VERSION ""

NS_ :

BS_ :

BU_ : ATX ECU EIC PBS PDC PDE PTP

BO_ 2565406464 Acknowledgment_ECU: 8 ECU

BO_ 2565406467 Acknowledgment_PBS: 8 PBS

BO_ 2565406706 Acknowledgment_PDC: 8 PDC

BO_ 2565406655 Acknowledgment_PDE: 8 PDE

BO_ 2565341952 Acknowledgment_TX_ECU_RX_PBS: 8 ECU

BO_ 2565403136 Acknowledgment_TX_ECU_RX_PDC: 8 ECU

BO_ 2565390080 Acknowledgment_TX_ECU_RX_PDE: 8 ECU

BO_ 2565341187 Acknowledgment_TX_PBS_RX_ECU: 8 PBS

BO_ 2565403139 Acknowledgment_TX_PBS_RX_PDC: 8 PBS

BO_ 2565390083 Acknowledgment_TX_PBS_RX_PDE: 8 PBS

BO_ 2565341955 Acknowledgment_TX_PBS_RX_PTP: 8 PBS

BO_ 2565341426 Acknowledgment_TX_PDC_RX_ECU: 8 PDC

BO_ 2565342194 Acknowledgment_TX_PDC_RX_PBS: 8 PDC

BO_ 2565390322 Acknowledgment_TX_PDC_RX_PDE: 8 PDC

BO_ 2565341375 Acknowledgment_TX_PDE_RX_ECU: 8 PDE

BO_ 2565342143 Acknowledgment_TX_PDE_RX_PBS: 8 PDE

BO_ 2565403327 Acknowledgment_TX_PDE_RX_PDC: 8 PDE

BO_ 2565799680 Address_Claimed_ECU: 8 ECU

BO_ 2565799683 Address_Claimed_PBS: 8 PBS

BO_ 2565799922 Address_Claimed_PDC: 8 PDC

BO_ 2565799871 Address_Claimed_PDE: 8 PDE

BO_ 2566757120 AfteDiesExhaFluiInfo_ECU: 8 ECU
 SG_ AftrtrtmntDEFConc : 8|8@1+ (0.25,0) [0|62.5] ""  Vector__XXX
 SG_ AftrtrtmntDEFProp : 40|4@1+ (1,0) [0|15] ""  Vector__XXX

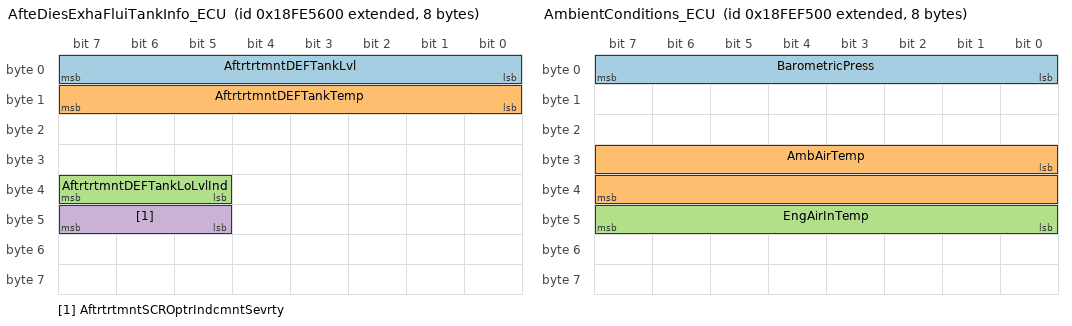
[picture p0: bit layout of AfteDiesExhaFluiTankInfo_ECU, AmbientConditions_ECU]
BO_ 2566804992 AfteDiesExhaFluiTankInfo_ECU: 8 ECU
 SG_ AftrtrtmntDEFTankLvl : 0|8@1+ (0.4,0) [0|100] ""  PDC
 SG_ AftrtrtmntDEFTankTemp : 8|8@1+ (1,-40) [-40|210] ""  Vector__XXX
 SG_ AftrtrtmntDEFTankLoLvlInd : 37|3@1+ (1,0) [0|7] ""  PDC
 SG_ AftrtrtmntSCROptrIndcmntSevrty : 45|3@1+ (1,0) [0|7] ""  EIC,PDC

BO_ 2566748928 Aftertreatment1Service_ECU: 8 ECU
 SG_ PartTrap1TimeSinceLastActReg : 16|32@1+ (1,0) [0|4211081215] ""  Vector__XXX

BO_ 2566763264 AftertreatmentOutletGas2_ECU: 8 ECU
 SG_ AftrDiesPartFltrOutlGasTemp : 16|16@1+ (0.03125,-273) [-273|1735] ""  Vector__XXX

BO_ 2566700288 AfteSCRServInfo2_ECU: 8 ECU
 SG_ AftrtrtmntTotalDEFUsed : 0|32@1+ (0.5,0) [0|2105540607.5] ""  Vector__XXX

BO_ 2565874432 AfteTreaSCRDosiSystInfo_ECU: 8 ECU
 SG_ AftrTrtmDiesExhsFldActDsngQty : 0|16@1+ (0.3,0) [0|19276.5] ""  Vector__XXX

BO_ 2566845696 AmbientConditions_ECU: 8 ECU
 SG_ BarometricPress : 0|8@1+ (0.5,0) [0|125] ""  PDC
 SG_ AmbAirTemp : 24|16@1+ (0.03125,-273) [-273|1735] "NoUnit3"  PDC
 SG_ EngAirInTemp : 40|8@1+ (1,-40) [-40|210] ""  PDC

BO_ 2564292352 Binary_Data_Transfer_ECU: 8 ECU

BO_ 2628387070 ClieECUtoFileServ_TX_Vector__XXX_RX_ECU: 8 Vector__XXX

BO_ 2628387838 ClieECUtoFileServ_TX_Vector__XXX_RX_PBS: 8 Vector__XXX

BO_ 2628449022 ClieECUtoFileServ_TX_Vector__XXX_RX_PDC: 8 Vector__XXX

BO_ 2628435966 ClieECUtoFileServ_TX_Vector__XXX_RX_PDE: 8 Vector__XXX

BO_ 2628452350 Client_ECU_to_File_Server_Vector__XXX: 8 Vector__XXX

BO_ 2566838272 Commanded_Address_ECU: 9 ECU

BO_ 2566838275 Commanded_Address_PBS: 9 PBS

BO_ 2566838514 Commanded_Address_PDC: 9 PDC

BO_ 2566838463 Commanded_Address_PDE: 9 PDE

BO_ 2298409219 CruiseControlVehicleSpeed_PBS: 8 PBS
 SG_ WheelBasedVehicleSpeed : 8|16@1+ (0.00390625,0) [0|250.996] "KiloMtrPerHr"  EIC,PDC
 SG_ BrakeSwitch : 28|2@1+ (1,0) [0|3] ""  PDC

BO_ 2566850816 DiagDeviIdenTLA_ECU: 8 ECU
 SG_ DIAGTLA : 0|24@1+ (1,0) [0|0] ""  PBS,PDC,PDE,PTP

BO_ 2566850819 DiagDeviIdenTLA_PBS: 8 PBS
 SG_ DIAGTLA : 0|24@1+ (1,0) [0|0] ""  ECU,PDC,PDE,PTP

BO_ 2566851058 DiagDeviIdenTLA_PDC: 8 PDC
 SG_ DIAGTLA : 0|24@1+ (1,0) [0|0] ""  ECU,PBS,PDE,PTP

BO_ 2566851007 DiagDeviIdenTLA_PDE: 8 PDE
 SG_ DIAGTLA : 0|24@1+ (1,0) [0|0] ""  ECU,PBS,PDC,PTP

BO_ 2566730243 Diagnostic_Protocol_PBS: 8 PBS

BO_ 2566730431 Diagnostic_Protocol_PDE: 8 PDE

BO_ 2562719507 Diagnostic_Window_Shade_ATX: 8 ATX

BO_ 2562719488 Diagnostic_Window_Shade_ECU: 8 ECU

BO_ 2562719491 Diagnostic_Window_Shade_PBS: 8 PBS

BO_ 2562719679 Diagnostic_Window_Shade_PDE: 8 PDE

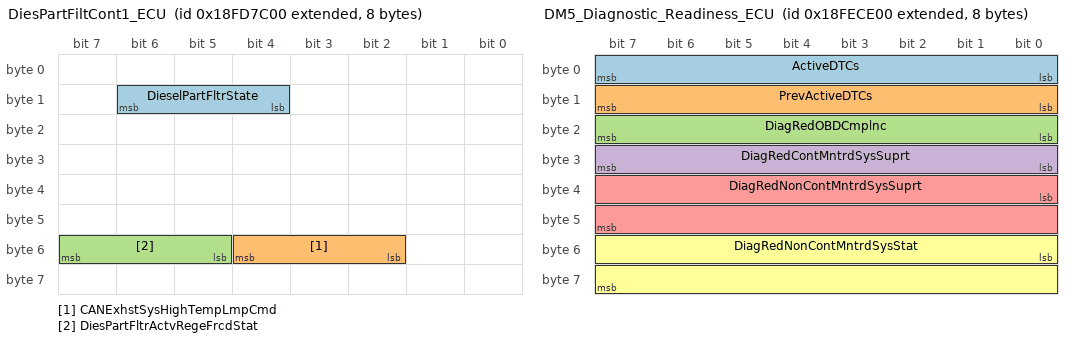
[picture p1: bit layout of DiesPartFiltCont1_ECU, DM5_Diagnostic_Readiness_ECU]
BO_ 2566749184 DiesPartFiltCont1_ECU: 8 ECU
 SG_ DieselPartFltrState : 12|3@1+ (1,0) [0|7] ""  EIC,PDC
 SG_ CANExhstSysHighTempLmpCmd : 50|3@1+ (1,0) [0|7] ""  Vector__XXX
 SG_ DiesPartFltrActvRegeFrcdStat : 53|3@1+ (1,0) [0|7] ""  EIC,PDC

BO_ 2566837011 DM11ClearResetofActiveDTCs_ATX: 8 ATX

BO_ 2566836992 DM11ClearResetofActiveDTCs_ECU: 8 ECU

BO_ 2566836995 DM11ClearResetofActiveDTCs_PBS: 8 PBS

BO_ 2566837234 DM11ClearResetofActiveDTCs_PDC: 8 PDC

BO_ 2566837183 DM11ClearResetofActiveDTCs_PDE: 8 PDE

BO_ 2564816894 DM13_StopStart_Broadcast_Vector__XXX: 8 Vector__XXX

BO_ 2566834707 DM1ActiDiagTrouCode_ATX: 6 ATX

BO_ 2566834688 DM1ActiDiagTrouCode_ECU: 6 ECU

BO_ 2566834691 DM1ActiDiagTrouCode_PBS: 6 PBS

BO_ 2566834879 DM1ActiDiagTrouCode_PDE: 6 PDE

BO_ 2566834963 DM2PrevActiDiagTrouCode_ATX: 6 ATX

BO_ 2566834944 DM2PrevActiDiagTrouCode_ECU: 6 ECU

BO_ 2566834947 DM2PrevActiDiagTrouCode_PBS: 6 PBS

BO_ 2566835135 DM2PrevActiDiagTrouCode_PDE: 6 PDE

BO_ 2566835219 DM3CleaResePrevActiDTCs_ATX: 8 ATX

BO_ 2566835200 DM3CleaResePrevActiDTCs_ECU: 8 ECU

BO_ 2566835203 DM3CleaResePrevActiDTCs_PBS: 8 PBS

BO_ 2566835442 DM3CleaResePrevActiDTCs_PDC: 8 PDC

BO_ 2566835391 DM3CleaResePrevActiDTCs_PDE: 8 PDE

BO_ 2566835456 DM4_Freeze_Frame_ECU: 14 ECU

BO_ 2566835459 DM4_Freeze_Frame_PBS: 14 PBS

BO_ 2566835712 DM5_Diagnostic_Readiness_ECU: 8 ECU
 SG_ ActiveDTCs : 0|8@1+ (1,0) [0|0] ""  Vector__XXX
 SG_ PrevActiveDTCs : 8|8@1+ (1,0) [0|0] ""  Vector__XXX
 SG_ DiagRedOBDCmplnc : 16|8@1+ (1,0) [0|0] ""  Vector__XXX
 SG_ DiagRedContMntrdSysSuprt : 24|8@1+ (1,0) [0|0] ""  Vector__XXX
 SG_ DiagRedNonContMntrdSysSuprt : 32|16@1+ (1,0) [0|0] ""  Vector__XXX
 SG_ DiagRedNonContMntrdSysStat : 48|16@1+ (1,0) [0|0] ""  Vector__XXX

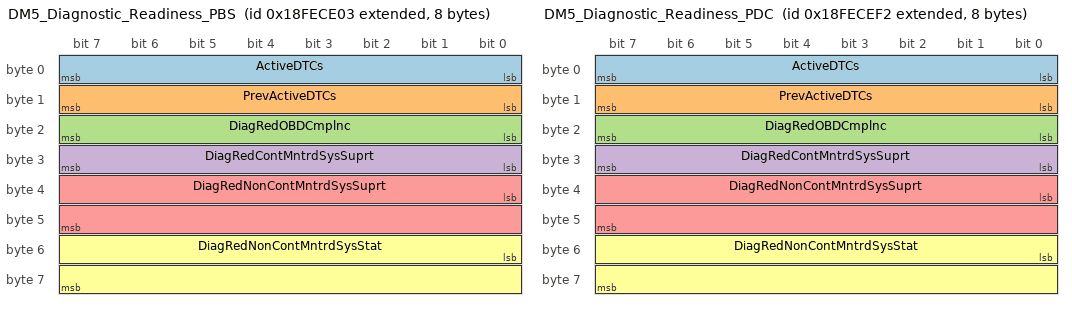
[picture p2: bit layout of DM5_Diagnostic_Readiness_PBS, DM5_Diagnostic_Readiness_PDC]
BO_ 2566835715 DM5_Diagnostic_Readiness_PBS: 8 PBS
 SG_ ActiveDTCs : 0|8@1+ (1,0) [0|0] ""  Vector__XXX
 SG_ PrevActiveDTCs : 8|8@1+ (1,0) [0|0] ""  Vector__XXX
 SG_ DiagRedOBDCmplnc : 16|8@1+ (1,0) [0|0] ""  Vector__XXX
 SG_ DiagRedContMntrdSysSuprt : 24|8@1+ (1,0) [0|0] ""  Vector__XXX
 SG_ DiagRedNonContMntrdSysSuprt : 32|16@1+ (1,0) [0|0] ""  Vector__XXX
 SG_ DiagRedNonContMntrdSysStat : 48|16@1+ (1,0) [0|0] ""  Vector__XXX

BO_ 2566835954 DM5_Diagnostic_Readiness_PDC: 8 PDC
 SG_ ActiveDTCs : 0|8@1+ (1,0) [0|0] ""  Vector__XXX
 SG_ PrevActiveDTCs : 8|8@1+ (1,0) [0|0] ""  Vector__XXX
 SG_ DiagRedOBDCmplnc : 16|8@1+ (1,0) [0|0] ""  Vector__XXX
 SG_ DiagRedContMntrdSysSuprt : 24|8@1+ (1,0) [0|0] ""  Vector__XXX
 SG_ DiagRedNonContMntrdSysSuprt : 32|16@1+ (1,0) [0|0] ""  Vector__XXX
 SG_ DiagRedNonContMntrdSysStat : 48|16@1+ (1,0) [0|0] ""  Vector__XXX

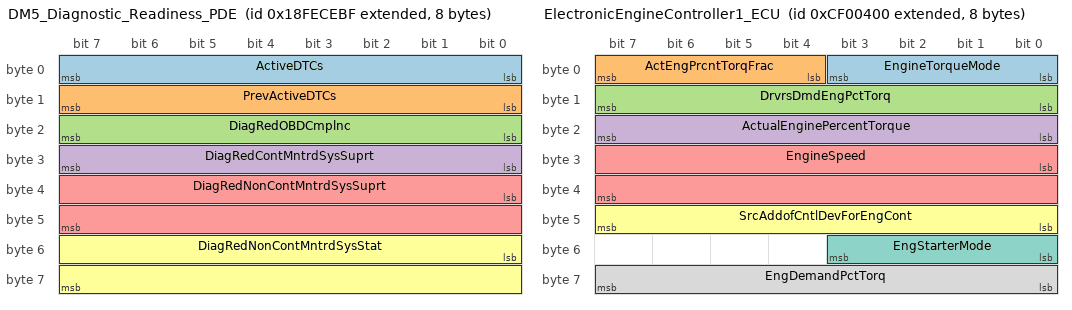
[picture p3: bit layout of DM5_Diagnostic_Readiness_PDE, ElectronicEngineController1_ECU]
BO_ 2566835903 DM5_Diagnostic_Readiness_PDE: 8 PDE
 SG_ ActiveDTCs : 0|8@1+ (1,0) [0|0] ""  Vector__XXX
 SG_ PrevActiveDTCs : 8|8@1+ (1,0) [0|0] ""  Vector__XXX
 SG_ DiagRedOBDCmplnc : 16|8@1+ (1,0) [0|0] ""  Vector__XXX
 SG_ DiagRedContMntrdSysSuprt : 24|8@1+ (1,0) [0|0] ""  Vector__XXX
 SG_ DiagRedNonContMntrdSysSuprt : 32|16@1+ (1,0) [0|0] ""  Vector__XXX
 SG_ DiagRedNonContMntrdSysStat : 48|16@1+ (1,0) [0|0] ""  Vector__XXX

BO_ 2566767872 ECUIdentificationInformation_ECU: 1 ECU

BO_ 2566767875 ECUIdentificationInformation_PBS: 1 PBS

BO_ 2566768114 ECUIdentificationInformation_PDC: 1 PDC

BO_ 2566768063 ECUIdentificationInformation_PDE: 1 PDE

BO_ 2565276416 ECUtoVirtTerm_TX_ECU_RX_PBS: 8 ECU

BO_ 2565337600 ECUtoVirtTerm_TX_ECU_RX_PDC: 8 ECU

BO_ 2565324544 ECUtoVirtTerm_TX_ECU_RX_PDE: 8 ECU

BO_ 2565275651 ECUtoVirtTerm_TX_PBS_RX_ECU: 8 PBS

BO_ 2565337603 ECUtoVirtTerm_TX_PBS_RX_PDC: 8 PBS

BO_ 2565324547 ECUtoVirtTerm_TX_PBS_RX_PDE: 8 PBS

BO_ 2565275890 ECUtoVirtTerm_TX_PDC_RX_ECU: 8 PDC

BO_ 2565276658 ECUtoVirtTerm_TX_PDC_RX_PBS: 8 PDC

BO_ 2565324786 ECUtoVirtTerm_TX_PDC_RX_PDE: 8 PDC

BO_ 2565275839 ECUtoVirtTerm_TX_PDE_RX_ECU: 8 PDE

BO_ 2565276607 ECUtoVirtTerm_TX_PDE_RX_PBS: 8 PDE

BO_ 2565337791 ECUtoVirtTerm_TX_PDE_RX_PDC: 8 PDE

BO_ 2565340928 ECUtoVirtual_Terminal_ECU: 8 ECU

BO_ 2565340931 ECUtoVirtual_Terminal_PBS: 8 PBS

BO_ 2565341170 ECUtoVirtual_Terminal_PDC: 8 PDC

BO_ 2565341119 ECUtoVirtual_Terminal_PDE: 8 PDE

BO_ 2364539904 ElectronicEngineController1_ECU: 8 ECU
 SG_ EngineTorqueMode : 0|4@1+ (1,0) [0|15] ""  PDC
 SG_ ActEngPrcntTorqFrac : 4|4@1+ (0.125,0) [0|1.625] ""  PDC
 SG_ DrvrsDmdEngPctTorq : 8|8@1+ (1,-125) [0|0] ""  PDC
 SG_ ActualEnginePercentTorque : 16|8@1+ (1,-125) [0|0] ""  PDC
 SG_ EngineSpeed : 24|16@1+ (0.125,0) [0|8031.875] ""  EIC,PBS,PDC,PTP
 SG_ SrcAddofCntlDevForEngCont : 40|8@1+ (1,0) [0|255] ""  PDC
 SG_ EngStarterMode : 48|4@1+ (1,0) [0|15] ""  PDC
 SG_ EngDemandPctTorq : 56|8@1+ (1,-125) [0|0] ""  PDC

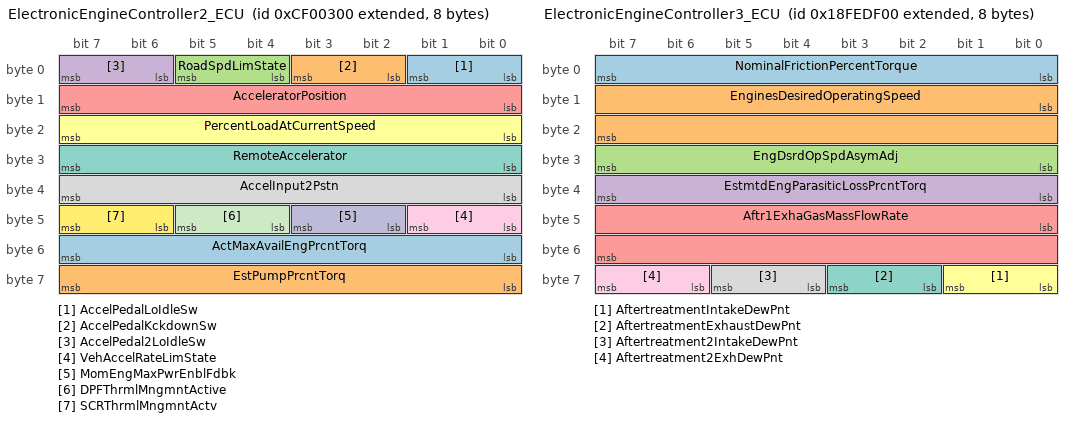
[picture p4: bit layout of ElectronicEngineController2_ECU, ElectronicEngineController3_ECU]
BO_ 2364539648 ElectronicEngineController2_ECU: 8 ECU
 SG_ AccelPedalLoIdleSw : 0|2@1+ (1,0) [0|3] ""  Vector__XXX
 SG_ AccelPedalKckdownSw : 2|2@1+ (1,0) [0|3] ""  Vector__XXX
 SG_ RoadSpdLimState : 4|2@1+ (1,0) [0|3] ""  Vector__XXX
 SG_ AccelPedal2LoIdleSw : 6|2@1+ (1,0) [0|3] ""  Vector__XXX
 SG_ AcceleratorPosition : 8|8@1+ (0.4,0) [0|100] ""  Vector__XXX
 SG_ PercentLoadAtCurrentSpeed : 16|8@1+ (1,0) [0|250] ""  EIC,PDC
 SG_ RemoteAccelerator : 24|8@1+ (0.4,0) [0|100] ""  Vector__XXX
 SG_ AccelInput2Pstn : 32|8@1+ (0.4,0) [0|100] ""  Vector__XXX
 SG_ VehAccelRateLimState : 40|2@1+ (1,0) [0|3] ""  Vector__XXX
 SG_ MomEngMaxPwrEnblFdbk : 42|2@1+ (1,0) [0|3] ""  Vector__XXX
 SG_ DPFThrmlMngmntActive : 44|2@1+ (1,0) [0|3] ""  Vector__XXX
 SG_ SCRThrmlMngmntActv : 46|2@1+ (1,0) [0|3] ""  Vector__XXX
 SG_ ActMaxAvailEngPrcntTorq : 48|8@1+ (0.4,0) [0|100] ""  Vector__XXX
 SG_ EstPumpPrcntTorq : 56|8@1+ (1,-125) [0|0] ""  Vector__XXX

BO_ 2566840064 ElectronicEngineController3_ECU: 8 ECU
 SG_ NominalFrictionPercentTorque : 0|8@1+ (1,-125) [-125|125] ""  EIC
 SG_ EnginesDesiredOperatingSpeed : 8|16@1+ (0.125,0) [0|8031.875] ""  PDC,PTP
 SG_ EngDsrdOpSpdAsymAdj : 24|8@1+ (1,0) [0|250] ""  Vector__XXX
 SG_ EstmtdEngParasiticLossPrcntTorq : 32|8@1+ (1,-125) [0|0] ""  Vector__XXX
 SG_ Aftr1ExhaGasMassFlowRate : 40|16@1+ (0.2,0) [0|12851] ""  Vector__XXX
 SG_ AftertreatmentIntakeDewPnt : 56|2@1+ (1,0) [0|3] ""  Vector__XXX
 SG_ AftertreatmentExhaustDewPnt : 58|2@1+ (1,0) [0|3] ""  Vector__XXX
 SG_ Aftertreatment2IntakeDewPnt : 60|2@1+ (1,0) [0|3] ""  Vector__XXX
 SG_ Aftertreatment2ExhDewPnt : 62|2@1+ (1,0) [0|3] ""  Vector__XXX

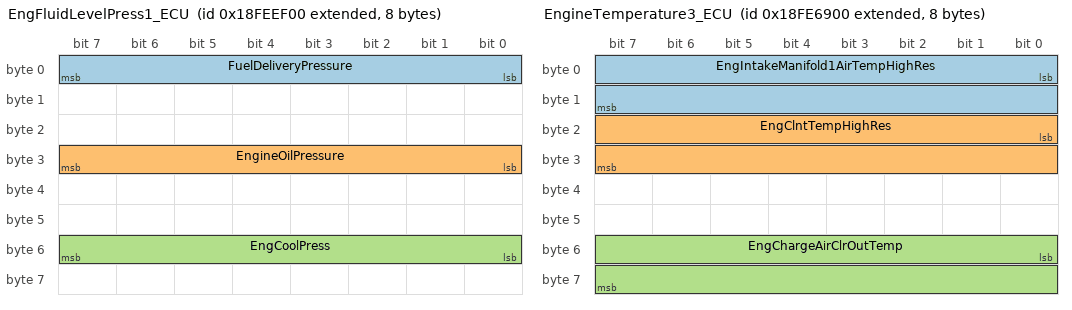
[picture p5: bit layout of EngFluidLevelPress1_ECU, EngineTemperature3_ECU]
BO_ 2566844160 EngFluidLevelPress1_ECU: 8 ECU
 SG_ FuelDeliveryPressure : 0|8@1+ (4,0) [0|1000] "KiloPa"  Vector__XXX
 SG_ EngineOilPressure : 24|8@1+ (4,0) [0|1000] "KiloPa"  Vector__XXX
 SG_ EngCoolPress : 48|8@1+ (2,0) [0|500] "KiloPa"  Vector__XXX

BO_ 2566841088 Engine_Configuration_ECU: 40 ECU
 SG_ ReferenceEngineTorque : 152|16@1+ (1,0) [0|64255] "NewtonMeter"  EIC

BO_ 2566841600 Engine_Hours_Revolutions_ECU: 8 ECU
 SG_ EngineHours : 0|32@1+ (0.05,0) [0|210554060.75] ""  PBS,PDC,PDE,PTP

BO_ 2566843904 Engine_Temperature_ECU: 8 ECU
 SG_ EngineCoolantTemperature : 0|8@1+ (1,-40) [-40|210] ""  PDC
 SG_ FuelTemperature : 8|8@1+ (1,-40) [-40|210] ""  PDC

BO_ 2432537342 EngineOperatingInformation_Vector__XXX: 8 Vector__XXX
 SG_ EngOpState : 0|4@1+ (1,0) [0|15] ""  PBS

BO_ 2431708670 EngineStartControlConsent_Vector__XXX: 8 Vector__XXX
 SG_ EngineStartRequest : 0|2@1+ (1,0) [0|3] ""  ECU

BO_ 2566809856 EngineTemperature3_ECU: 8 ECU
 SG_ EngIntakeManifold1AirTempHighRes : 0|16@1+ (0.03125,-273) [-273|1735] ""  PDC
 SG_ EngClntTempHighRes : 16|16@1+ (0.03125,-273) [-273|1735] ""  PDC
 SG_ EngChargeAirClrOutTemp : 48|16@1+ (0.03125,-273) [-273|1735] ""  PDC

BO_ 2563309331 ExteTranProtConnMana_ATX: 8 ATX

BO_ 2563309312 ExteTranProtConnMana_ECU: 8 ECU

BO_ 2563309315 ExteTranProtConnMana_PBS: 8 PBS

BO_ 2563309554 ExteTranProtConnMana_PDC: 8 PDC

BO_ 2563309503 ExteTranProtConnMana_PDE: 8 PDE

BO_ 2563244051 ExteTranProtConnMana_TX_ATX_RX_ECU: 8 ATX

BO_ 2563244819 ExteTranProtConnMana_TX_ATX_RX_PBS: 8 ATX

BO_ 2563306003 ExteTranProtConnMana_TX_ATX_RX_PDC: 8 ATX

BO_ 2563292947 ExteTranProtConnMana_TX_ATX_RX_PDE: 8 ATX

BO_ 2563248896 ExteTranProtConnMana_TX_ECU_RX_ATX: 8 ECU

BO_ 2563244800 ExteTranProtConnMana_TX_ECU_RX_PBS: 8 ECU

BO_ 2563305984 ExteTranProtConnMana_TX_ECU_RX_PDC: 8 ECU

BO_ 2563292928 ExteTranProtConnMana_TX_ECU_RX_PDE: 8 ECU

BO_ 2563248899 ExteTranProtConnMana_TX_PBS_RX_ATX: 8 PBS

BO_ 2563244035 ExteTranProtConnMana_TX_PBS_RX_ECU: 8 PBS

BO_ 2563305987 ExteTranProtConnMana_TX_PBS_RX_PDC: 8 PBS

BO_ 2563292931 ExteTranProtConnMana_TX_PBS_RX_PDE: 8 PBS

BO_ 2563244803 ExteTranProtConnMana_TX_PBS_RX_PTP: 8 PBS

BO_ 2563249138 ExteTranProtConnMana_TX_PDC_RX_ATX: 8 PDC

BO_ 2563244274 ExteTranProtConnMana_TX_PDC_RX_ECU: 8 PDC

BO_ 2563245042 ExteTranProtConnMana_TX_PDC_RX_PBS: 8 PDC

BO_ 2563293170 ExteTranProtConnMana_TX_PDC_RX_PDE: 8 PDC

BO_ 2563249087 ExteTranProtConnMana_TX_PDE_RX_ATX: 8 PDE

BO_ 2563244223 ExteTranProtConnMana_TX_PDE_RX_ECU: 8 PDE

BO_ 2563244991 ExteTranProtConnMana_TX_PDE_RX_PBS: 8 PDE

BO_ 2563306175 ExteTranProtConnMana_TX_PDE_RX_PDC: 8 PDE

BO_ 2563243795 ExteTranProtDataTran_ATX: 8 ATX

BO_ 2563243776 ExteTranProtDataTran_ECU: 8 ECU

BO_ 2563243779 ExteTranProtDataTran_PBS: 8 PBS

BO_ 2563244018 ExteTranProtDataTran_PDC: 8 PDC

BO_ 2563243967 ExteTranProtDataTran_PDE: 8 PDE

BO_ 2563178515 ExteTranProtDataTran_TX_ATX_RX_ECU: 8 ATX

BO_ 2563179283 ExteTranProtDataTran_TX_ATX_RX_PBS: 8 ATX

BO_ 2563240467 ExteTranProtDataTran_TX_ATX_RX_PDC: 8 ATX

BO_ 2563227411 ExteTranProtDataTran_TX_ATX_RX_PDE: 8 ATX

BO_ 2563183360 ExteTranProtDataTran_TX_ECU_RX_ATX: 8 ECU

BO_ 2563179264 ExteTranProtDataTran_TX_ECU_RX_PBS: 8 ECU

BO_ 2563240448 ExteTranProtDataTran_TX_ECU_RX_PDC: 8 ECU

BO_ 2563227392 ExteTranProtDataTran_TX_ECU_RX_PDE: 8 ECU

BO_ 2563183363 ExteTranProtDataTran_TX_PBS_RX_ATX: 8 PBS

BO_ 2563178499 ExteTranProtDataTran_TX_PBS_RX_ECU: 8 PBS

BO_ 2563240451 ExteTranProtDataTran_TX_PBS_RX_PDC: 8 PBS

BO_ 2563227395 ExteTranProtDataTran_TX_PBS_RX_PDE: 8 PBS

BO_ 2563179267 ExteTranProtDataTran_TX_PBS_RX_PTP: 8 PBS

BO_ 2563183602 ExteTranProtDataTran_TX_PDC_RX_ATX: 8 PDC

BO_ 2563178738 ExteTranProtDataTran_TX_PDC_RX_ECU: 8 PDC

BO_ 2563179506 ExteTranProtDataTran_TX_PDC_RX_PBS: 8 PDC

BO_ 2563227634 ExteTranProtDataTran_TX_PDC_RX_PDE: 8 PDC

BO_ 2563183551 ExteTranProtDataTran_TX_PDE_RX_ATX: 8 PDE

BO_ 2563178687 ExteTranProtDataTran_TX_PDE_RX_ECU: 8 PDE

BO_ 2563179455 ExteTranProtDataTran_TX_PDE_RX_PBS: 8 PDE

BO_ 2563240639 ExteTranProtDataTran_TX_PDE_RX_PDC: 8 PDE

BO_ 2628517632 File_Server_to_Client_ECU_ECU: 8 ECU

BO_ 2628517635 File_Server_to_Client_ECU_PBS: 8 PBS

BO_ 2628517874 File_Server_to_Client_ECU_PDC: 8 PDC

BO_ 2628517823 File_Server_to_Client_ECU_PDE: 8 PDE

BO_ 2628453120 FileServClieECU_TX_ECU_RX_PBS: 8 ECU

BO_ 2628514304 FileServClieECU_TX_ECU_RX_PDC: 8 ECU

BO_ 2628501248 FileServClieECU_TX_ECU_RX_PDE: 8 ECU

BO_ 2628452355 FileServClieECU_TX_PBS_RX_ECU: 8 PBS

BO_ 2628514307 FileServClieECU_TX_PBS_RX_PDC: 8 PBS

BO_ 2628501251 FileServClieECU_TX_PBS_RX_PDE: 8 PBS

BO_ 2628452594 FileServClieECU_TX_PDC_RX_ECU: 8 PDC

BO_ 2628453362 FileServClieECU_TX_PDC_RX_PBS: 8 PDC

BO_ 2628501490 FileServClieECU_TX_PDC_RX_PDE: 8 PDC

BO_ 2628452543 FileServClieECU_TX_PDE_RX_ECU: 8 PDE

BO_ 2628453311 FileServClieECU_TX_PDE_RX_PBS: 8 PDE

BO_ 2628514495 FileServClieECU_TX_PDE_RX_PDC: 8 PDE

BO_ 2566842624 FuelConsumption_ECU: 8 ECU
 SG_ TotalFuelUsed : 32|32@1+ (0.5,0) [0|2105540607.5] "Litre"  PDC

BO_ 2566844928 FuelEconomyLiq_ECU: 8 ECU
 SG_ EngFuelRate : 0|16@1+ (0.05,0) [0|0] "LPerHr"  PDC

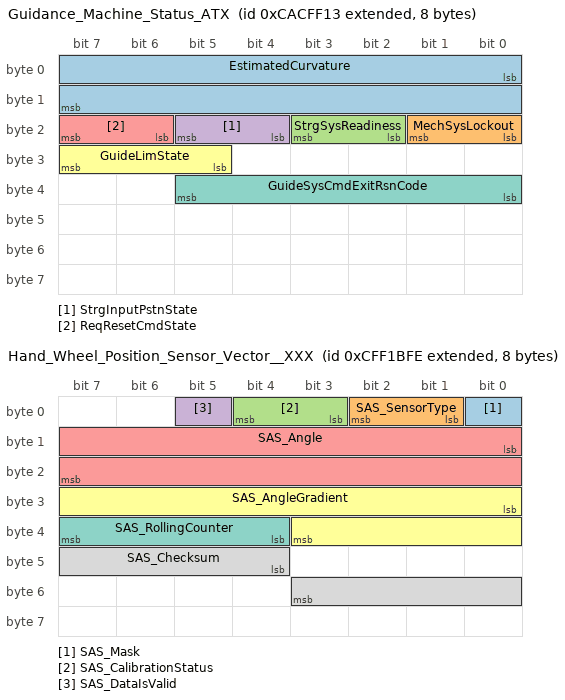
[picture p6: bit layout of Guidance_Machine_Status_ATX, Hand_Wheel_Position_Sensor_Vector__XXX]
BO_ 2360147731 Guidance_Machine_Status_ATX: 8 ATX
 SG_ EstimatedCurvature : 0|16@1+ (0.25,-8032) [-8032|8031.75] "rad/km"  Vector__XXX
 SG_ MechSysLockout : 16|2@1+ (1,0) [0|3] ""  Vector__XXX
 SG_ StrgSysReadiness : 18|2@1+ (1,0) [0|3] ""  Vector__XXX
 SG_ StrgInputPstnState : 20|2@1+ (1,0) [0|3] ""  Vector__XXX
 SG_ ReqResetCmdState : 22|2@1+ (1,0) [0|3] ""  Vector__XXX
 SG_ GuideLimState : 29|3@1+ (1,0) [0|7] ""  Vector__XXX
 SG_ GuideSysCmdExitRsnCode : 32|6@1+ (1,0) [0|63] ""  Vector__XXX

BO_ 2360213502 Guidance_System_Command_Vector__XXX: 8 Vector__XXX
 SG_ CurvCmd : 0|16@1+ (0.25,-8032) [-8032|8031.75] "rad/km"  ATX
 SG_ CurvatureCmdState : 16|2@1+ (1,0) [0|3] ""  ATX

BO_ 2365529086 Hand_Wheel_Position_Sensor_Vector__XXX: 8 Vector__XXX
 SG_ SAS_Mask : 0|1@1+ (1,0) [0|1] ""  ATX
 SG_ SAS_SensorType : 1|2@1+ (1,0) [0|3] ""  ATX
 SG_ SAS_CalibrationStatus : 3|2@1+ (1,0) [0|3] ""  ATX
 SG_ SAS_DataIsValid : 5|1@1+ (1,0) [0|1] ""  ATX
 SG_ SAS_Angle : 8|16@1+ (0.0625,-2048) [-2048|2047] "deg"  ATX
 SG_ SAS_AngleGradient : 24|12@1+ (1,0) [0|0] ""  ATX
 SG_ SAS_RollingCounter : 36|4@1+ (1,0) [0|15] "Count"  ATX
 SG_ SAS_Checksum : 44|8@1+ (1,0) [0|255] "Count"  ATX

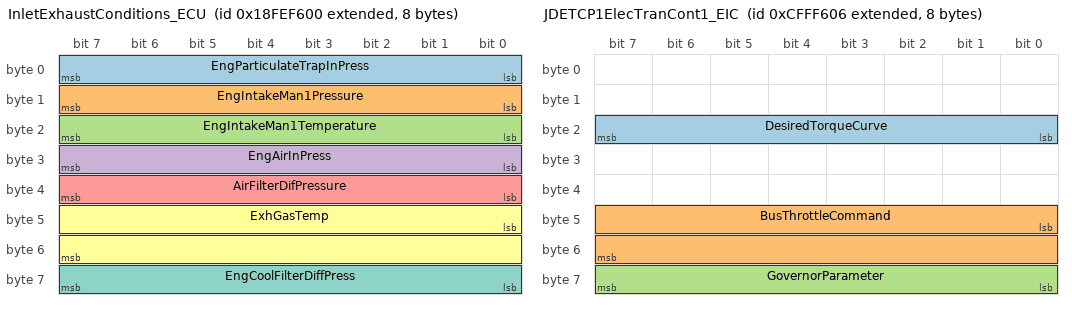
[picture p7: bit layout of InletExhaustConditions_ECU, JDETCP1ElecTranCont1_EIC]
BO_ 2566845952 InletExhaustConditions_ECU: 8 ECU
 SG_ EngParticulateTrapInPress : 0|8@1+ (0.5,0) [0|125] ""  Vector__XXX
 SG_ EngIntakeMan1Pressure : 8|8@1+ (1,-32000) [-32000|255] ""  Vector__XXX
 SG_ EngIntakeMan1Temperature : 16|8@1+ (1,-32000) [-32000|255] ""  Vector__XXX
 SG_ EngAirInPress : 24|8@1+ (2,0) [0|500] ""  Vector__XXX
 SG_ AirFilterDifPressure : 32|8@1+ (0.05,0) [0|12.5] "kPa"  Vector__XXX
 SG_ ExhGasTemp : 40|16@1+ (0.03125,-273) [0|0] ""  Vector__XXX
 SG_ EngCoolFilterDiffPress : 56|8@1+ (0.5,0) [0|125] ""  Vector__XXX

BO_ 2173485042 IOExteCommTxObje_TX_PDC_RX_PDE: 8 PDC
 SG_ IOExtender_CRO_DatParms : 0|64@1+ (1,0) [0|0] ""  PDE

BO_ 2173432511 IOExteDataRxObje_TX_PDE_RX_PDC: 8 PDE
 SG_ IOExtender_DTO_DatParms : 0|64@1+ (1,0) [0|0] ""  PDC

BO_ 2173501426 IOExtender_Command_Tx_Object_PDC: 8 PDC
 SG_ IOExtender_CRO_DatParms : 0|64@1+ (1,0) [0|0] ""  PDE

BO_ 2173435839 IOExtender_Data_Rx_Object_PDE: 8 PDE
 SG_ IOExtender_DTO_DatParms : 0|64@1+ (1,0) [0|0] ""  PDC

BO_ 2566734339 ISOBUSCompCert_PBS: 8 PBS

BO_ 2566734527 ISOBUSCompCert_PDE: 8 PDE

BO_ 2566877952 JD_Product_Identification_ECU: 8 ECU

BO_ 2566877955 JD_Product_Identification_PBS: 8 PBS

BO_ 2566878194 JD_Product_Identification_PDC: 8 PDC

BO_ 2566878143 JD_Product_Identification_PDE: 8 PDE

BO_ 2365584902 JDETCP1ElecTranCont1_EIC: 8 EIC
 SG_ DesiredTorqueCurve : 16|8@1+ (1,0) [0|250] "Count"  ECU
 SG_ BusThrottleCommand : 40|16@1+ (3.052E-05,0) [0|100] ""  ECU
 SG_ GovernorParameter : 56|8@1+ (1,0) [0|250] "Count"  ECU

BO_ 2566786816 Language_Command_ECU: 8 ECU

BO_ 2566786819 Language_Command_PBS: 8 PBS

BO_ 2566787058 Language_Command_PDC: 8 PDC

BO_ 2566787007 Language_Command_PDE: 8 PDE

BO_ 2566801152 Maintain_Power_ECU: 8 ECU
 SG_ MaintainECUPower : 6|2@1+ (1,0) [0|3] ""  PDC

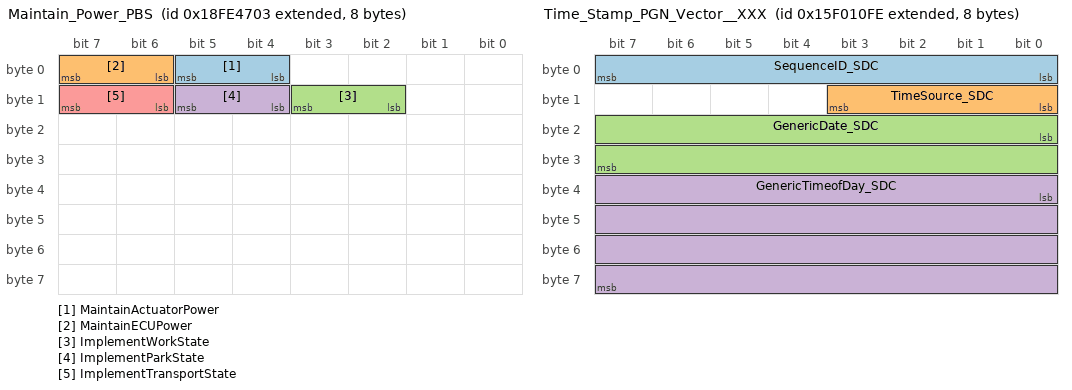
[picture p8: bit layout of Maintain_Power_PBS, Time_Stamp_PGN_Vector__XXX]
BO_ 2566801155 Maintain_Power_PBS: 8 PBS
 SG_ MaintainActuatorPower : 4|2@1+ (1,0) [0|3] ""  Vector__XXX
 SG_ MaintainECUPower : 6|2@1+ (1,0) [0|3] ""  PDC
 SG_ ImplementWorkState : 10|2@1+ (1,0) [0|3] ""  Vector__XXX
 SG_ ImplementParkState : 12|2@1+ (1,0) [0|3] ""  Vector__XXX
 SG_ ImplementTransportState : 14|2@1+ (1,0) [0|3] ""  Vector__XXX

BO_ 2564423443 Memory_Access_Request_ATX: 8 ATX

BO_ 2564423424 Memory_Access_Request_ECU: 8 ECU

BO_ 2564423427 Memory_Access_Request_PBS: 8 PBS

BO_ 2564423666 Memory_Access_Request_PDC: 8 PDC

BO_ 2564423615 Memory_Access_Request_PDE: 8 PDE

BO_ 2564357907 Memory_Access_Response_ATX: 8 ATX

BO_ 2564357891 Memory_Access_Response_PBS: 8 PBS

BO_ 2564358130 Memory_Access_Response_PDC: 8 PDC

BO_ 2564358079 Memory_Access_Response_PDE: 8 PDE

BO_ 2362179328 Process_Data_Message_ECU: 8 ECU

BO_ 2362179331 Process_Data_Message_PBS: 8 PBS

BO_ 2362179570 Process_Data_Message_PDC: 8 PDC

BO_ 2362179519 Process_Data_Message_PDE: 8 PDE

BO_ 2566688003 ProdIdenInfo_PBS: 8 PBS

BO_ 2566688191 ProdIdenInfo_PDE: 8 PDE

BO_ 2563374848 Request_2_ECU: 8 ECU

BO_ 2563374851 Request_2_PBS: 8 PBS

BO_ 2563375090 Request_2_PDC: 8 PDC

BO_ 2563375039 Request_2_PDE: 8 PDE

BO_ 2563310336 Request_2_TX_ECU_RX_PBS: 8 ECU

BO_ 2563371520 Request_2_TX_ECU_RX_PDC: 8 ECU

BO_ 2563358464 Request_2_TX_ECU_RX_PDE: 8 ECU

BO_ 2563309571 Request_2_TX_PBS_RX_ECU: 8 PBS

BO_ 2563371523 Request_2_TX_PBS_RX_PDC: 8 PBS

BO_ 2563358467 Request_2_TX_PBS_RX_PDE: 8 PBS

BO_ 2563310339 Request_2_TX_PBS_RX_PTP: 8 PBS

BO_ 2563309810 Request_2_TX_PDC_RX_ECU: 8 PDC

BO_ 2563310578 Request_2_TX_PDC_RX_PBS: 8 PDC

BO_ 2563358706 Request_2_TX_PDC_RX_PDE: 8 PDC

BO_ 2563309759 Request_2_TX_PDE_RX_ECU: 8 PDE

BO_ 2563310527 Request_2_TX_PDE_RX_PBS: 8 PDE

BO_ 2563371711 Request_2_TX_PDE_RX_PDC: 8 PDE

BO_ 2565537555 Request_PGN_ATX: 3 ATX

BO_ 2565537536 Request_PGN_ECU: 3 ECU

BO_ 2565537539 Request_PGN_PBS: 3 PBS

BO_ 2565537778 Request_PGN_PDC: 3 PDC

BO_ 2565537727 Request_PGN_PDE: 3 PDE

BO_ 2358116096 SequContClieSequContMast_ECU: 8 ECU

BO_ 2358116099 SequContClieSequContMast_PBS: 8 PBS

BO_ 2358116338 SequContClieSequContMast_PDC: 8 PDC

BO_ 2358116287 SequContClieSequContMast_PDE: 8 PDE

BO_ 2358051584 SequContClieSequContMast_TX_ECU_RX_PBS: 8 ECU

BO_ 2358112768 SequContClieSequContMast_TX_ECU_RX_PDC: 8 ECU

BO_ 2358099712 SequContClieSequContMast_TX_ECU_RX_PDE: 8 ECU

BO_ 2358050819 SequContClieSequContMast_TX_PBS_RX_ECU: 8 PBS

BO_ 2358112771 SequContClieSequContMast_TX_PBS_RX_PDC: 8 PBS

BO_ 2358099715 SequContClieSequContMast_TX_PBS_RX_PDE: 8 PBS

BO_ 2358051058 SequContClieSequContMast_TX_PDC_RX_ECU: 8 PDC

BO_ 2358051826 SequContClieSequContMast_TX_PDC_RX_PBS: 8 PDC

BO_ 2358099954 SequContClieSequContMast_TX_PDC_RX_PDE: 8 PDC

BO_ 2358051007 SequContClieSequContMast_TX_PDE_RX_ECU: 8 PDE

BO_ 2358051775 SequContClieSequContMast_TX_PDE_RX_PBS: 8 PDE

BO_ 2358112959 SequContClieSequContMast_TX_PDE_RX_PDC: 8 PDE

BO_ 2358181632 SequContMastSequContClie_ECU: 8 ECU

BO_ 2358181635 SequContMastSequContClie_PBS: 8 PBS

BO_ 2358181823 SequContMastSequContClie_PDE: 8 PDE

BO_ 2358117120 SequContMastSequContClie_TX_ECU_RX_PBS: 8 ECU

BO_ 2358165248 SequContMastSequContClie_TX_ECU_RX_PDE: 8 ECU

BO_ 2358116355 SequContMastSequContClie_TX_PBS_RX_ECU: 8 PBS

BO_ 2358165251 SequContMastSequContClie_TX_PBS_RX_PDE: 8 PBS

BO_ 2358116543 SequContMastSequContClie_TX_PDE_RX_ECU: 8 PDE

BO_ 2358117311 SequContMastSequContClie_TX_PDE_RX_PBS: 8 PDE

BO_ 2566838784 Software_Identification_ECU: 3 ECU

BO_ 2566838787 Software_Identification_PBS: 3 PBS

BO_ 2566839026 Software_Identification_PDC: 3 PDC

BO_ 2566838975 Software_Identification_PDE: 3 PDE

BO_ 2515538174 Time_Stamp_PGN_Vector__XXX: 8 Vector__XXX
 SG_ SequenceID_SDC : 0|8@1+ (1,0) [0|255] "Count"  EIC,PDC
 SG_ TimeSource_SDC : 8|4@1+ (1,0) [0|15] ""  EIC,PDC
 SG_ GenericDate_SDC : 16|16@1+ (1,0) [0|0] "day"  EIC,PDC
 SG_ GenericTimeofDay_SDC : 32|32@1+ (0.0001,0) [0|86401] "s"  EIC,PDC

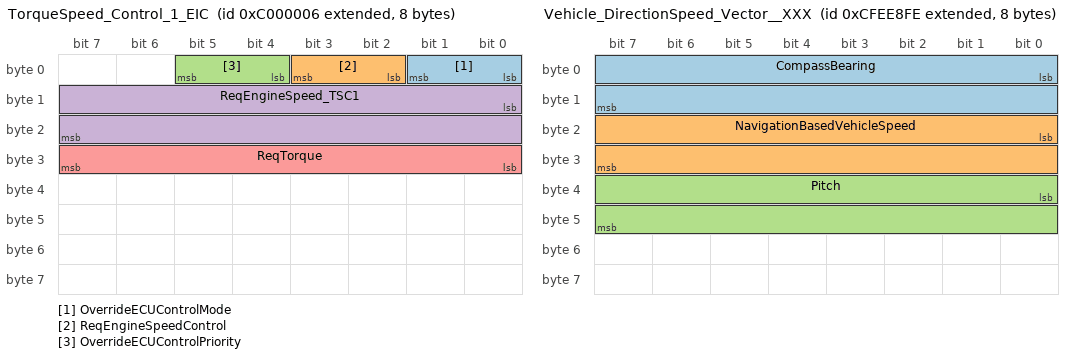
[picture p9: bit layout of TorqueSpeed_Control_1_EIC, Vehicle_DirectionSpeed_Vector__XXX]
BO_ 2348810246 TorqueSpeed_Control_1_EIC: 8 EIC
 SG_ OverrideECUControlMode : 0|2@1+ (1,0) [0|3] ""  ECU
 SG_ ReqEngineSpeedControl : 2|2@1+ (1,0) [0|3] ""  ECU
 SG_ OverrideECUControlPriority : 4|2@1+ (1,0) [0|3] ""  ECU
 SG_ ReqEngineSpeed_TSC1 : 8|16@1+ (0.125,0) [0|8031.875] "RPM"  ECU
 SG_ ReqTorque : 24|8@1+ (1,0) [0|0] ""  ECU

BO_ 2632777491 TranProtConnMana_ATX: 8 ATX

BO_ 2632777472 TranProtConnMana_ECU: 8 ECU

BO_ 2632777475 TranProtConnMana_PBS: 8 PBS

BO_ 2632777714 TranProtConnMana_PDC: 8 PDC

BO_ 2632777663 TranProtConnMana_PDE: 8 PDE

BO_ 2632711955 TranProtDataTran_ATX: 8 ATX

BO_ 2632711936 TranProtDataTran_ECU: 8 ECU

BO_ 2632711939 TranProtDataTran_PBS: 8 PBS

BO_ 2632712178 TranProtDataTran_PDC: 8 PDC

BO_ 2632712127 TranProtDataTran_PDE: 8 PDE

BO_ 2564489235 UDSFuncRequResp_TX_ATX_RX_ECU: 6 ATX

BO_ 2564490003 UDSFuncRequResp_TX_ATX_RX_PBS: 6 ATX

BO_ 2564551187 UDSFuncRequResp_TX_ATX_RX_PDC: 6 ATX

BO_ 2564538131 UDSFuncRequResp_TX_ATX_RX_PDE: 6 ATX

BO_ 2564494080 UDSFuncRequResp_TX_ECU_RX_ATX: 6 ECU

BO_ 2564489984 UDSFuncRequResp_TX_ECU_RX_PBS: 6 ECU

BO_ 2564551168 UDSFuncRequResp_TX_ECU_RX_PDC: 6 ECU

BO_ 2564538112 UDSFuncRequResp_TX_ECU_RX_PDE: 6 ECU

BO_ 2564494083 UDSFuncRequResp_TX_PBS_RX_ATX: 6 PBS

BO_ 2564489219 UDSFuncRequResp_TX_PBS_RX_ECU: 6 PBS

BO_ 2564551171 UDSFuncRequResp_TX_PBS_RX_PDC: 6 PBS

BO_ 2564538115 UDSFuncRequResp_TX_PBS_RX_PDE: 6 PBS

BO_ 2564489987 UDSFuncRequResp_TX_PBS_RX_PTP: 6 PBS

BO_ 2564494322 UDSFuncRequResp_TX_PDC_RX_ATX: 6 PDC

BO_ 2564489458 UDSFuncRequResp_TX_PDC_RX_ECU: 6 PDC

BO_ 2564490226 UDSFuncRequResp_TX_PDC_RX_PBS: 6 PDC

BO_ 2564538354 UDSFuncRequResp_TX_PDC_RX_PDE: 6 PDC

BO_ 2564494271 UDSFuncRequResp_TX_PDE_RX_ATX: 6 PDE

BO_ 2564489407 UDSFuncRequResp_TX_PDE_RX_ECU: 6 PDE

BO_ 2564490175 UDSFuncRequResp_TX_PDE_RX_PBS: 6 PDE

BO_ 2564551359 UDSFuncRequResp_TX_PDE_RX_PDC: 6 PDE

BO_ 2564554515 UDSFunctionalRequestResponse_ATX: 6 ATX

BO_ 2564554496 UDSFunctionalRequestResponse_ECU: 6 ECU

BO_ 2564554499 UDSFunctionalRequestResponse_PBS: 6 PBS

BO_ 2564554738 UDSFunctionalRequestResponse_PDC: 6 PDC

BO_ 2564554687 UDSFunctionalRequestResponse_PDE: 6 PDE

BO_ 2564488979 UDSPhysicalRequestResponse_ATX: 6 ATX

BO_ 2564488960 UDSPhysicalRequestResponse_ECU: 6 ECU

BO_ 2564488963 UDSPhysicalRequestResponse_PBS: 6 PBS

BO_ 2564489202 UDSPhysicalRequestResponse_PDC: 6 PDC

BO_ 2564489151 UDSPhysicalRequestResponse_PDE: 6 PDE

BO_ 2564423699 UDSPhysRequResp_TX_ATX_RX_ECU: 6 ATX

BO_ 2564424467 UDSPhysRequResp_TX_ATX_RX_PBS: 6 ATX

BO_ 2564485651 UDSPhysRequResp_TX_ATX_RX_PDC: 6 ATX

BO_ 2564472595 UDSPhysRequResp_TX_ATX_RX_PDE: 6 ATX

BO_ 2564428544 UDSPhysRequResp_TX_ECU_RX_ATX: 6 ECU

BO_ 2564424448 UDSPhysRequResp_TX_ECU_RX_PBS: 6 ECU

BO_ 2564485632 UDSPhysRequResp_TX_ECU_RX_PDC: 6 ECU

BO_ 2564472576 UDSPhysRequResp_TX_ECU_RX_PDE: 6 ECU

BO_ 2564428547 UDSPhysRequResp_TX_PBS_RX_ATX: 6 PBS

BO_ 2564423683 UDSPhysRequResp_TX_PBS_RX_ECU: 6 PBS

BO_ 2564485635 UDSPhysRequResp_TX_PBS_RX_PDC: 6 PBS

BO_ 2564472579 UDSPhysRequResp_TX_PBS_RX_PDE: 6 PBS

BO_ 2564424451 UDSPhysRequResp_TX_PBS_RX_PTP: 6 PBS

BO_ 2564428786 UDSPhysRequResp_TX_PDC_RX_ATX: 6 PDC

BO_ 2564423922 UDSPhysRequResp_TX_PDC_RX_ECU: 6 PDC

BO_ 2564424690 UDSPhysRequResp_TX_PDC_RX_PBS: 6 PDC

BO_ 2564472818 UDSPhysRequResp_TX_PDC_RX_PDE: 6 PDC

BO_ 2564428735 UDSPhysRequResp_TX_PDE_RX_ATX: 6 PDE

BO_ 2564423871 UDSPhysRequResp_TX_PDE_RX_ECU: 6 PDE

BO_ 2564424639 UDSPhysRequResp_TX_PDE_RX_PBS: 6 PDE

BO_ 2564485823 UDSPhysRequResp_TX_PDE_RX_PDC: 6 PDE

BO_ 2365516030 Vehicle_DirectionSpeed_Vector__XXX: 8 Vector__XXX
 SG_ CompassBearing : 0|16@1+ (0.0078125,0) [0|501.99] "deg"  ATX
 SG_ NavigationBasedVehicleSpeed : 16|16@1+ (0.00390625,0) [0|250.996] "km/h"  ATX
 SG_ Pitch : 32|16@1+ (0.007813,-200) [-200|301.99] "deg"  PTP

BO_ 2633952256 Vehicle_Identification_ECU: 1 ECU

BO_ 2633952259 Vehicle_Identification_PBS: 1 PBS

BO_ 2633952498 Vehicle_Identification_PDC: 1 PDC

BO_ 2633952447 Vehicle_Identification_PDE: 1 PDE

BO_ 2499700990 VehicleFluids_Vector__XXX: 8 Vector__XXX
 SG_ HydOilTemp : 0|8@1+ (1,-40) [-40|210] "DegCgrd"  PTP
 SG_ CPRTemperature : 24|8@1+ (1,-40) [-40|210] "DegCgrd"  PTP

BO_ 2632319744 VirtTermECU_TX_ECU_RX_PBS: 8 ECU

BO_ 2632380928 VirtTermECU_TX_ECU_RX_PDC: 8 ECU

BO_ 2632367872 VirtTermECU_TX_ECU_RX_PDE: 8 ECU

BO_ 2632318979 VirtTermECU_TX_PBS_RX_ECU: 8 PBS

BO_ 2632380931 VirtTermECU_TX_PBS_RX_PDC: 8 PBS

BO_ 2632367875 VirtTermECU_TX_PBS_RX_PDE: 8 PBS

BO_ 2632319218 VirtTermECU_TX_PDC_RX_ECU: 8 PDC

BO_ 2632319986 VirtTermECU_TX_PDC_RX_PBS: 8 PDC

BO_ 2632368114 VirtTermECU_TX_PDC_RX_PDE: 8 PDC

BO_ 2632319167 VirtTermECU_TX_PDE_RX_ECU: 8 PDE

BO_ 2632319935 VirtTermECU_TX_PDE_RX_PBS: 8 PDE

BO_ 2632381119 VirtTermECU_TX_PDE_RX_PDC: 8 PDE

BO_ 2632384256 Virtual_TerminaltoECU_ECU: 8 ECU

BO_ 2632384259 Virtual_TerminaltoECU_PBS: 8 PBS

BO_ 2632384498 Virtual_TerminaltoECU_PDC: 8 PDC

BO_ 2632384447 Virtual_TerminaltoECU_PDE: 8 PDE

BO_ 2365475070 WheelBasedSpeedandDistance_Vector__XXX: 8 Vector__XXX

BO_ 2566786304 Working_Set_Master_ECU: 8 ECU

BO_ 2566786307 Working_Set_Master_PBS: 8 PBS

BO_ 2566786495 Working_Set_Master_PDE: 8 PDE

BO_ 2566786048 Working_Set_Member_ECU: 8 ECU

BO_ 2566786051 Working_Set_Member_PBS: 8 PBS

BO_ 2566786290 Working_Set_Member_PDC: 8 PDC

BO_ 2566786239 Working_Set_Member_PDE: 8 PDE

BO_ 2559377155 XCP_Command_Receive_Object_PBS: 8 PBS
 SG_ CRO_DatParms : 0|64@1+ (1,0) [0|0] ""  PDE,PTP

BO_ 2559311619 XCP_Data_Transmission_Object_PBS: 8 PBS
 SG_ DTO_DatParms : 0|64@1+ (1,0) [0|0] ""  PTP

BO_ 2559311807 XCP_Data_Transmission_Object_PDE: 8 PDE
 SG_ DTO_DatParms : 0|64@1+ (1,0) [0|0] ""  PBS,PTP

BO_ 2559360771 XCPCommReceObje_TX_PBS_RX_PDE: 8 PBS
 SG_ CRO_DatParms : 0|64@1+ (1,0) [0|0] ""  PDE

BO_ 2559312643 XCPCommReceObje_TX_PBS_RX_PTP: 8 PBS
 SG_ CRO_DatParms : 0|64@1+ (1,0) [0|0] ""  PTP

BO_ 2559247107 XCPDataTranObje_TX_PBS_RX_PTP: 8 PBS
 SG_ DTO_DatParms : 0|64@1+ (1,0) [0|0] ""  PTP

BO_ 2559247295 XCPDataTranObje_TX_PDE_RX_PBS: 8 PDE
 SG_ DTO_DatParms : 0|64@1+ (1,0) [0|0] ""  PBS

BO_ 2566912512 Mx_FFFA_P6_0x00: 8 ECU
 SG_ CmdBytePGN65530_ECU M : 0|16@1+ (1,0) [0|0] ""  EIC,PDC
 SG_ AcceleratedDOCInletTemperature m329 : 16|16@1+ (0.03125,-50) [-50|1997.9688] ""  Vector__XXX
 SG_ AcceleratedDOCOutletTemperature m329 : 32|16@1+ (0.03125,-50) [-50|1997.9688] ""  Vector__XXX
 SG_ AcceleratedSCRInletTemperature m329 : 48|16@1+ (0.03125,-50) [-50|1997.9688] ""  Vector__XXX
 SG_ AcceleratedDPFOutletNOx m585 : 16|16@1+ (0.03125,0) [0|2047.031] ""  Vector__XXX
 SG_ AcceleratedSCROutletNOx m585 : 32|16@1+ (0.03125,0) [0|2047.031] ""  Vector__XXX
 SG_ SCRWarmUpRequestedTimer m585 : 48|16@1+ (0.03125,0) [0|2047.031] ""  Vector__XXX
 SG_ EngDPFActRegPrepProg m11266 : 16|8@1+ (0.4,0) [0|100] ""  EIC,PDC
 SG_ EngDPFActRegClngProg m11266 : 24|8@1+ (0.4,0) [0|100] ""  EIC,PDC
 SG_ EngDPFRegenState m11266 : 44|4@1+ (1,0) [0|15] ""  EIC,PDC
 SG_ CurrentNumberofStarts m17153 : 16|16@1+ (1,1) [0|65535] ""  Vector__XXX
 SG_ DesiredFuel m17153 : 32|16@1+ (0.0625,0) [0|4095.9375] ""  Vector__XXX
 SG_ EngineOperatingCondition m17153 : 48|8@1+ (1,1) [0|255] ""  Vector__XXX
 SG_ DEFFlowRate m17153 : 56|8@1+ (0.03125,0) [0|7.96875] ""  Vector__XXX
 SG_ DPFDeltaPressure m17409 : 16|16@1+ (0.125,0) [0|4095.9375] ""  Vector__XXX
 SG_ FiltNormDPFDeltPresAfteActiRege m17409 : 32|8@1+ (0.125,0) [0|31.875] ""  Vector__XXX
 SG_ SCRAdapContAdjuFact m17409 : 40|8@1+ (0.015625,0) [0|3.984375] ""  Vector__XXX
 SG_ MaximumAllowedNH3FlowRate m17409 : 48|16@1+ (0.0078125,0) [0|511.9922] ""  Vector__XXX
 SG_ CharAirCoolEffeLongTermCorrFact m20483 : 16|8@1+ (0.015625,0) [0|3.984375] ""  Vector__XXX
 SG_ CompInlePresCorrFact m20483 : 24|8@1+ (0.015625,0) [0|3.984375] ""  Vector__XXX
 SG_ EGRCoolEffeLongTermCorrFact m20483 : 32|8@1+ (0.015625,0) [0|3.984375] ""  Vector__XXX
 SG_ VTGPosiLongTermCorrOffs m20483 : 40|8@1+ (0.015625,0) [0|3.984375] ""  Vector__XXX
 SG_ RailPCtrlClsdLoopCmd m20483 : 48|16@1- (0.015625,-500) [-500|-523.9843] ""  Vector__XXX
 SG_ IntaManiTempSensEstiUnco m20739 : 16|8@1+ (1,-40) [-40|215] ""  Vector__XXX
 SG_ CharAirCoolOutlTempSensEstiUnco m20739 : 24|8@1+ (1,-40) [-40|215] ""  Vector__XXX
 SG_ EGRCoolOutlTempSensEstiUnco m20739 : 32|8@1+ (2,-40) [-40|470] ""  Vector__XXX
 SG_ EGRGasTemperatureSensor m20739 : 40|8@1+ (2,-40) [-40|470] ""  Vector__XXX
 SG_ IntaManiPresEstiUnco m20995 : 16|16@1+ (0.015625,0) [0|1023.94375] ""  Vector__XXX
 SG_ ExhaManiPresSensEstiUnco m20995 : 32|8@1+ (3,0) [0|765] ""  Vector__XXX
 SG_ ExhaManiPresSensRead m20995 : 40|8@1+ (3,0) [0|765] ""  Vector__XXX
 SG_ CompInteTempSensEstiUnco m21507 : 16|8@1+ (2,-50) [0|450] ""  Vector__XXX
 SG_ InteCompOutlTempSensRead m21507 : 24|8@1+ (2,-50) [0|450] ""  Vector__XXX
 SG_ CylinderPressurePeak m21507 : 32|16@1+ (1,0) [0|65535] ""  Vector__XXX
 SG_ ExhaManiTempTherEsti m21507 : 48|16@1+ (0.03125,0) [0|2047.96875] ""  Vector__XXX

BO_ 2634021376 Mx_FFFA_P7_0x00: 8 ECU
 SG_ CmdBytePGN65530_ECU M : 0|16@1+ (1,0) [0|0] ""  PDC
 SG_ TorqueCurveLimit m20480 : 32|16@1+ (0.25,-6063.75) [-6063.75|10000] "kPa"  PDC
 SG_ ExhaManiPresSensFiltOffs m21251 : 16|8@1+ (0.125,-15) [-15|16.875] ""  Vector__XXX
 SG_ CompressorFlowCorrectionFactor m21251 : 24|8@1+ (0.015625,0) [0|3.984375] ""  Vector__XXX
 SG_ WastMassFlowLongTermCorrFact m21251 : 32|8@1+ (1,0) [0|3.984375] ""  Vector__XXX
 SG_ ExhaThroPosiLongTermCorrOffs m21251 : 40|8@1+ (0.003906,-0.5) [-0.5|0.49609375] ""  Vector__XXX
 SG_ AECDActiveStatusAll m21251 : 48|8@1+ (1,0) [0|255] ""  Vector__XXX
 SG_ WastActuPresLongTermCorrOf m21251 : 56|8@1+ (1,-70) [-70|185] ""  Vector__XXX
 SG_ IntaManiTempEGRFlowCorrStat m21763 : 16|8@1+ (1,0) [0|6] ""  Vector__XXX
 SG_ AirModeAirThrottleMode m21763 : 24|8@1+ (1,0) [0|31] ""  Vector__XXX
 SG_ AirSystObseInpuConfLeve m21763 : 32|8@1+ (1,0) [0|2] ""  Vector__XXX
 SG_ NOxBasedEGRFlowCorrectionState m21763 : 40|8@1+ (1,0) [0|6] ""  Vector__XXX
 SG_ EGRFlowCorrectionActionRequest m21763 : 48|8@1+ (1,0) [0|6] ""  Vector__XXX
 SG_ AirModeEGRValveMode m22019 : 16|8@1+ (1,0) [0|31] ""  Vector__XXX
 SG_ AirModeWastegateSolenoidMode m22019 : 24|8@1+ (1,0) [0|31] ""  Vector__XXX
 SG_ AirModeExhaustThrottleMode m22019 : 32|8@1+ (1,0) [0|31] ""  Vector__XXX
 SG_ AirModeVTGMode m22019 : 40|8@1+ (1,0) [0|31] ""  Vector__XXX
 SG_ CharAirCoolMassFlowLongTermCorrFact m22275 : 16|8@1+ (1,0) [0|3.984375] ""  Vector__XXX
 SG_ EGRFlowCorrFactLongTermCorrOffs m22275 : 24|8@1+ (1,0) [0|3.984375] ""  Vector__XXX
 SG_ EGRFlowCorrectionFactor m22275 : 32|8@1+ (0.007813,0) [0|1.992188] ""  Vector__XXX
 SG_ TurbMapMassFlowLongTermCorrFact m22275 : 40|8@1+ (0.015625,0) [0|3.984375] ""  Vector__XXX
 SG_ AirThroPosiLongTermCorrOffs m22275 : 48|8@1+ (0.003906,-0.1) [0|0] ""  Vector__XXX
 SG_ EGRValvPosiLongTermCorrOffs m22275 : 56|8@1+ (0.003906,-0.1) [0|0] ""  Vector__XXX

BO_ 2365587219 AdvaGuidStatResp_ATX: 8 ATX
 SG_ CmdBytePGN65535_ATX M : 0|8@1+ (1,0) [0|0] ""  Vector__XXX
 SG_ AutoTracWheelbase_AGSR m147 : 8|8@1+ (0.05,0) [0|12.5] "m"  Vector__XXX
 SG_ AutoTracSysCtlrLoSpdLim m147 : 16|8@1+ (0.00390625,0) [0|0.9765625] "km/h"  Vector__XXX
 SG_ AutoTracSysCtlrUpSpdLim m147 : 24|8@1+ (0.5,0) [0|125] "km/h"  Vector__XXX
 SG_ AutoTracSysCtlrUnlimitRevCapable m147 : 32|2@1+ (1,0) [0|3] ""  Vector__XXX
 SG_ AuxResuCap m147 : 34|2@1+ (1,0) [0|3] ""  Vector__XXX
 SG_ WASType m147 : 36|4@1+ (1,0) [0|15] ""  Vector__XXX
 SG_ MaxReverseSpeed m147 : 40|8@1+ (0.5,0) [0|125] "km/h"  Vector__XXX
 SG_ ConfigMachineClass m147 : 48|5@1+ (1,0) [0|31] ""  Vector__XXX
 SG_ SIDType m147 : 53|3@1+ (1,0) [0|7] ""  Vector__XXX
 SG_ ActuatorType m147 : 56|3@1+ (1,0) [0|7] ""  Vector__XXX
 SG_ StarfireFwdCfg_AGSR m147 : 59|3@1+ (1,0) [0|7] ""  Vector__XXX

BO_ 2499805170 Advanced_Guidance_Status_PDC: 8 PDC
 SG_ CmdBytePGN65535_PDC M : 0|8@1+ (1,0) [0|0] ""  ATX
 SG_ VehWheelbase m146 : 8|8@1+ (0.05,0) [0|12.5] "m"  ATX
 SG_ AutoTracSysLoSpdLimRqst m146 : 16|8@1+ (0.00390625,0) [0|0.9765625] "km/h"  ATX
 SG_ AutoTracSysUpSpdLimRqst m146 : 24|8@1+ (0.5,0) [0|125] "km/h"  ATX
 SG_ AutoTracSysUnlimitRevCapable m146 : 32|2@1+ (1,0) [0|3] ""  ATX
 SG_ AuxResuCapRqst m146 : 34|2@1+ (1,0) [0|3] ""  ATX
 SG_ WASTypeInstalled m146 : 36|4@1+ (1,0) [0|15] ""  ATX
 SG_ MaxReverseSpeedRqst m146 : 40|8@1+ (0.5,0) [0|125] "km/h"  ATX
 SG_ ActualMachineClass m146 : 48|5@1+ (1,0) [0|31] ""  ATX
 SG_ SIDTypeRqst m146 : 53|3@1+ (1,0) [0|7] ""  ATX
 SG_ ActuatorTypeRqst m146 : 56|3@1+ (1,0) [0|7] ""  ATX
 SG_ StarfireFwdCfgRqst m146 : 59|3@1+ (1,0) [0|7] ""  ATX

BO_ 2634020864 ATNOxCEStatistics_ECU: 8 ECU
 SG_ CmdBytePGN65528_ECU M : 0|8@1+ (1,0) [0|0] ""  Vector__XXX
 SG_ AftrtrtmntSCRObsNOxCnvrsnEff m150 : 8|16@1+ (1,0) [0|5] ""  Vector__XXX
 SG_ AftrtrtmntOutNOxTailCnt m150 : 24|16@1+ (1,0) [0|5] ""  Vector__XXX
 SG_ SCRNOXCEMonState m150 : 42|2@1+ (1,0) [0|3] ""  Vector__XXX
 SG_ SCRAdapConDisable m150 : 44|2@1+ (1,0) [0|3] ""  Vector__XXX
 SG_ SCRAdapConAdjFactor m150 : 48|16@1+ (1,-32768) [-32768|32767] ""  Vector__XXX

BO_ 2566910995 Mx_FFF4_P6_0x13: 8 ATX
 SG_ CmdBytePGN65524_ATX M : 0|8@1+ (1,0) [0|0] ""  PDC,PTP
 SG_ SteeredWheelAngle m95 : 8|16@1+ (0.0078125,-200) [-200|301.99] "deg"  PDC,PTP
 SG_ CrvtrCntrlATState_ATSV m95 : 24|4@1+ (1,0) [0|15] ""  Vector__XXX
 SG_ RedSteerWarnLightRequest m95 : 28|2@1+ (1,0) [0|3] ""  Vector__XXX
 SG_ Heartbeat m95 : 52|4@1+ (1,0) [0|15] "Count"  Vector__XXX
 SG_ AT2ExitCode_GMSJDE m99 : 8|8@1+ (1,0) [0|255] ""  Vector__XXX
 SG_ WheelBasedVehicleSpeed_GMSJDE m99 : 16|16@1+ (0.00390625,0) [0|0.9765625] "km/h"  Vector__XXX
 SG_ VehDirection m99 : 32|4@1+ (1,0) [0|15] ""  Vector__XXX
 SG_ AutoTracSystemState m99 : 36|4@1+ (1,0) [0|15] ""  Vector__XXX
 SG_ StarfireFwdCfg_GMSJDE m99 : 40|3@1+ (1,0) [0|7] ""  Vector__XXX
 SG_ ActivateGuidanceRequest m99 : 43|2@1+ (1,0) [0|3] ""  Vector__XXX
 SG_ AuxiliarySteerMode m99 : 48|4@1+ (1,0) [0|15] ""  Vector__XXX
 SG_ Heartbeat m99 : 52|4@1+ (1,0) [0|0] ""  Vector__XXX

BO_ 2365584382 ClosSystPgnA18JDHWAutoShifPara_Vector__XXX: 8 Vector__XXX
 SG_ CmdBytePGN65523_Vector_XXX M : 0|8@1+ (1,0) [0|0] ""  PBS,PTP
 SG_ ParkBrakeReq m49 : 44|2@1+ (1,0) [0|3] ""  PBS,PTP
 SG_ HydHndlState m49 : 56|3@1+ (1,0) [0|7] ""  PBS,PTP

BO_ 2566913539 Mx_FFFE_P6_0x03: 8 PBS
 SG_ CmdBytePGN65534_PBS M : 0|8@1+ (1,0) [0|0] ""  Vector__XXX

BO_ 2566913778 Mx_FFFE_P6_0xF2: 8 PDC
 SG_ CmdBytePGN65534_PDC M : 0|8@1+ (1,0) [0|0] ""  Vector__XXX

BO_ 2566913727 Mx_FFFE_P6_0xBF: 8 PDE
 SG_ CmdBytePGN65534_PDE M : 0|8@1+ (1,0) [0|0] ""  Vector__XXX

BO_ 2632909571 Mx_EF03_P7_0x03: 8 PBS
 SG_ CmdBytePGN61184_PBS M : 0|16@1+ (1,0) [0|0] ""  Vector__XXX

CM_ "DBC file created from Harvester_Combine_Mercury_MY25_CAN.csv with CAN2DBC 4.5.1 on NoDate";
CM_ BO_ 2566912512 "AcceleratedDOCSCRTemperatures; AcceleratedDPFSCROutletNOx; AirSystemObserverCorrectionFactors1; AirSystemObserverPlausibility1; AirSystemObserverPlausibility2; EngineDPFRegenerationState; EngineTemperaturesAndPressures; MTGAftertreatmentControl1; MTGEngineConsumptionAndOperation";
CM_ BO_ 2634021376 "ActuatorAirModes; AirSystemStates; AirSystemObserverCorrectionFactors2; AirSystemObserverCorrectionFactors3; JD_Engine_Control_Message_18";
CM_ BO_ 2365587219 "Advanced_Guidance_Status_Response";
CM_ BO_ 2499805170 "Advanced_Guidance_Status";
CM_ BO_ 2634020864 "ATNOxCEStatistics";
CM_ BO_ 2566910995 "AutoTrac_State_for_Vehicle; Guidance_Machine_Status_J_D_Extended";
CM_ BO_ 2365584382 "ClosedSystemPgnA18JDHWAutoShiftParameters";
CM_ BO_ 2566913539 "Combine_Network_Health_Data; Combine_Network_Health_Data_2";
CM_ BO_ 2566913778 "Combine_Network_Health_Data; Combine_Network_Health_Data_2";
CM_ BO_ 2566913727 "Combine_Network_Health_Data; Combine_Network_Health_Data_2";
CM_ BO_ 2632909571 "Controller_Data_Message; Controller_Data_Message; Controller_Data_Message_0xAD01; Controller_Data_Message_0xAD01; Controller_Data_Message_0xAD02; Controller_Data_Message_0xAD02; Controller_Data_Message_0xAD03; Controller_Data_Message_0xAD03; Controller_Data_Message_0xAD04; Controller_Data_Message_0xAD04; Controller_Data_Message_0xAD05; Controller_Data_Message_0xAD05; Controller_Data_Message_0xAD06; Controller_Data_Message_0xAD06; Controller_Data_Message_0xAD07; Controller_Data_Message_0xAD07; Controller_Data_Message_0xAD08; Controller_Data_Message_0xAD08; Controller_Data_Message_0xAD09; Controller_Data_Message_0xAD09; Controller_Data_Message_0xAD0A; Controller_Data_Message_0xAD0A; Controller_Data_Message_0xAD0B; Controller_Data_Message_0xAD0B; Controller_Data_Message_0xAD0C; Controller_Data_Message_0xAD0C; Controller_Data_Message_0xAD0D; Controller_Data_Message_0xAD0D; Controller_Data_Message_0xAD0E; Controller_Data_Message_0xAD0E; Controller_Data_Message_0xAD0F; Controller_Data_Message_0xAD0F; Controller_Data_Message_0xAD10; Controller_Data_Message_0xAD10; Controller_Data_Message_0xAD11; Controller_Data_Message_0xAD11; Controller_Data_Message_0xAD12; Controller_Data_Message_0xAD12; Controller_Data_Message_0xAD13; Controller_Data_Message_0xAD13; Controller_Data_Message_0xAD14; Controller_Data_Message_0xAD14; Controller_Data_Message_0xAD15; Controller_Data_Message_0xAD15; Controller_Data_Message_0xAD16; Controller_Data_Message_0xAD16; Controller_Data_Message_0xAD17; Controller_Data_Message_0xAD17; Controller_Data_Message_0xAD18; Controller_Data_Message_0xAD18; Controller_Data_Message_0xAD19; Controller_Data_Message_0xAD19; Controller_Data_Message_0xAD1A; Controller_Data_Message_0xAD1A; Controller_Data_Message_0xAD1B; Controller_Data_Message_0xAD1B; Controller_Data_Message_0xAD1C; Controller_Data_Message_0xAD1C; Controller_Data_Message_0xAD1D; Controller_Data_Message_0xAD1D; Controller_Data_Message_0xAD1E; Controller_Data_Message_0xAD1E; Controller_Data_Message_0xAD1F; Controller_Data_Message_0xAD1F; Controller_Data_Message_0xAD20; Controller_Data_Message_0xAD20; Controller_Data_Message_0xAD21; Controller_Data_Message_0xAD21; Controller_Data_Message_0xAD22; Controller_Data_Message_0xAD22; Controller_Data_Message_0xAD23; Controller_Data_Message_0xAD23; Controller_Data_Message_0xAD24; Controller_Data_Message_0xAD24; Controller_Data_Message_0xAD25; Controller_Data_Message_0xAD25; Controller_Data_Message_0xAD26; Controller_Data_Message_0xAD26; Controller_Data_Message_0xAD27; Controller_Data_Message_0xAD27; Controller_Data_Message_0xAD28; Controller_Data_Message_0xAD28; Controller_Data_Message_0xAD29; Controller_Data_Message_0xAD29; Controller_Data_Message_0xAD2A; Controller_Data_Message_0xAD2A; Controller_Data_Message_0xAD2B; Controller_Data_Message_0xAD2B; Controller_Data_Message_0xAD2C; Controller_Data_Message_0xAD2C; Controller_Data_Message_0xAD2D; Controller_Data_Message_0xAD2D; Controller_Data_Message_0xAD2E; Controller_Data_Message_0xAD2E; Data_Request_Message; Data_Request_Message; Data_Request_Message_0xAC01; Data_Request_Message_0xAC01; Data_Request_Message_0xAC02; Data_Request_Message_0xAC02; Data_Request_Message_0xAC03; Data_Request_Message_0xAC03; Data_Request_Message_0xAC04; Data_Request_Message_0xAC04; Data_Request_Message_0xAC05; Data_Request_Message_0xAC05; Data_Request_Message_0xAC06; Data_Request_Message_0xAC06; Data_Request_Message_0xAC07; Data_Request_Message_0xAC07; Data_Request_Message_0xAC08; Data_Request_Message_0xAC08; Data_Request_Message_0xAC09; Data_Request_Message_0xAC09; Data_Request_Message_0xAC0A; Data_Request_Message_0xAC0A; Data_Request_Message_0xAC0B; Data_Request_Message_0xAC0B; Data_Request_Message_0xAC0C; Data_Request_Message_0xAC0C; Data_Request_Message_0xAC0D; Data_Request_Message_0xAC0D; Data_Request_Message_0xAC0E; Data_Request_Message_0xAC0E; Data_Request_Message_0xAC0F; Data_Request_Message_0xAC0F; Data_Request_Message_0xAC10; Data_Request_Message_0xAC10; Data_Request_Message_0xAC11; Data_Request_Message_0xAC11; Data_Request_Message_0xAC12; Data_Request_Message_0xAC12; Data_Request_Message_0xAC13; Data_Request_Message_0xAC13; Data_Request_Message_0xAC14; Data_Request_Message_0xAC14; Data_Request_Message_0xAC15; Data_Request_Message_0xAC15; Data_Request_Message_0xAC16; Data_Request_Message_0xAC16; Data_Request_Message_0xAC17; Data_Request_Message_0xAC17; Data_Request_Message_0xAC18; Data_Request_Message_0xAC18; Data_Request_Message_0xAC19; Data_Request_Message_0xAC19; Data_Request_Message_0xAC1A; Data_Request_Message_0xAC1A; Data_Request_Message_0xAC1B; Data_Request_Message_0xAC1B; Data_Request_Message_0xAC1C; Data_Request_Message_0xAC1C; Data_Request_Message_0xAC1D; Data_Request_Message_0xAC1D; Data_Request_Message_0xAC1E; Data_Request_Message_0xAC1E; Data_Request_Message_0xAC1F; Data_Request_Message_0xAC1F; Data_Request_Message_0xAC20; Data_Request_Message_0xAC20; Data_Request_Message_0xAC21; Data_Request_Message_0xAC21; Data_Request_Message_0xAC22; Data_Request_Message_0xAC22; Data_Request_Message_0xAC23; Data_Request_Message_0xAC23; Data_Request_Message_0xAC24; Data_Request_Message_0xAC24; Data_Request_Message_0xAC25; Data_Request_Message_0xAC25; Data_Request_Message_0xAC26; Data_Request_Message_0xAC26; Data_Request_Message_0xAC27; Data_Request_Message_0xAC27; Data_Request_Message_0xAC28; Data_Request_Message_0xAC28; Data_Request_Message_0xAC29; Data_Request_Message_0xAC29; Data_Request_Message_0xAC2A; Data_Request_Message_0xAC2A";
BA_DEF_ SG_ "SigType" ENUM "Default", "Range", "RangeSigned", "ASCII", "Discrete", "Control", "ReferencePGN", "DTC", "StringDelimiter", "StringLength", "StringLengthControl", "MessageCounter", "MessageChecksum";
BA_DEF_ SG_ "GenSigSendType" ENUM "Cyclic", "OnWrite", "OnWriteWithRepetition", "OnChange", "OnChangeWithRepetition", "IfActive", "IfActiveWithRepetition", "NoSigSendType";
BA_DEF_ SG_ "GenSigTimeoutTime_ECU" INT 0 3600000;
BA_DEF_ SG_ "GenSigILSupport" ENUM "Yes", "No";
BA_DEF_ SG_ "GenSigEVName" STRING ;
BA_DEF_ BO_ "GenMsgILSupport" ENUM "Yes", "No";
BA_DEF_ BO_ "GenMsgSendType" ENUM "cyclic", "reserved", "cyclicIfActive", "reserved", "reserved", "reserved", "reserved", "reserved", "NoMsgSendType";
BA_DEF_ BO_ "VFrameFormat" ENUM "StandardCAN", "ExtendedCAN", "reserved", "J1939PG";
BA_DEF_ BO_ "SingleFrame" INT 0 1;
BA_DEF_ BO_ "GenMsgCycleTime" INT 0 3600000;
BA_DEF_ BO_ "GenMsgCycleTimeFast" INT 0 3600000;
BA_DEF_ BU_ "NmStationAddress" INT 0 255;
BA_DEF_ BU_ "NmJ1939AAC" INT 0 1;
BA_DEF_ BU_ "NmJ1939IndustryGroup" INT 0 7;
BA_DEF_ BU_ "NmJ1939System" INT 0 127;
BA_DEF_ BU_ "NmJ1939SystemInstance" INT 0 15;
BA_DEF_ BU_ "NmJ1939Function" INT 0 255;
BA_DEF_ BU_ "NmJ1939FunctionInstance" INT 0 7;
BA_DEF_ BU_ "NmJ1939ECUInstance" INT 0 3;
BA_DEF_ BU_ "NmJ1939ManufacturerCode" INT 0 2047;
BA_DEF_ BU_ "NmJ1939IdentityNumber" INT 0 2097151;
BA_DEF_ BU_ "ECU" STRING ;
BA_DEF_ BU_ "AddressClaimSimulated" ENUM "no", "yes";
BA_DEF_  "DBName" STRING ;
BA_DEF_  "DatabaseVersion" STRING ;
BA_DEF_  "Baudrate" INT 100000 1000000;
BA_DEF_  "BusType" STRING ;
BA_DEF_  "ProtocolType" STRING ;
BA_DEF_  "SAE_J1939_75_SpecVersion" STRING ;
BA_DEF_  "SAE_J1939_21_SpecVersion" STRING ;
BA_DEF_  "SAE_J1939_73_SpecVersion" STRING ;
BA_DEF_  "SAE_J1939_71_SpecVersion" STRING ;
BA_DEF_DEF_ "SigType" "Default";
BA_DEF_DEF_ "GenSigSendType" "NoSigSendType";
BA_DEF_DEF_ "GenSigTimeoutTime_ECU" 0;
BA_DEF_DEF_ "GenSigILSupport" "Yes";
BA_DEF_DEF_ "GenSigEVName" "Env@Nodename_@Signame";
BA_DEF_DEF_ "GenMsgILSupport" "Yes";
BA_DEF_DEF_ "GenMsgSendType" "NoMsgSendType";
BA_DEF_DEF_ "VFrameFormat" "J1939PG";
BA_DEF_DEF_ "SingleFrame" 0;
BA_DEF_DEF_ "GenMsgCycleTime" 0;
BA_DEF_DEF_ "GenMsgCycleTimeFast" 0;
BA_DEF_DEF_ "NmStationAddress" 254;
BA_DEF_DEF_ "NmJ1939AAC" 0;
BA_DEF_DEF_ "NmJ1939IndustryGroup" 0;
BA_DEF_DEF_ "NmJ1939System" 0;
BA_DEF_DEF_ "NmJ1939SystemInstance" 0;
BA_DEF_DEF_ "NmJ1939Function" 0;
BA_DEF_DEF_ "NmJ1939FunctionInstance" 0;
BA_DEF_DEF_ "NmJ1939ECUInstance" 0;
BA_DEF_DEF_ "NmJ1939ManufacturerCode" 0;
BA_DEF_DEF_ "NmJ1939IdentityNumber" 0;
BA_DEF_DEF_ "ECU" "";
BA_DEF_DEF_ "AddressClaimSimulated" "no";
BA_DEF_DEF_ "DBName" "J1939Network";
BA_DEF_DEF_ "DatabaseVersion" "";
BA_DEF_DEF_ "Baudrate" 500000;
BA_DEF_DEF_ "BusType" "CAN";
BA_DEF_DEF_ "ProtocolType" "J1939";
BA_DEF_DEF_ "SAE_J1939_75_SpecVersion" "";
BA_DEF_DEF_ "SAE_J1939_21_SpecVersion" "";
BA_DEF_DEF_ "SAE_J1939_73_SpecVersion" "";
BA_DEF_DEF_ "SAE_J1939_71_SpecVersion" "";
BA_ "GenSigTimeoutTime_ECU" SG_ 2566757120 AftrtrtmntDEFConc 5000;
BA_ "GenSigSendType" SG_ 2566757120 AftrtrtmntDEFConc 0;
BA_ "GenSigTimeoutTime_ECU" SG_ 2566757120 AftrtrtmntDEFProp 5000;
BA_ "GenSigSendType" SG_ 2566757120 AftrtrtmntDEFProp 0;
BA_ "GenSigTimeoutTime_ECU" SG_ 2566804992 AftrtrtmntDEFTankLvl 5000;
BA_ "GenSigSendType" SG_ 2566804992 AftrtrtmntDEFTankLvl 0;
BA_ "GenSigTimeoutTime_ECU" SG_ 2566804992 AftrtrtmntDEFTankTemp 5000;
BA_ "GenSigSendType" SG_ 2566804992 AftrtrtmntDEFTankTemp 0;
BA_ "GenSigTimeoutTime_ECU" SG_ 2566804992 AftrtrtmntDEFTankLoLvlInd 5000;
BA_ "GenSigSendType" SG_ 2566804992 AftrtrtmntDEFTankLoLvlInd 0;
BA_ "GenSigTimeoutTime_ECU" SG_ 2566804992 AftrtrtmntSCROptrIndcmntSevrty 5000;
BA_ "GenSigSendType" SG_ 2566804992 AftrtrtmntSCROptrIndcmntSevrty 0;
BA_ "GenSigTimeoutTime_ECU" SG_ 2566748928 PartTrap1TimeSinceLastActReg 60000;
BA_ "GenSigSendType" SG_ 2566748928 PartTrap1TimeSinceLastActReg 0;
BA_ "GenSigTimeoutTime_ECU" SG_ 2566763264 AftrDiesPartFltrOutlGasTemp 2500;
BA_ "GenSigSendType" SG_ 2566763264 AftrDiesPartFltrOutlGasTemp 0;
BA_ "GenSigTimeoutTime_ECU" SG_ 2566700288 AftrtrtmntTotalDEFUsed 60000;
BA_ "GenSigSendType" SG_ 2566700288 AftrtrtmntTotalDEFUsed 0;
BA_ "GenSigTimeoutTime_ECU" SG_ 2565874432 AftrTrtmDiesExhsFldActDsngQty 250;
BA_ "GenSigSendType" SG_ 2565874432 AftrTrtmDiesExhsFldActDsngQty 0;
BA_ "GenSigTimeoutTime_ECU" SG_ 2566845696 BarometricPress 5000;
BA_ "GenSigSendType" SG_ 2566845696 BarometricPress 0;
BA_ "GenSigTimeoutTime_ECU" SG_ 2566845696 AmbAirTemp 5000;
BA_ "GenSigSendType" SG_ 2566845696 AmbAirTemp 0;
BA_ "GenSigTimeoutTime_ECU" SG_ 2566845696 EngAirInTemp 5000;
BA_ "GenSigSendType" SG_ 2566845696 EngAirInTemp 0;
BA_ "GenSigTimeoutTime_ECU" SG_ 2298409219 WheelBasedVehicleSpeed 500;
BA_ "GenSigSendType" SG_ 2298409219 WheelBasedVehicleSpeed 0;
BA_ "GenSigTimeoutTime_ECU" SG_ 2298409219 BrakeSwitch 500;
BA_ "GenSigSendType" SG_ 2298409219 BrakeSwitch 0;
BA_ "GenSigTimeoutTime_ECU" SG_ 2566749184 DieselPartFltrState 5000;
BA_ "GenSigSendType" SG_ 2566749184 DieselPartFltrState 0;
BA_ "GenSigTimeoutTime_ECU" SG_ 2566749184 CANExhstSysHighTempLmpCmd 5000;
BA_ "GenSigSendType" SG_ 2566749184 CANExhstSysHighTempLmpCmd 0;
BA_ "GenSigTimeoutTime_ECU" SG_ 2566749184 DiesPartFltrActvRegeFrcdStat 5000;
BA_ "GenSigSendType" SG_ 2566749184 DiesPartFltrActvRegeFrcdStat 0;
BA_ "GenSigTimeoutTime_ECU" SG_ 2364539904 EngineTorqueMode 100;
BA_ "GenSigSendType" SG_ 2364539904 EngineTorqueMode 0;
BA_ "GenSigTimeoutTime_ECU" SG_ 2364539904 ActEngPrcntTorqFrac 100;
BA_ "GenSigSendType" SG_ 2364539904 ActEngPrcntTorqFrac 0;
BA_ "GenSigTimeoutTime_ECU" SG_ 2364539904 DrvrsDmdEngPctTorq 100;
BA_ "GenSigSendType" SG_ 2364539904 DrvrsDmdEngPctTorq 0;
BA_ "GenSigTimeoutTime_ECU" SG_ 2364539904 ActualEnginePercentTorque 100;
BA_ "GenSigSendType" SG_ 2364539904 ActualEnginePercentTorque 0;
BA_ "GenSigTimeoutTime_ECU" SG_ 2364539904 EngineSpeed 100;
BA_ "GenSigSendType" SG_ 2364539904 EngineSpeed 0;
BA_ "GenSigTimeoutTime_ECU" SG_ 2364539904 SrcAddofCntlDevForEngCont 100;
BA_ "GenSigSendType" SG_ 2364539904 SrcAddofCntlDevForEngCont 0;
BA_ "GenSigTimeoutTime_ECU" SG_ 2364539904 EngStarterMode 100;
BA_ "GenSigSendType" SG_ 2364539904 EngStarterMode 0;
BA_ "GenSigTimeoutTime_ECU" SG_ 2364539904 EngDemandPctTorq 100;
BA_ "GenSigSendType" SG_ 2364539904 EngDemandPctTorq 0;
BA_ "GenSigTimeoutTime_ECU" SG_ 2364539648 AccelPedalLoIdleSw 250;
BA_ "GenSigSendType" SG_ 2364539648 AccelPedalLoIdleSw 0;
BA_ "GenSigTimeoutTime_ECU" SG_ 2364539648 AccelPedalKckdownSw 250;
BA_ "GenSigSendType" SG_ 2364539648 AccelPedalKckdownSw 0;
BA_ "GenSigTimeoutTime_ECU" SG_ 2364539648 RoadSpdLimState 250;
BA_ "GenSigSendType" SG_ 2364539648 RoadSpdLimState 0;
BA_ "GenSigTimeoutTime_ECU" SG_ 2364539648 AccelPedal2LoIdleSw 250;
BA_ "GenSigSendType" SG_ 2364539648 AccelPedal2LoIdleSw 0;
BA_ "GenSigTimeoutTime_ECU" SG_ 2364539648 AcceleratorPosition 250;
BA_ "GenSigSendType" SG_ 2364539648 AcceleratorPosition 0;
BA_ "GenSigTimeoutTime_ECU" SG_ 2364539648 PercentLoadAtCurrentSpeed 250;
BA_ "GenSigSendType" SG_ 2364539648 PercentLoadAtCurrentSpeed 0;
BA_ "GenSigTimeoutTime_ECU" SG_ 2364539648 RemoteAccelerator 250;
BA_ "GenSigSendType" SG_ 2364539648 RemoteAccelerator 0;
BA_ "GenSigTimeoutTime_ECU" SG_ 2364539648 AccelInput2Pstn 250;
BA_ "GenSigSendType" SG_ 2364539648 AccelInput2Pstn 0;
BA_ "GenSigTimeoutTime_ECU" SG_ 2364539648 VehAccelRateLimState 250;
BA_ "GenSigSendType" SG_ 2364539648 VehAccelRateLimState 0;
BA_ "GenSigTimeoutTime_ECU" SG_ 2364539648 MomEngMaxPwrEnblFdbk 250;
BA_ "GenSigSendType" SG_ 2364539648 MomEngMaxPwrEnblFdbk 0;
BA_ "GenSigTimeoutTime_ECU" SG_ 2364539648 DPFThrmlMngmntActive 250;
BA_ "GenSigSendType" SG_ 2364539648 DPFThrmlMngmntActive 0;
BA_ "GenSigTimeoutTime_ECU" SG_ 2364539648 SCRThrmlMngmntActv 250;
BA_ "GenSigSendType" SG_ 2364539648 SCRThrmlMngmntActv 0;
BA_ "GenSigTimeoutTime_ECU" SG_ 2364539648 ActMaxAvailEngPrcntTorq 250;
BA_ "GenSigSendType" SG_ 2364539648 ActMaxAvailEngPrcntTorq 0;
BA_ "GenSigTimeoutTime_ECU" SG_ 2364539648 EstPumpPrcntTorq 250;
BA_ "GenSigSendType" SG_ 2364539648 EstPumpPrcntTorq 0;
BA_ "GenSigTimeoutTime_ECU" SG_ 2566840064 NominalFrictionPercentTorque 500;
BA_ "GenSigSendType" SG_ 2566840064 NominalFrictionPercentTorque 0;
BA_ "GenSigTimeoutTime_ECU" SG_ 2566840064 EnginesDesiredOperatingSpeed 500;
BA_ "GenSigSendType" SG_ 2566840064 EnginesDesiredOperatingSpeed 0;
BA_ "GenSigTimeoutTime_ECU" SG_ 2566840064 EngDsrdOpSpdAsymAdj 500;
BA_ "GenSigSendType" SG_ 2566840064 EngDsrdOpSpdAsymAdj 0;
BA_ "GenSigTimeoutTime_ECU" SG_ 2566840064 EstmtdEngParasiticLossPrcntTorq 500;
BA_ "GenSigSendType" SG_ 2566840064 EstmtdEngParasiticLossPrcntTorq 0;
BA_ "GenSigTimeoutTime_ECU" SG_ 2566840064 Aftr1ExhaGasMassFlowRate 500;
BA_ "GenSigSendType" SG_ 2566840064 Aftr1ExhaGasMassFlowRate 0;
BA_ "GenSigTimeoutTime_ECU" SG_ 2566840064 AftertreatmentIntakeDewPnt 500;
BA_ "GenSigSendType" SG_ 2566840064 AftertreatmentIntakeDewPnt 0;
BA_ "GenSigTimeoutTime_ECU" SG_ 2566840064 AftertreatmentExhaustDewPnt 500;
BA_ "GenSigSendType" SG_ 2566840064 AftertreatmentExhaustDewPnt 0;
BA_ "GenSigTimeoutTime_ECU" SG_ 2566840064 Aftertreatment2IntakeDewPnt 500;
BA_ "GenSigSendType" SG_ 2566840064 Aftertreatment2IntakeDewPnt 0;
BA_ "GenSigTimeoutTime_ECU" SG_ 2566840064 Aftertreatment2ExhDewPnt 500;
BA_ "GenSigSendType" SG_ 2566840064 Aftertreatment2ExhDewPnt 0;
BA_ "GenSigTimeoutTime_ECU" SG_ 2566844160 FuelDeliveryPressure 2500;
BA_ "GenSigSendType" SG_ 2566844160 FuelDeliveryPressure 0;
BA_ "GenSigTimeoutTime_ECU" SG_ 2566844160 EngineOilPressure 2500;
BA_ "GenSigSendType" SG_ 2566844160 EngineOilPressure 0;
BA_ "GenSigTimeoutTime_ECU" SG_ 2566844160 EngCoolPress 2500;
BA_ "GenSigSendType" SG_ 2566844160 EngCoolPress 0;
BA_ "GenSigTimeoutTime_ECU" SG_ 2566841088 ReferenceEngineTorque 25000;
BA_ "GenSigSendType" SG_ 2566841088 ReferenceEngineTorque 0;
BA_ "GenSigTimeoutTime_ECU" SG_ 2566841600 EngineHours 60000;
BA_ "GenSigSendType" SG_ 2566841600 EngineHours 0;
BA_ "GenSigTimeoutTime_ECU" SG_ 2566843904 EngineCoolantTemperature 5000;
BA_ "GenSigSendType" SG_ 2566843904 EngineCoolantTemperature 0;
BA_ "GenSigTimeoutTime_ECU" SG_ 2566843904 FuelTemperature 5000;
BA_ "GenSigSendType" SG_ 2566843904 FuelTemperature 0;
BA_ "GenSigTimeoutTime_ECU" SG_ 2432537342 EngOpState 1250;
BA_ "GenSigSendType" SG_ 2432537342 EngOpState 0;
BA_ "GenSigTimeoutTime_ECU" SG_ 2431708670 EngineStartRequest 5000;
BA_ "GenSigSendType" SG_ 2431708670 EngineStartRequest 0;
BA_ "GenSigTimeoutTime_ECU" SG_ 2566809856 EngIntakeManifold1AirTempHighRes 5000;
BA_ "GenSigSendType" SG_ 2566809856 EngIntakeManifold1AirTempHighRes 0;
BA_ "GenSigTimeoutTime_ECU" SG_ 2566809856 EngClntTempHighRes 5000;
BA_ "GenSigSendType" SG_ 2566809856 EngClntTempHighRes 0;
BA_ "GenSigTimeoutTime_ECU" SG_ 2566809856 EngChargeAirClrOutTemp 5000;
BA_ "GenSigSendType" SG_ 2566809856 EngChargeAirClrOutTemp 0;
BA_ "GenSigTimeoutTime_ECU" SG_ 2566842624 TotalFuelUsed 25000;
BA_ "GenSigSendType" SG_ 2566842624 TotalFuelUsed 0;
BA_ "GenSigTimeoutTime_ECU" SG_ 2566844928 EngFuelRate 500;
BA_ "GenSigSendType" SG_ 2566844928 EngFuelRate 0;
BA_ "GenSigTimeoutTime_ECU" SG_ 2360147731 EstimatedCurvature 500;
BA_ "GenSigSendType" SG_ 2360147731 EstimatedCurvature 0;
BA_ "GenSigTimeoutTime_ECU" SG_ 2360147731 MechSysLockout 500;
BA_ "GenSigSendType" SG_ 2360147731 MechSysLockout 0;
BA_ "GenSigTimeoutTime_ECU" SG_ 2360147731 StrgSysReadiness 500;
BA_ "GenSigSendType" SG_ 2360147731 StrgSysReadiness 0;
BA_ "GenSigTimeoutTime_ECU" SG_ 2360147731 StrgInputPstnState 500;
BA_ "GenSigSendType" SG_ 2360147731 StrgInputPstnState 0;
BA_ "GenSigTimeoutTime_ECU" SG_ 2360147731 ReqResetCmdState 500;
BA_ "GenSigSendType" SG_ 2360147731 ReqResetCmdState 0;
BA_ "GenSigTimeoutTime_ECU" SG_ 2360147731 GuideLimState 500;
BA_ "GenSigSendType" SG_ 2360147731 GuideLimState 0;
BA_ "GenSigTimeoutTime_ECU" SG_ 2360147731 GuideSysCmdExitRsnCode 500;
BA_ "GenSigSendType" SG_ 2360147731 GuideSysCmdExitRsnCode 0;
BA_ "GenSigTimeoutTime_ECU" SG_ 2360213502 CurvCmd 500;
BA_ "GenSigSendType" SG_ 2360213502 CurvCmd 0;
BA_ "GenSigTimeoutTime_ECU" SG_ 2360213502 CurvatureCmdState 500;
BA_ "GenSigSendType" SG_ 2360213502 CurvatureCmdState 0;
BA_ "GenSigTimeoutTime_ECU" SG_ 2365529086 SAS_Mask 250;
BA_ "GenSigSendType" SG_ 2365529086 SAS_Mask 0;
BA_ "GenSigTimeoutTime_ECU" SG_ 2365529086 SAS_SensorType 250;
BA_ "GenSigSendType" SG_ 2365529086 SAS_SensorType 0;
BA_ "GenSigTimeoutTime_ECU" SG_ 2365529086 SAS_CalibrationStatus 250;
BA_ "GenSigSendType" SG_ 2365529086 SAS_CalibrationStatus 0;
BA_ "GenSigTimeoutTime_ECU" SG_ 2365529086 SAS_DataIsValid 250;
BA_ "GenSigSendType" SG_ 2365529086 SAS_DataIsValid 0;
BA_ "GenSigTimeoutTime_ECU" SG_ 2365529086 SAS_Angle 250;
BA_ "GenSigSendType" SG_ 2365529086 SAS_Angle 0;
BA_ "GenSigTimeoutTime_ECU" SG_ 2365529086 SAS_AngleGradient 250;
BA_ "GenSigSendType" SG_ 2365529086 SAS_AngleGradient 0;
BA_ "GenSigTimeoutTime_ECU" SG_ 2365529086 SAS_RollingCounter 250;
BA_ "GenSigSendType" SG_ 2365529086 SAS_RollingCounter 0;
BA_ "GenSigTimeoutTime_ECU" SG_ 2365529086 SAS_Checksum 250;
BA_ "GenSigSendType" SG_ 2365529086 SAS_Checksum 0;
BA_ "GenSigTimeoutTime_ECU" SG_ 2566845952 EngParticulateTrapInPress 2500;
BA_ "GenSigSendType" SG_ 2566845952 EngParticulateTrapInPress 0;
BA_ "GenSigTimeoutTime_ECU" SG_ 2566845952 EngIntakeMan1Pressure 2500;
BA_ "GenSigSendType" SG_ 2566845952 EngIntakeMan1Pressure 0;
BA_ "GenSigTimeoutTime_ECU" SG_ 2566845952 EngIntakeMan1Temperature 2500;
BA_ "GenSigSendType" SG_ 2566845952 EngIntakeMan1Temperature 0;
BA_ "GenSigTimeoutTime_ECU" SG_ 2566845952 EngAirInPress 2500;
BA_ "GenSigSendType" SG_ 2566845952 EngAirInPress 0;
BA_ "GenSigTimeoutTime_ECU" SG_ 2566845952 AirFilterDifPressure 2500;
BA_ "GenSigSendType" SG_ 2566845952 AirFilterDifPressure 0;
BA_ "GenSigTimeoutTime_ECU" SG_ 2566845952 ExhGasTemp 2500;
BA_ "GenSigSendType" SG_ 2566845952 ExhGasTemp 0;
BA_ "GenSigTimeoutTime_ECU" SG_ 2566845952 EngCoolFilterDiffPress 2500;
BA_ "GenSigSendType" SG_ 2566845952 EngCoolFilterDiffPress 0;
BA_ "GenSigTimeoutTime_ECU" SG_ 2173485042 IOExtender_CRO_DatParms 100;
BA_ "GenSigTimeoutTime_ECU" SG_ 2173432511 IOExtender_DTO_DatParms 100;
BA_ "GenSigTimeoutTime_ECU" SG_ 2173501426 IOExtender_CRO_DatParms 100;
BA_ "GenSigTimeoutTime_ECU" SG_ 2173435839 IOExtender_DTO_DatParms 100;
BA_ "GenSigTimeoutTime_ECU" SG_ 2365584902 DesiredTorqueCurve 400;
BA_ "GenSigSendType" SG_ 2365584902 DesiredTorqueCurve 0;
BA_ "GenSigTimeoutTime_ECU" SG_ 2365584902 BusThrottleCommand 400;
BA_ "GenSigSendType" SG_ 2365584902 BusThrottleCommand 0;
BA_ "GenSigTimeoutTime_ECU" SG_ 2365584902 GovernorParameter 400;
BA_ "GenSigSendType" SG_ 2365584902 GovernorParameter 0;
BA_ "GenSigTimeoutTime_ECU" SG_ 2566801152 MaintainECUPower 2600;
BA_ "GenSigSendType" SG_ 2566801152 MaintainECUPower 0;
BA_ "GenSigTimeoutTime_ECU" SG_ 2566801155 MaintainActuatorPower 2600;
BA_ "GenSigSendType" SG_ 2566801155 MaintainActuatorPower 0;
BA_ "GenSigTimeoutTime_ECU" SG_ 2566801155 MaintainECUPower 2600;
BA_ "GenSigSendType" SG_ 2566801155 MaintainECUPower 0;
BA_ "GenSigTimeoutTime_ECU" SG_ 2566801155 ImplementWorkState 2600;
BA_ "GenSigSendType" SG_ 2566801155 ImplementWorkState 0;
BA_ "GenSigTimeoutTime_ECU" SG_ 2566801155 ImplementParkState 2600;
BA_ "GenSigSendType" SG_ 2566801155 ImplementParkState 0;
BA_ "GenSigTimeoutTime_ECU" SG_ 2566801155 ImplementTransportState 2600;
BA_ "GenSigSendType" SG_ 2566801155 ImplementTransportState 0;
BA_ "GenSigTimeoutTime_ECU" SG_ 2515538174 SequenceID_SDC 5000;
BA_ "GenSigSendType" SG_ 2515538174 SequenceID_SDC 0;
BA_ "GenSigTimeoutTime_ECU" SG_ 2515538174 TimeSource_SDC 5000;
BA_ "GenSigSendType" SG_ 2515538174 TimeSource_SDC 0;
BA_ "GenSigTimeoutTime_ECU" SG_ 2515538174 GenericDate_SDC 5000;
BA_ "GenSigSendType" SG_ 2515538174 GenericDate_SDC 0;
BA_ "GenSigTimeoutTime_ECU" SG_ 2515538174 GenericTimeofDay_SDC 5000;
BA_ "GenSigSendType" SG_ 2515538174 GenericTimeofDay_SDC 0;
BA_ "GenSigTimeoutTime_ECU" SG_ 2348810246 OverrideECUControlMode 100;
BA_ "GenSigTimeoutTime_ECU" SG_ 2348810246 ReqEngineSpeedControl 100;
BA_ "GenSigTimeoutTime_ECU" SG_ 2348810246 OverrideECUControlPriority 100;
BA_ "GenSigTimeoutTime_ECU" SG_ 2348810246 ReqEngineSpeed_TSC1 100;
BA_ "GenSigTimeoutTime_ECU" SG_ 2348810246 ReqTorque 100;
BA_ "GenSigTimeoutTime_ECU" SG_ 2365516030 CompassBearing 1000;
BA_ "GenSigSendType" SG_ 2365516030 CompassBearing 0;
BA_ "GenSigTimeoutTime_ECU" SG_ 2365516030 NavigationBasedVehicleSpeed 1000;
BA_ "GenSigSendType" SG_ 2365516030 NavigationBasedVehicleSpeed 0;
BA_ "GenSigTimeoutTime_ECU" SG_ 2365516030 Pitch 1000;
BA_ "GenSigSendType" SG_ 2365516030 Pitch 0;
BA_ "GenSigTimeoutTime_ECU" SG_ 2499700990 HydOilTemp 5000;
BA_ "GenSigSendType" SG_ 2499700990 HydOilTemp 0;
BA_ "GenSigTimeoutTime_ECU" SG_ 2499700990 CPRTemperature 5000;
BA_ "GenSigSendType" SG_ 2499700990 CPRTemperature 0;
BA_ "GenSigTimeoutTime_ECU" SG_ 2559377155 CRO_DatParms 60000;
BA_ "GenSigTimeoutTime_ECU" SG_ 2559311619 DTO_DatParms 60000;
BA_ "GenSigTimeoutTime_ECU" SG_ 2559311807 DTO_DatParms 60000;
BA_ "GenSigTimeoutTime_ECU" SG_ 2559360771 CRO_DatParms 60000;
BA_ "GenSigTimeoutTime_ECU" SG_ 2559312643 CRO_DatParms 60000;
BA_ "GenSigTimeoutTime_ECU" SG_ 2559247107 DTO_DatParms 60000;
BA_ "GenSigTimeoutTime_ECU" SG_ 2559247295 DTO_DatParms 60000;
BA_ "GenSigTimeoutTime_ECU" SG_ 2566912512 CmdBytePGN65530_ECU 5000;
BA_ "GenSigTimeoutTime_ECU" SG_ 2566912512 AcceleratedDOCInletTemperature 5000;
BA_ "GenSigSendType" SG_ 2566912512 AcceleratedDOCInletTemperature 0;
BA_ "GenSigTimeoutTime_ECU" SG_ 2566912512 AcceleratedDOCOutletTemperature 5000;
BA_ "GenSigSendType" SG_ 2566912512 AcceleratedDOCOutletTemperature 0;
BA_ "GenSigTimeoutTime_ECU" SG_ 2566912512 AcceleratedSCRInletTemperature 5000;
BA_ "GenSigSendType" SG_ 2566912512 AcceleratedSCRInletTemperature 0;
BA_ "GenSigTimeoutTime_ECU" SG_ 2566912512 AcceleratedDPFOutletNOx 5000;
BA_ "GenSigSendType" SG_ 2566912512 AcceleratedDPFOutletNOx 0;
BA_ "GenSigTimeoutTime_ECU" SG_ 2566912512 AcceleratedSCROutletNOx 5000;
BA_ "GenSigSendType" SG_ 2566912512 AcceleratedSCROutletNOx 0;
BA_ "GenSigTimeoutTime_ECU" SG_ 2566912512 SCRWarmUpRequestedTimer 5000;
BA_ "GenSigSendType" SG_ 2566912512 SCRWarmUpRequestedTimer 0;
BA_ "GenSigTimeoutTime_ECU" SG_ 2566912512 EngDPFActRegPrepProg 5000;
BA_ "GenSigSendType" SG_ 2566912512 EngDPFActRegPrepProg 0;
BA_ "GenSigTimeoutTime_ECU" SG_ 2566912512 EngDPFActRegClngProg 5000;
BA_ "GenSigSendType" SG_ 2566912512 EngDPFActRegClngProg 0;
BA_ "GenSigTimeoutTime_ECU" SG_ 2566912512 EngDPFRegenState 5000;
BA_ "GenSigSendType" SG_ 2566912512 EngDPFRegenState 0;
BA_ "GenSigTimeoutTime_ECU" SG_ 2566912512 CurrentNumberofStarts 5000;
BA_ "GenSigSendType" SG_ 2566912512 CurrentNumberofStarts 0;
BA_ "GenSigTimeoutTime_ECU" SG_ 2566912512 DesiredFuel 5000;
BA_ "GenSigSendType" SG_ 2566912512 DesiredFuel 0;
BA_ "GenSigTimeoutTime_ECU" SG_ 2566912512 EngineOperatingCondition 5000;
BA_ "GenSigSendType" SG_ 2566912512 EngineOperatingCondition 0;
BA_ "GenSigTimeoutTime_ECU" SG_ 2566912512 DEFFlowRate 5000;
BA_ "GenSigSendType" SG_ 2566912512 DEFFlowRate 0;
BA_ "GenSigTimeoutTime_ECU" SG_ 2566912512 DPFDeltaPressure 5000;
BA_ "GenSigSendType" SG_ 2566912512 DPFDeltaPressure 0;
BA_ "GenSigTimeoutTime_ECU" SG_ 2566912512 FiltNormDPFDeltPresAfteActiRege 5000;
BA_ "GenSigSendType" SG_ 2566912512 FiltNormDPFDeltPresAfteActiRege 0;
BA_ "GenSigTimeoutTime_ECU" SG_ 2566912512 SCRAdapContAdjuFact 5000;
BA_ "GenSigSendType" SG_ 2566912512 SCRAdapContAdjuFact 0;
BA_ "GenSigTimeoutTime_ECU" SG_ 2566912512 MaximumAllowedNH3FlowRate 5000;
BA_ "GenSigSendType" SG_ 2566912512 MaximumAllowedNH3FlowRate 0;
BA_ "GenSigTimeoutTime_ECU" SG_ 2566912512 CharAirCoolEffeLongTermCorrFact 5000;
BA_ "GenSigSendType" SG_ 2566912512 CharAirCoolEffeLongTermCorrFact 0;
BA_ "GenSigTimeoutTime_ECU" SG_ 2566912512 CompInlePresCorrFact 5000;
BA_ "GenSigSendType" SG_ 2566912512 CompInlePresCorrFact 0;
BA_ "GenSigTimeoutTime_ECU" SG_ 2566912512 EGRCoolEffeLongTermCorrFact 5000;
BA_ "GenSigSendType" SG_ 2566912512 EGRCoolEffeLongTermCorrFact 0;
BA_ "GenSigTimeoutTime_ECU" SG_ 2566912512 VTGPosiLongTermCorrOffs 5000;
BA_ "GenSigSendType" SG_ 2566912512 VTGPosiLongTermCorrOffs 0;
BA_ "GenSigTimeoutTime_ECU" SG_ 2566912512 RailPCtrlClsdLoopCmd 5000;
BA_ "GenSigSendType" SG_ 2566912512 RailPCtrlClsdLoopCmd 0;
BA_ "GenSigTimeoutTime_ECU" SG_ 2566912512 IntaManiTempSensEstiUnco 5000;
BA_ "GenSigSendType" SG_ 2566912512 IntaManiTempSensEstiUnco 0;
BA_ "GenSigTimeoutTime_ECU" SG_ 2566912512 CharAirCoolOutlTempSensEstiUnco 5000;
BA_ "GenSigSendType" SG_ 2566912512 CharAirCoolOutlTempSensEstiUnco 0;
BA_ "GenSigTimeoutTime_ECU" SG_ 2566912512 EGRCoolOutlTempSensEstiUnco 5000;
BA_ "GenSigSendType" SG_ 2566912512 EGRCoolOutlTempSensEstiUnco 0;
BA_ "GenSigTimeoutTime_ECU" SG_ 2566912512 EGRGasTemperatureSensor 5000;
BA_ "GenSigSendType" SG_ 2566912512 EGRGasTemperatureSensor 0;
BA_ "GenSigTimeoutTime_ECU" SG_ 2566912512 IntaManiPresEstiUnco 5000;
BA_ "GenSigSendType" SG_ 2566912512 IntaManiPresEstiUnco 0;
BA_ "GenSigTimeoutTime_ECU" SG_ 2566912512 ExhaManiPresSensEstiUnco 5000;
BA_ "GenSigSendType" SG_ 2566912512 ExhaManiPresSensEstiUnco 0;
BA_ "GenSigTimeoutTime_ECU" SG_ 2566912512 ExhaManiPresSensRead 5000;
BA_ "GenSigSendType" SG_ 2566912512 ExhaManiPresSensRead 0;
BA_ "GenSigTimeoutTime_ECU" SG_ 2566912512 CompInteTempSensEstiUnco 5000;
BA_ "GenSigSendType" SG_ 2566912512 CompInteTempSensEstiUnco 0;
BA_ "GenSigTimeoutTime_ECU" SG_ 2566912512 InteCompOutlTempSensRead 5000;
BA_ "GenSigSendType" SG_ 2566912512 InteCompOutlTempSensRead 0;
BA_ "GenSigTimeoutTime_ECU" SG_ 2566912512 CylinderPressurePeak 5000;
BA_ "GenSigSendType" SG_ 2566912512 CylinderPressurePeak 0;
BA_ "GenSigTimeoutTime_ECU" SG_ 2566912512 ExhaManiTempTherEsti 5000;
BA_ "GenSigSendType" SG_ 2566912512 ExhaManiTempTherEsti 0;
BA_ "GenSigTimeoutTime_ECU" SG_ 2634021376 CmdBytePGN65530_ECU 5000;
BA_ "GenSigTimeoutTime_ECU" SG_ 2634021376 TorqueCurveLimit 5000;
BA_ "GenSigSendType" SG_ 2634021376 TorqueCurveLimit 0;
BA_ "GenSigTimeoutTime_ECU" SG_ 2634021376 ExhaManiPresSensFiltOffs 5000;
BA_ "GenSigSendType" SG_ 2634021376 ExhaManiPresSensFiltOffs 0;
BA_ "GenSigTimeoutTime_ECU" SG_ 2634021376 CompressorFlowCorrectionFactor 5000;
BA_ "GenSigSendType" SG_ 2634021376 CompressorFlowCorrectionFactor 0;
BA_ "GenSigTimeoutTime_ECU" SG_ 2634021376 WastMassFlowLongTermCorrFact 5000;
BA_ "GenSigSendType" SG_ 2634021376 WastMassFlowLongTermCorrFact 0;
BA_ "GenSigTimeoutTime_ECU" SG_ 2634021376 ExhaThroPosiLongTermCorrOffs 5000;
BA_ "GenSigSendType" SG_ 2634021376 ExhaThroPosiLongTermCorrOffs 0;
BA_ "GenSigTimeoutTime_ECU" SG_ 2634021376 AECDActiveStatusAll 5000;
BA_ "GenSigSendType" SG_ 2634021376 AECDActiveStatusAll 0;
BA_ "GenSigTimeoutTime_ECU" SG_ 2634021376 WastActuPresLongTermCorrOf 5000;
BA_ "GenSigSendType" SG_ 2634021376 WastActuPresLongTermCorrOf 0;
BA_ "GenSigTimeoutTime_ECU" SG_ 2634021376 IntaManiTempEGRFlowCorrStat 5000;
BA_ "GenSigSendType" SG_ 2634021376 IntaManiTempEGRFlowCorrStat 0;
BA_ "GenSigTimeoutTime_ECU" SG_ 2634021376 AirModeAirThrottleMode 5000;
BA_ "GenSigSendType" SG_ 2634021376 AirModeAirThrottleMode 0;
BA_ "GenSigTimeoutTime_ECU" SG_ 2634021376 AirSystObseInpuConfLeve 5000;
BA_ "GenSigSendType" SG_ 2634021376 AirSystObseInpuConfLeve 0;
BA_ "GenSigTimeoutTime_ECU" SG_ 2634021376 NOxBasedEGRFlowCorrectionState 5000;
BA_ "GenSigSendType" SG_ 2634021376 NOxBasedEGRFlowCorrectionState 0;
BA_ "GenSigTimeoutTime_ECU" SG_ 2634021376 EGRFlowCorrectionActionRequest 5000;
BA_ "GenSigSendType" SG_ 2634021376 EGRFlowCorrectionActionRequest 0;
BA_ "GenSigTimeoutTime_ECU" SG_ 2634021376 AirModeEGRValveMode 5000;
BA_ "GenSigSendType" SG_ 2634021376 AirModeEGRValveMode 0;
BA_ "GenSigTimeoutTime_ECU" SG_ 2634021376 AirModeWastegateSolenoidMode 5000;
BA_ "GenSigSendType" SG_ 2634021376 AirModeWastegateSolenoidMode 0;
BA_ "GenSigTimeoutTime_ECU" SG_ 2634021376 AirModeExhaustThrottleMode 5000;
BA_ "GenSigSendType" SG_ 2634021376 AirModeExhaustThrottleMode 0;
BA_ "GenSigTimeoutTime_ECU" SG_ 2634021376 AirModeVTGMode 5000;
BA_ "GenSigSendType" SG_ 2634021376 AirModeVTGMode 0;
BA_ "GenSigTimeoutTime_ECU" SG_ 2634021376 CharAirCoolMassFlowLongTermCorrFact 5000;
BA_ "GenSigSendType" SG_ 2634021376 CharAirCoolMassFlowLongTermCorrFact 0;
BA_ "GenSigTimeoutTime_ECU" SG_ 2634021376 EGRFlowCorrFactLongTermCorrOffs 5000;
BA_ "GenSigSendType" SG_ 2634021376 EGRFlowCorrFactLongTermCorrOffs 0;
BA_ "GenSigTimeoutTime_ECU" SG_ 2634021376 EGRFlowCorrectionFactor 5000;
BA_ "GenSigSendType" SG_ 2634021376 EGRFlowCorrectionFactor 0;
BA_ "GenSigTimeoutTime_ECU" SG_ 2634021376 TurbMapMassFlowLongTermCorrFact 5000;
BA_ "GenSigSendType" SG_ 2634021376 TurbMapMassFlowLongTermCorrFact 0;
BA_ "GenSigTimeoutTime_ECU" SG_ 2634021376 AirThroPosiLongTermCorrOffs 5000;
BA_ "GenSigSendType" SG_ 2634021376 AirThroPosiLongTermCorrOffs 0;
BA_ "GenSigTimeoutTime_ECU" SG_ 2634021376 EGRValvPosiLongTermCorrOffs 5000;
BA_ "GenSigSendType" SG_ 2634021376 EGRValvPosiLongTermCorrOffs 0;
BA_ "GenSigTimeoutTime_ECU" SG_ 2365587219 CmdBytePGN65535_ATX 5000;
BA_ "GenSigTimeoutTime_ECU" SG_ 2365587219 AutoTracWheelbase_AGSR 5000;
BA_ "GenSigSendType" SG_ 2365587219 AutoTracWheelbase_AGSR 0;
BA_ "GenSigTimeoutTime_ECU" SG_ 2365587219 AutoTracSysCtlrLoSpdLim 5000;
BA_ "GenSigSendType" SG_ 2365587219 AutoTracSysCtlrLoSpdLim 0;
BA_ "GenSigTimeoutTime_ECU" SG_ 2365587219 AutoTracSysCtlrUpSpdLim 5000;
BA_ "GenSigSendType" SG_ 2365587219 AutoTracSysCtlrUpSpdLim 0;
BA_ "GenSigTimeoutTime_ECU" SG_ 2365587219 AutoTracSysCtlrUnlimitRevCapable 5000;
BA_ "GenSigSendType" SG_ 2365587219 AutoTracSysCtlrUnlimitRevCapable 0;
BA_ "GenSigTimeoutTime_ECU" SG_ 2365587219 AuxResuCap 5000;
BA_ "GenSigSendType" SG_ 2365587219 AuxResuCap 0;
BA_ "GenSigTimeoutTime_ECU" SG_ 2365587219 WASType 5000;
BA_ "GenSigSendType" SG_ 2365587219 WASType 0;
BA_ "GenSigTimeoutTime_ECU" SG_ 2365587219 MaxReverseSpeed 5000;
BA_ "GenSigSendType" SG_ 2365587219 MaxReverseSpeed 0;
BA_ "GenSigTimeoutTime_ECU" SG_ 2365587219 ConfigMachineClass 5000;
BA_ "GenSigSendType" SG_ 2365587219 ConfigMachineClass 0;
BA_ "GenSigTimeoutTime_ECU" SG_ 2365587219 SIDType 5000;
BA_ "GenSigSendType" SG_ 2365587219 SIDType 0;
BA_ "GenSigTimeoutTime_ECU" SG_ 2365587219 ActuatorType 5000;
BA_ "GenSigSendType" SG_ 2365587219 ActuatorType 0;
BA_ "GenSigTimeoutTime_ECU" SG_ 2365587219 StarfireFwdCfg_AGSR 5000;
BA_ "GenSigSendType" SG_ 2365587219 StarfireFwdCfg_AGSR 0;
BA_ "GenSigTimeoutTime_ECU" SG_ 2499805170 CmdBytePGN65535_PDC 5000;
BA_ "GenSigTimeoutTime_ECU" SG_ 2499805170 VehWheelbase 5000;
BA_ "GenSigSendType" SG_ 2499805170 VehWheelbase 0;
BA_ "GenSigTimeoutTime_ECU" SG_ 2499805170 AutoTracSysLoSpdLimRqst 5000;
BA_ "GenSigSendType" SG_ 2499805170 AutoTracSysLoSpdLimRqst 0;
BA_ "GenSigTimeoutTime_ECU" SG_ 2499805170 AutoTracSysUpSpdLimRqst 5000;
BA_ "GenSigSendType" SG_ 2499805170 AutoTracSysUpSpdLimRqst 0;
BA_ "GenSigTimeoutTime_ECU" SG_ 2499805170 AutoTracSysUnlimitRevCapable 5000;
BA_ "GenSigSendType" SG_ 2499805170 AutoTracSysUnlimitRevCapable 0;
BA_ "GenSigTimeoutTime_ECU" SG_ 2499805170 AuxResuCapRqst 5000;
BA_ "GenSigSendType" SG_ 2499805170 AuxResuCapRqst 0;
BA_ "GenSigTimeoutTime_ECU" SG_ 2499805170 WASTypeInstalled 5000;
BA_ "GenSigSendType" SG_ 2499805170 WASTypeInstalled 0;
BA_ "GenSigTimeoutTime_ECU" SG_ 2499805170 MaxReverseSpeedRqst 5000;
BA_ "GenSigSendType" SG_ 2499805170 MaxReverseSpeedRqst 0;
BA_ "GenSigTimeoutTime_ECU" SG_ 2499805170 ActualMachineClass 5000;
BA_ "GenSigSendType" SG_ 2499805170 ActualMachineClass 0;
BA_ "GenSigTimeoutTime_ECU" SG_ 2499805170 SIDTypeRqst 5000;
BA_ "GenSigSendType" SG_ 2499805170 SIDTypeRqst 0;
BA_ "GenSigTimeoutTime_ECU" SG_ 2499805170 ActuatorTypeRqst 5000;
BA_ "GenSigSendType" SG_ 2499805170 ActuatorTypeRqst 0;
BA_ "GenSigTimeoutTime_ECU" SG_ 2499805170 StarfireFwdCfgRqst 5000;
BA_ "GenSigSendType" SG_ 2499805170 StarfireFwdCfgRqst 0;
BA_ "GenSigTimeoutTime_ECU" SG_ 2634020864 CmdBytePGN65528_ECU 5000;
BA_ "GenSigTimeoutTime_ECU" SG_ 2634020864 AftrtrtmntSCRObsNOxCnvrsnEff 5000;
BA_ "GenSigSendType" SG_ 2634020864 AftrtrtmntSCRObsNOxCnvrsnEff 0;
BA_ "GenSigTimeoutTime_ECU" SG_ 2634020864 AftrtrtmntOutNOxTailCnt 5000;
BA_ "GenSigSendType" SG_ 2634020864 AftrtrtmntOutNOxTailCnt 0;
BA_ "GenSigTimeoutTime_ECU" SG_ 2634020864 SCRNOXCEMonState 5000;
BA_ "GenSigSendType" SG_ 2634020864 SCRNOXCEMonState 0;
BA_ "GenSigTimeoutTime_ECU" SG_ 2634020864 SCRAdapConDisable 5000;
BA_ "GenSigSendType" SG_ 2634020864 SCRAdapConDisable 0;
BA_ "GenSigTimeoutTime_ECU" SG_ 2634020864 SCRAdapConAdjFactor 5000;
BA_ "GenSigSendType" SG_ 2634020864 SCRAdapConAdjFactor 0;
BA_ "GenSigTimeoutTime_ECU" SG_ 2566910995 CmdBytePGN65524_ATX 500;
BA_ "GenSigTimeoutTime_ECU" SG_ 2566910995 SteeredWheelAngle 500;
BA_ "GenSigSendType" SG_ 2566910995 SteeredWheelAngle 0;
BA_ "GenSigTimeoutTime_ECU" SG_ 2566910995 CrvtrCntrlATState_ATSV 500;
BA_ "GenSigSendType" SG_ 2566910995 CrvtrCntrlATState_ATSV 0;
BA_ "GenSigTimeoutTime_ECU" SG_ 2566910995 RedSteerWarnLightRequest 500;
BA_ "GenSigSendType" SG_ 2566910995 RedSteerWarnLightRequest 0;
BA_ "GenSigTimeoutTime_ECU" SG_ 2566910995 Heartbeat 500;
BA_ "GenSigSendType" SG_ 2566910995 Heartbeat 0;
BA_ "GenSigTimeoutTime_ECU" SG_ 2566910995 AT2ExitCode_GMSJDE 500;
BA_ "GenSigSendType" SG_ 2566910995 AT2ExitCode_GMSJDE 0;
BA_ "GenSigTimeoutTime_ECU" SG_ 2566910995 WheelBasedVehicleSpeed_GMSJDE 500;
BA_ "GenSigSendType" SG_ 2566910995 WheelBasedVehicleSpeed_GMSJDE 0;
BA_ "GenSigTimeoutTime_ECU" SG_ 2566910995 VehDirection 500;
BA_ "GenSigSendType" SG_ 2566910995 VehDirection 0;
BA_ "GenSigTimeoutTime_ECU" SG_ 2566910995 AutoTracSystemState 500;
BA_ "GenSigSendType" SG_ 2566910995 AutoTracSystemState 0;
BA_ "GenSigTimeoutTime_ECU" SG_ 2566910995 StarfireFwdCfg_GMSJDE 500;
BA_ "GenSigSendType" SG_ 2566910995 StarfireFwdCfg_GMSJDE 0;
BA_ "GenSigTimeoutTime_ECU" SG_ 2566910995 ActivateGuidanceRequest 500;
BA_ "GenSigSendType" SG_ 2566910995 ActivateGuidanceRequest 0;
BA_ "GenSigTimeoutTime_ECU" SG_ 2566910995 AuxiliarySteerMode 500;
BA_ "GenSigSendType" SG_ 2566910995 AuxiliarySteerMode 0;
BA_ "GenSigTimeoutTime_ECU" SG_ 2566910995 Heartbeat 500;
BA_ "GenSigSendType" SG_ 2566910995 Heartbeat 0;
BA_ "GenSigTimeoutTime_ECU" SG_ 2365584382 CmdBytePGN65523_Vector_XXX 200;
BA_ "GenSigTimeoutTime_ECU" SG_ 2365584382 ParkBrakeReq 200;
BA_ "GenSigSendType" SG_ 2365584382 ParkBrakeReq 0;
BA_ "GenSigTimeoutTime_ECU" SG_ 2365584382 HydHndlState 200;
BA_ "GenSigSendType" SG_ 2365584382 HydHndlState 0;
BA_ "GenSigTimeoutTime_ECU" SG_ 2566913539 CmdBytePGN65534_PBS 60000;
BA_ "GenSigTimeoutTime_ECU" SG_ 2566913778 CmdBytePGN65534_PDC 60000;
BA_ "GenSigTimeoutTime_ECU" SG_ 2566913727 CmdBytePGN65534_PDE 60000;
BA_ "GenSigTimeoutTime_ECU" SG_ 2632909571 CmdBytePGN61184_PBS 60000;
BA_ "GenMsgCycleTime" BO_ 2565406464 60000;
BA_ "SingleFrame" BO_ 2565406464 1;
BA_ "GenMsgCycleTime" BO_ 2565406467 60000;
BA_ "SingleFrame" BO_ 2565406467 1;
BA_ "GenMsgCycleTime" BO_ 2565406706 60000;
BA_ "SingleFrame" BO_ 2565406706 1;
BA_ "GenMsgCycleTime" BO_ 2565406655 60000;
BA_ "SingleFrame" BO_ 2565406655 1;
BA_ "GenMsgCycleTime" BO_ 2565341952 60000;
BA_ "SingleFrame" BO_ 2565341952 1;
BA_ "GenMsgCycleTime" BO_ 2565403136 60000;
BA_ "SingleFrame" BO_ 2565403136 1;
BA_ "GenMsgCycleTime" BO_ 2565390080 60000;
BA_ "SingleFrame" BO_ 2565390080 1;
BA_ "GenMsgCycleTime" BO_ 2565341187 60000;
BA_ "SingleFrame" BO_ 2565341187 1;
BA_ "GenMsgCycleTime" BO_ 2565403139 60000;
BA_ "SingleFrame" BO_ 2565403139 1;
BA_ "GenMsgCycleTime" BO_ 2565390083 60000;
BA_ "SingleFrame" BO_ 2565390083 1;
BA_ "GenMsgCycleTime" BO_ 2565341955 60000;
BA_ "SingleFrame" BO_ 2565341955 1;
BA_ "GenMsgCycleTime" BO_ 2565341426 60000;
BA_ "SingleFrame" BO_ 2565341426 1;
BA_ "GenMsgCycleTime" BO_ 2565342194 60000;
BA_ "SingleFrame" BO_ 2565342194 1;
BA_ "GenMsgCycleTime" BO_ 2565390322 60000;
BA_ "SingleFrame" BO_ 2565390322 1;
BA_ "GenMsgCycleTime" BO_ 2565341375 60000;
BA_ "SingleFrame" BO_ 2565341375 1;
BA_ "GenMsgCycleTime" BO_ 2565342143 60000;
BA_ "SingleFrame" BO_ 2565342143 1;
BA_ "GenMsgCycleTime" BO_ 2565403327 60000;
BA_ "SingleFrame" BO_ 2565403327 1;
BA_ "GenMsgCycleTime" BO_ 2565799680 60000;
BA_ "SingleFrame" BO_ 2565799680 1;
BA_ "GenMsgCycleTime" BO_ 2565799683 60000;
BA_ "SingleFrame" BO_ 2565799683 1;
BA_ "GenMsgCycleTime" BO_ 2565799922 60000;
BA_ "SingleFrame" BO_ 2565799922 1;
BA_ "GenMsgCycleTime" BO_ 2565799871 60000;
BA_ "SingleFrame" BO_ 2565799871 1;
BA_ "GenMsgCycleTime" BO_ 2566757120 1000;
BA_ "GenMsgSendType" BO_ 2566757120 0;
BA_ "GenMsgCycleTimeFast" BO_ 2566757120 1000;
BA_ "SingleFrame" BO_ 2566757120 1;
BA_ "GenMsgCycleTime" BO_ 2566804992 1000;
BA_ "GenMsgSendType" BO_ 2566804992 0;
BA_ "GenMsgCycleTimeFast" BO_ 2566804992 1000;
BA_ "SingleFrame" BO_ 2566804992 1;
BA_ "GenMsgCycleTime" BO_ 2566748928 60000;
BA_ "GenMsgSendType" BO_ 2566748928 0;
BA_ "GenMsgCycleTimeFast" BO_ 2566748928 100;
BA_ "SingleFrame" BO_ 2566748928 1;
BA_ "GenMsgCycleTime" BO_ 2566763264 500;
BA_ "GenMsgSendType" BO_ 2566763264 0;
BA_ "GenMsgCycleTimeFast" BO_ 2566763264 500;
BA_ "SingleFrame" BO_ 2566763264 1;
BA_ "GenMsgCycleTime" BO_ 2566700288 60000;
BA_ "GenMsgSendType" BO_ 2566700288 0;
BA_ "GenMsgCycleTimeFast" BO_ 2566700288 60000;
BA_ "SingleFrame" BO_ 2566700288 1;
BA_ "GenMsgCycleTime" BO_ 2565874432 50;
BA_ "GenMsgSendType" BO_ 2565874432 0;
BA_ "GenMsgCycleTimeFast" BO_ 2565874432 50;
BA_ "SingleFrame" BO_ 2565874432 1;
BA_ "GenMsgCycleTime" BO_ 2566845696 1000;
BA_ "GenMsgSendType" BO_ 2566845696 0;
BA_ "GenMsgCycleTimeFast" BO_ 2566845696 1000;
BA_ "SingleFrame" BO_ 2566845696 1;
BA_ "GenMsgCycleTime" BO_ 2564292352 60000;
BA_ "SingleFrame" BO_ 2564292352 1;
BA_ "GenMsgCycleTime" BO_ 2628387070 60000;
BA_ "GenMsgSendType" BO_ 2628387070 0;
BA_ "GenMsgCycleTimeFast" BO_ 2628387070 60000;
BA_ "SingleFrame" BO_ 2628387070 1;
BA_ "GenMsgCycleTime" BO_ 2628387838 60000;
BA_ "GenMsgSendType" BO_ 2628387838 0;
BA_ "GenMsgCycleTimeFast" BO_ 2628387838 60000;
BA_ "SingleFrame" BO_ 2628387838 1;
BA_ "GenMsgCycleTime" BO_ 2628449022 60000;
BA_ "GenMsgSendType" BO_ 2628449022 0;
BA_ "GenMsgCycleTimeFast" BO_ 2628449022 60000;
BA_ "SingleFrame" BO_ 2628449022 1;
BA_ "GenMsgCycleTime" BO_ 2628435966 60000;
BA_ "GenMsgSendType" BO_ 2628435966 0;
BA_ "GenMsgCycleTimeFast" BO_ 2628435966 60000;
BA_ "SingleFrame" BO_ 2628435966 1;
BA_ "GenMsgCycleTime" BO_ 2628452350 60000;
BA_ "GenMsgSendType" BO_ 2628452350 0;
BA_ "GenMsgCycleTimeFast" BO_ 2628452350 60000;
BA_ "SingleFrame" BO_ 2628452350 1;
BA_ "GenMsgCycleTime" BO_ 2566838272 60000;
BA_ "GenMsgCycleTime" BO_ 2566838275 60000;
BA_ "GenMsgCycleTime" BO_ 2566838514 60000;
BA_ "GenMsgCycleTime" BO_ 2566838463 60000;
BA_ "GenMsgCycleTime" BO_ 2298409219 100;
BA_ "GenMsgSendType" BO_ 2298409219 0;
BA_ "GenMsgCycleTimeFast" BO_ 2298409219 100;
BA_ "SingleFrame" BO_ 2298409219 1;
BA_ "GenMsgCycleTime" BO_ 2566850816 60000;
BA_ "SingleFrame" BO_ 2566850816 1;
BA_ "GenMsgCycleTime" BO_ 2566850819 60000;
BA_ "SingleFrame" BO_ 2566850819 1;
BA_ "GenMsgCycleTime" BO_ 2566851058 60000;
BA_ "SingleFrame" BO_ 2566851058 1;
BA_ "GenMsgCycleTime" BO_ 2566851007 60000;
BA_ "SingleFrame" BO_ 2566851007 1;
BA_ "GenMsgCycleTime" BO_ 2566730243 60000;
BA_ "SingleFrame" BO_ 2566730243 1;
BA_ "GenMsgCycleTime" BO_ 2566730431 60000;
BA_ "SingleFrame" BO_ 2566730431 1;
BA_ "GenMsgCycleTime" BO_ 2562719507 60000;
BA_ "SingleFrame" BO_ 2562719507 1;
BA_ "GenMsgCycleTime" BO_ 2562719488 60000;
BA_ "SingleFrame" BO_ 2562719488 1;
BA_ "GenMsgCycleTime" BO_ 2562719491 60000;
BA_ "SingleFrame" BO_ 2562719491 1;
BA_ "GenMsgCycleTime" BO_ 2562719679 60000;
BA_ "SingleFrame" BO_ 2562719679 1;
BA_ "GenMsgCycleTime" BO_ 2566749184 1000;
BA_ "GenMsgSendType" BO_ 2566749184 0;
BA_ "GenMsgCycleTimeFast" BO_ 2566749184 1000;
BA_ "SingleFrame" BO_ 2566749184 1;
BA_ "GenMsgCycleTime" BO_ 2566837011 60000;
BA_ "SingleFrame" BO_ 2566837011 1;
BA_ "GenMsgCycleTime" BO_ 2566836992 60000;
BA_ "SingleFrame" BO_ 2566836992 1;
BA_ "GenMsgCycleTime" BO_ 2566836995 60000;
BA_ "SingleFrame" BO_ 2566836995 1;
BA_ "GenMsgCycleTime" BO_ 2566837234 60000;
BA_ "SingleFrame" BO_ 2566837234 1;
BA_ "GenMsgCycleTime" BO_ 2566837183 60000;
BA_ "SingleFrame" BO_ 2566837183 1;
BA_ "GenMsgCycleTime" BO_ 2564816894 60000;
BA_ "GenMsgSendType" BO_ 2564816894 0;
BA_ "GenMsgCycleTimeFast" BO_ 2564816894 60000;
BA_ "SingleFrame" BO_ 2564816894 1;
BA_ "GenMsgCycleTime" BO_ 2566834707 60000;
BA_ "SingleFrame" BO_ 2566834707 1;
BA_ "GenMsgCycleTime" BO_ 2566834688 60000;
BA_ "SingleFrame" BO_ 2566834688 1;
BA_ "GenMsgCycleTime" BO_ 2566834691 60000;
BA_ "SingleFrame" BO_ 2566834691 1;
BA_ "GenMsgCycleTime" BO_ 2566834879 60000;
BA_ "SingleFrame" BO_ 2566834879 1;
BA_ "GenMsgCycleTime" BO_ 2566834963 60000;
BA_ "SingleFrame" BO_ 2566834963 1;
BA_ "GenMsgCycleTime" BO_ 2566834944 60000;
BA_ "SingleFrame" BO_ 2566834944 1;
BA_ "GenMsgCycleTime" BO_ 2566834947 60000;
BA_ "SingleFrame" BO_ 2566834947 1;
BA_ "GenMsgCycleTime" BO_ 2566835135 60000;
BA_ "SingleFrame" BO_ 2566835135 1;
BA_ "GenMsgCycleTime" BO_ 2566835219 60000;
BA_ "SingleFrame" BO_ 2566835219 1;
BA_ "GenMsgCycleTime" BO_ 2566835200 60000;
BA_ "SingleFrame" BO_ 2566835200 1;
BA_ "GenMsgCycleTime" BO_ 2566835203 60000;
BA_ "SingleFrame" BO_ 2566835203 1;
BA_ "GenMsgCycleTime" BO_ 2566835442 60000;
BA_ "SingleFrame" BO_ 2566835442 1;
BA_ "GenMsgCycleTime" BO_ 2566835391 60000;
BA_ "SingleFrame" BO_ 2566835391 1;
BA_ "GenMsgCycleTime" BO_ 2566835456 60000;
BA_ "GenMsgCycleTime" BO_ 2566835459 60000;
BA_ "GenMsgCycleTime" BO_ 2566835712 60000;
BA_ "SingleFrame" BO_ 2566835712 1;
BA_ "GenMsgCycleTime" BO_ 2566835715 60000;
BA_ "SingleFrame" BO_ 2566835715 1;
BA_ "GenMsgCycleTime" BO_ 2566835954 60000;
BA_ "SingleFrame" BO_ 2566835954 1;
BA_ "GenMsgCycleTime" BO_ 2566835903 60000;
BA_ "SingleFrame" BO_ 2566835903 1;
BA_ "GenMsgCycleTime" BO_ 2566767872 60000;
BA_ "SingleFrame" BO_ 2566767872 1;
BA_ "GenMsgCycleTime" BO_ 2566767875 60000;
BA_ "SingleFrame" BO_ 2566767875 1;
BA_ "GenMsgCycleTime" BO_ 2566768114 60000;
BA_ "SingleFrame" BO_ 2566768114 1;
BA_ "GenMsgCycleTime" BO_ 2566768063 60000;
BA_ "SingleFrame" BO_ 2566768063 1;
BA_ "GenMsgCycleTime" BO_ 2565276416 60000;
BA_ "SingleFrame" BO_ 2565276416 1;
BA_ "GenMsgCycleTime" BO_ 2565337600 60000;
BA_ "SingleFrame" BO_ 2565337600 1;
BA_ "GenMsgCycleTime" BO_ 2565324544 60000;
BA_ "SingleFrame" BO_ 2565324544 1;
BA_ "GenMsgCycleTime" BO_ 2565275651 60000;
BA_ "SingleFrame" BO_ 2565275651 1;
BA_ "GenMsgCycleTime" BO_ 2565337603 60000;
BA_ "SingleFrame" BO_ 2565337603 1;
BA_ "GenMsgCycleTime" BO_ 2565324547 60000;
BA_ "SingleFrame" BO_ 2565324547 1;
BA_ "GenMsgCycleTime" BO_ 2565275890 60000;
BA_ "SingleFrame" BO_ 2565275890 1;
BA_ "GenMsgCycleTime" BO_ 2565276658 60000;
BA_ "SingleFrame" BO_ 2565276658 1;
BA_ "GenMsgCycleTime" BO_ 2565324786 60000;
BA_ "SingleFrame" BO_ 2565324786 1;
BA_ "GenMsgCycleTime" BO_ 2565275839 60000;
BA_ "SingleFrame" BO_ 2565275839 1;
BA_ "GenMsgCycleTime" BO_ 2565276607 60000;
BA_ "SingleFrame" BO_ 2565276607 1;
BA_ "GenMsgCycleTime" BO_ 2565337791 60000;
BA_ "SingleFrame" BO_ 2565337791 1;
BA_ "GenMsgCycleTime" BO_ 2565340928 60000;
BA_ "SingleFrame" BO_ 2565340928 1;
BA_ "GenMsgCycleTime" BO_ 2565340931 60000;
BA_ "SingleFrame" BO_ 2565340931 1;
BA_ "GenMsgCycleTime" BO_ 2565341170 60000;
BA_ "SingleFrame" BO_ 2565341170 1;
BA_ "GenMsgCycleTime" BO_ 2565341119 60000;
BA_ "SingleFrame" BO_ 2565341119 1;
BA_ "GenMsgCycleTime" BO_ 2364539904 20;
BA_ "GenMsgSendType" BO_ 2364539904 0;
BA_ "GenMsgCycleTimeFast" BO_ 2364539904 20;
BA_ "SingleFrame" BO_ 2364539904 1;
BA_ "GenMsgCycleTime" BO_ 2364539648 50;
BA_ "GenMsgSendType" BO_ 2364539648 0;
BA_ "GenMsgCycleTimeFast" BO_ 2364539648 50;
BA_ "SingleFrame" BO_ 2364539648 1;
BA_ "GenMsgCycleTime" BO_ 2566840064 100;
BA_ "GenMsgSendType" BO_ 2566840064 0;
BA_ "GenMsgCycleTimeFast" BO_ 2566840064 100;
BA_ "SingleFrame" BO_ 2566840064 1;
BA_ "GenMsgCycleTime" BO_ 2566844160 500;
BA_ "GenMsgSendType" BO_ 2566844160 0;
BA_ "GenMsgCycleTimeFast" BO_ 2566844160 500;
BA_ "SingleFrame" BO_ 2566844160 1;
BA_ "GenMsgCycleTime" BO_ 2566841088 5000;
BA_ "GenMsgSendType" BO_ 2566841088 0;
BA_ "GenMsgCycleTimeFast" BO_ 2566841088 5000;
BA_ "GenMsgCycleTime" BO_ 2566841600 60000;
BA_ "GenMsgSendType" BO_ 2566841600 0;
BA_ "GenMsgCycleTimeFast" BO_ 2566841600 60000;
BA_ "SingleFrame" BO_ 2566841600 1;
BA_ "GenMsgCycleTime" BO_ 2566843904 1000;
BA_ "GenMsgSendType" BO_ 2566843904 0;
BA_ "GenMsgCycleTimeFast" BO_ 2566843904 1000;
BA_ "SingleFrame" BO_ 2566843904 1;
BA_ "GenMsgCycleTime" BO_ 2432537342 250;
BA_ "GenMsgSendType" BO_ 2432537342 0;
BA_ "GenMsgCycleTimeFast" BO_ 2432537342 100;
BA_ "SingleFrame" BO_ 2432537342 1;
BA_ "GenMsgCycleTime" BO_ 2431708670 1000;
BA_ "GenMsgSendType" BO_ 2431708670 0;
BA_ "GenMsgCycleTimeFast" BO_ 2431708670 100;
BA_ "SingleFrame" BO_ 2431708670 1;
BA_ "GenMsgCycleTime" BO_ 2566809856 1000;
BA_ "GenMsgSendType" BO_ 2566809856 0;
BA_ "GenMsgCycleTimeFast" BO_ 2566809856 1000;
BA_ "SingleFrame" BO_ 2566809856 1;
BA_ "GenMsgCycleTime" BO_ 2563309331 60000;
BA_ "SingleFrame" BO_ 2563309331 1;
BA_ "GenMsgCycleTime" BO_ 2563309312 60000;
BA_ "SingleFrame" BO_ 2563309312 1;
BA_ "GenMsgCycleTime" BO_ 2563309315 60000;
BA_ "SingleFrame" BO_ 2563309315 1;
BA_ "GenMsgCycleTime" BO_ 2563309554 60000;
BA_ "SingleFrame" BO_ 2563309554 1;
BA_ "GenMsgCycleTime" BO_ 2563309503 60000;
BA_ "SingleFrame" BO_ 2563309503 1;
BA_ "GenMsgCycleTime" BO_ 2563244051 60000;
BA_ "SingleFrame" BO_ 2563244051 1;
BA_ "GenMsgCycleTime" BO_ 2563244819 60000;
BA_ "SingleFrame" BO_ 2563244819 1;
BA_ "GenMsgCycleTime" BO_ 2563306003 60000;
BA_ "SingleFrame" BO_ 2563306003 1;
BA_ "GenMsgCycleTime" BO_ 2563292947 60000;
BA_ "SingleFrame" BO_ 2563292947 1;
BA_ "GenMsgCycleTime" BO_ 2563248896 60000;
BA_ "SingleFrame" BO_ 2563248896 1;
BA_ "GenMsgCycleTime" BO_ 2563244800 60000;
BA_ "SingleFrame" BO_ 2563244800 1;
BA_ "GenMsgCycleTime" BO_ 2563305984 60000;
BA_ "SingleFrame" BO_ 2563305984 1;
BA_ "GenMsgCycleTime" BO_ 2563292928 60000;
BA_ "SingleFrame" BO_ 2563292928 1;
BA_ "GenMsgCycleTime" BO_ 2563248899 60000;
BA_ "SingleFrame" BO_ 2563248899 1;
BA_ "GenMsgCycleTime" BO_ 2563244035 60000;
BA_ "SingleFrame" BO_ 2563244035 1;
BA_ "GenMsgCycleTime" BO_ 2563305987 60000;
BA_ "SingleFrame" BO_ 2563305987 1;
BA_ "GenMsgCycleTime" BO_ 2563292931 60000;
BA_ "SingleFrame" BO_ 2563292931 1;
BA_ "GenMsgCycleTime" BO_ 2563244803 60000;
BA_ "SingleFrame" BO_ 2563244803 1;
BA_ "GenMsgCycleTime" BO_ 2563249138 60000;
BA_ "SingleFrame" BO_ 2563249138 1;
BA_ "GenMsgCycleTime" BO_ 2563244274 60000;
BA_ "SingleFrame" BO_ 2563244274 1;
BA_ "GenMsgCycleTime" BO_ 2563245042 60000;
BA_ "SingleFrame" BO_ 2563245042 1;
BA_ "GenMsgCycleTime" BO_ 2563293170 60000;
BA_ "SingleFrame" BO_ 2563293170 1;
BA_ "GenMsgCycleTime" BO_ 2563249087 60000;
BA_ "SingleFrame" BO_ 2563249087 1;
BA_ "GenMsgCycleTime" BO_ 2563244223 60000;
BA_ "SingleFrame" BO_ 2563244223 1;
BA_ "GenMsgCycleTime" BO_ 2563244991 60000;
BA_ "SingleFrame" BO_ 2563244991 1;
BA_ "GenMsgCycleTime" BO_ 2563306175 60000;
BA_ "SingleFrame" BO_ 2563306175 1;
BA_ "GenMsgCycleTime" BO_ 2563243795 60000;
BA_ "SingleFrame" BO_ 2563243795 1;
BA_ "GenMsgCycleTime" BO_ 2563243776 60000;
BA_ "SingleFrame" BO_ 2563243776 1;
BA_ "GenMsgCycleTime" BO_ 2563243779 60000;
BA_ "SingleFrame" BO_ 2563243779 1;
BA_ "GenMsgCycleTime" BO_ 2563244018 60000;
BA_ "SingleFrame" BO_ 2563244018 1;
BA_ "GenMsgCycleTime" BO_ 2563243967 60000;
BA_ "SingleFrame" BO_ 2563243967 1;
BA_ "GenMsgCycleTime" BO_ 2563178515 60000;
BA_ "SingleFrame" BO_ 2563178515 1;
BA_ "GenMsgCycleTime" BO_ 2563179283 60000;
BA_ "SingleFrame" BO_ 2563179283 1;
BA_ "GenMsgCycleTime" BO_ 2563240467 60000;
BA_ "SingleFrame" BO_ 2563240467 1;
BA_ "GenMsgCycleTime" BO_ 2563227411 60000;
BA_ "SingleFrame" BO_ 2563227411 1;
BA_ "GenMsgCycleTime" BO_ 2563183360 60000;
BA_ "SingleFrame" BO_ 2563183360 1;
BA_ "GenMsgCycleTime" BO_ 2563179264 60000;
BA_ "SingleFrame" BO_ 2563179264 1;
BA_ "GenMsgCycleTime" BO_ 2563240448 60000;
BA_ "SingleFrame" BO_ 2563240448 1;
BA_ "GenMsgCycleTime" BO_ 2563227392 60000;
BA_ "SingleFrame" BO_ 2563227392 1;
BA_ "GenMsgCycleTime" BO_ 2563183363 60000;
BA_ "SingleFrame" BO_ 2563183363 1;
BA_ "GenMsgCycleTime" BO_ 2563178499 60000;
BA_ "SingleFrame" BO_ 2563178499 1;
BA_ "GenMsgCycleTime" BO_ 2563240451 60000;
BA_ "SingleFrame" BO_ 2563240451 1;
BA_ "GenMsgCycleTime" BO_ 2563227395 60000;
BA_ "SingleFrame" BO_ 2563227395 1;
BA_ "GenMsgCycleTime" BO_ 2563179267 60000;
BA_ "SingleFrame" BO_ 2563179267 1;
BA_ "GenMsgCycleTime" BO_ 2563183602 60000;
BA_ "SingleFrame" BO_ 2563183602 1;
BA_ "GenMsgCycleTime" BO_ 2563178738 60000;
BA_ "SingleFrame" BO_ 2563178738 1;
BA_ "GenMsgCycleTime" BO_ 2563179506 60000;
BA_ "SingleFrame" BO_ 2563179506 1;
BA_ "GenMsgCycleTime" BO_ 2563227634 60000;
BA_ "SingleFrame" BO_ 2563227634 1;
BA_ "GenMsgCycleTime" BO_ 2563183551 60000;
BA_ "SingleFrame" BO_ 2563183551 1;
BA_ "GenMsgCycleTime" BO_ 2563178687 60000;
BA_ "SingleFrame" BO_ 2563178687 1;
BA_ "GenMsgCycleTime" BO_ 2563179455 60000;
BA_ "SingleFrame" BO_ 2563179455 1;
BA_ "GenMsgCycleTime" BO_ 2563240639 60000;
BA_ "SingleFrame" BO_ 2563240639 1;
BA_ "GenMsgCycleTime" BO_ 2628517632 60000;
BA_ "SingleFrame" BO_ 2628517632 1;
BA_ "GenMsgCycleTime" BO_ 2628517635 60000;
BA_ "SingleFrame" BO_ 2628517635 1;
BA_ "GenMsgCycleTime" BO_ 2628517874 60000;
BA_ "SingleFrame" BO_ 2628517874 1;
BA_ "GenMsgCycleTime" BO_ 2628517823 60000;
BA_ "SingleFrame" BO_ 2628517823 1;
BA_ "GenMsgCycleTime" BO_ 2628453120 60000;
BA_ "SingleFrame" BO_ 2628453120 1;
BA_ "GenMsgCycleTime" BO_ 2628514304 60000;
BA_ "SingleFrame" BO_ 2628514304 1;
BA_ "GenMsgCycleTime" BO_ 2628501248 60000;
BA_ "SingleFrame" BO_ 2628501248 1;
BA_ "GenMsgCycleTime" BO_ 2628452355 60000;
BA_ "SingleFrame" BO_ 2628452355 1;
BA_ "GenMsgCycleTime" BO_ 2628514307 60000;
BA_ "SingleFrame" BO_ 2628514307 1;
BA_ "GenMsgCycleTime" BO_ 2628501251 60000;
BA_ "SingleFrame" BO_ 2628501251 1;
BA_ "GenMsgCycleTime" BO_ 2628452594 60000;
BA_ "SingleFrame" BO_ 2628452594 1;
BA_ "GenMsgCycleTime" BO_ 2628453362 60000;
BA_ "SingleFrame" BO_ 2628453362 1;
BA_ "GenMsgCycleTime" BO_ 2628501490 60000;
BA_ "SingleFrame" BO_ 2628501490 1;
BA_ "GenMsgCycleTime" BO_ 2628452543 60000;
BA_ "SingleFrame" BO_ 2628452543 1;
BA_ "GenMsgCycleTime" BO_ 2628453311 60000;
BA_ "SingleFrame" BO_ 2628453311 1;
BA_ "GenMsgCycleTime" BO_ 2628514495 60000;
BA_ "SingleFrame" BO_ 2628514495 1;
BA_ "GenMsgCycleTime" BO_ 2566842624 5000;
BA_ "GenMsgSendType" BO_ 2566842624 0;
BA_ "GenMsgCycleTimeFast" BO_ 2566842624 5000;
BA_ "SingleFrame" BO_ 2566842624 1;
BA_ "GenMsgCycleTime" BO_ 2566844928 100;
BA_ "GenMsgSendType" BO_ 2566844928 0;
BA_ "GenMsgCycleTimeFast" BO_ 2566844928 100;
BA_ "SingleFrame" BO_ 2566844928 1;
BA_ "GenMsgCycleTime" BO_ 2360147731 100;
BA_ "GenMsgSendType" BO_ 2360147731 0;
BA_ "GenMsgCycleTimeFast" BO_ 2360147731 100;
BA_ "SingleFrame" BO_ 2360147731 1;
BA_ "GenMsgCycleTime" BO_ 2360213502 100;
BA_ "GenMsgSendType" BO_ 2360213502 0;
BA_ "GenMsgCycleTimeFast" BO_ 2360213502 100;
BA_ "SingleFrame" BO_ 2360213502 1;
BA_ "GenMsgCycleTime" BO_ 2365529086 50;
BA_ "GenMsgSendType" BO_ 2365529086 0;
BA_ "GenMsgCycleTimeFast" BO_ 2365529086 50;
BA_ "SingleFrame" BO_ 2365529086 1;
BA_ "GenMsgCycleTime" BO_ 2566845952 500;
BA_ "GenMsgSendType" BO_ 2566845952 0;
BA_ "GenMsgCycleTimeFast" BO_ 2566845952 500;
BA_ "SingleFrame" BO_ 2566845952 1;
BA_ "GenMsgCycleTime" BO_ 2173485042 10;
BA_ "SingleFrame" BO_ 2173485042 1;
BA_ "GenMsgCycleTime" BO_ 2173432511 10;
BA_ "SingleFrame" BO_ 2173432511 1;
BA_ "GenMsgCycleTime" BO_ 2173501426 10;
BA_ "SingleFrame" BO_ 2173501426 1;
BA_ "GenMsgCycleTime" BO_ 2173435839 10;
BA_ "SingleFrame" BO_ 2173435839 1;
BA_ "GenMsgCycleTime" BO_ 2566734339 60000;
BA_ "SingleFrame" BO_ 2566734339 1;
BA_ "GenMsgCycleTime" BO_ 2566734527 60000;
BA_ "SingleFrame" BO_ 2566734527 1;
BA_ "GenMsgCycleTime" BO_ 2566877952 60000;
BA_ "SingleFrame" BO_ 2566877952 1;
BA_ "GenMsgCycleTime" BO_ 2566877955 60000;
BA_ "SingleFrame" BO_ 2566877955 1;
BA_ "GenMsgCycleTime" BO_ 2566878194 60000;
BA_ "SingleFrame" BO_ 2566878194 1;
BA_ "GenMsgCycleTime" BO_ 2566878143 60000;
BA_ "SingleFrame" BO_ 2566878143 1;
BA_ "GenMsgCycleTime" BO_ 2365584902 80;
BA_ "GenMsgSendType" BO_ 2365584902 0;
BA_ "GenMsgCycleTimeFast" BO_ 2365584902 80;
BA_ "SingleFrame" BO_ 2365584902 1;
BA_ "GenMsgCycleTime" BO_ 2566786816 60000;
BA_ "SingleFrame" BO_ 2566786816 1;
BA_ "GenMsgCycleTime" BO_ 2566786819 60000;
BA_ "SingleFrame" BO_ 2566786819 1;
BA_ "GenMsgCycleTime" BO_ 2566787058 60000;
BA_ "SingleFrame" BO_ 2566787058 1;
BA_ "GenMsgCycleTime" BO_ 2566787007 60000;
BA_ "SingleFrame" BO_ 2566787007 1;
BA_ "GenMsgCycleTime" BO_ 2566801152 520;
BA_ "GenMsgSendType" BO_ 2566801152 0;
BA_ "GenMsgCycleTimeFast" BO_ 2566801152 520;
BA_ "SingleFrame" BO_ 2566801152 1;
BA_ "GenMsgCycleTime" BO_ 2566801155 520;
BA_ "GenMsgSendType" BO_ 2566801155 0;
BA_ "GenMsgCycleTimeFast" BO_ 2566801155 520;
BA_ "SingleFrame" BO_ 2566801155 1;
BA_ "GenMsgCycleTime" BO_ 2564423443 60000;
BA_ "SingleFrame" BO_ 2564423443 1;
BA_ "GenMsgCycleTime" BO_ 2564423424 60000;
BA_ "SingleFrame" BO_ 2564423424 1;
BA_ "GenMsgCycleTime" BO_ 2564423427 60000;
BA_ "SingleFrame" BO_ 2564423427 1;
BA_ "GenMsgCycleTime" BO_ 2564423666 60000;
BA_ "SingleFrame" BO_ 2564423666 1;
BA_ "GenMsgCycleTime" BO_ 2564423615 60000;
BA_ "SingleFrame" BO_ 2564423615 1;
BA_ "GenMsgCycleTime" BO_ 2564357907 60000;
BA_ "SingleFrame" BO_ 2564357907 1;
BA_ "GenMsgCycleTime" BO_ 2564357891 60000;
BA_ "SingleFrame" BO_ 2564357891 1;
BA_ "GenMsgCycleTime" BO_ 2564358130 60000;
BA_ "SingleFrame" BO_ 2564358130 1;
BA_ "GenMsgCycleTime" BO_ 2564358079 60000;
BA_ "SingleFrame" BO_ 2564358079 1;
BA_ "GenMsgCycleTime" BO_ 2362179328 60000;
BA_ "SingleFrame" BO_ 2362179328 1;
BA_ "GenMsgCycleTime" BO_ 2362179331 60000;
BA_ "SingleFrame" BO_ 2362179331 1;
BA_ "GenMsgCycleTime" BO_ 2362179570 60000;
BA_ "SingleFrame" BO_ 2362179570 1;
BA_ "GenMsgCycleTime" BO_ 2362179519 60000;
BA_ "SingleFrame" BO_ 2362179519 1;
BA_ "GenMsgCycleTime" BO_ 2566688003 60000;
BA_ "SingleFrame" BO_ 2566688003 1;
BA_ "GenMsgCycleTime" BO_ 2566688191 60000;
BA_ "SingleFrame" BO_ 2566688191 1;
BA_ "GenMsgCycleTime" BO_ 2563374848 60000;
BA_ "SingleFrame" BO_ 2563374848 1;
BA_ "GenMsgCycleTime" BO_ 2563374851 60000;
BA_ "SingleFrame" BO_ 2563374851 1;
BA_ "GenMsgCycleTime" BO_ 2563375090 60000;
BA_ "SingleFrame" BO_ 2563375090 1;
BA_ "GenMsgCycleTime" BO_ 2563375039 60000;
BA_ "SingleFrame" BO_ 2563375039 1;
BA_ "GenMsgCycleTime" BO_ 2563310336 60000;
BA_ "SingleFrame" BO_ 2563310336 1;
BA_ "GenMsgCycleTime" BO_ 2563371520 60000;
BA_ "SingleFrame" BO_ 2563371520 1;
BA_ "GenMsgCycleTime" BO_ 2563358464 60000;
BA_ "SingleFrame" BO_ 2563358464 1;
BA_ "GenMsgCycleTime" BO_ 2563309571 60000;
BA_ "SingleFrame" BO_ 2563309571 1;
BA_ "GenMsgCycleTime" BO_ 2563371523 60000;
BA_ "SingleFrame" BO_ 2563371523 1;
BA_ "GenMsgCycleTime" BO_ 2563358467 60000;
BA_ "SingleFrame" BO_ 2563358467 1;
BA_ "GenMsgCycleTime" BO_ 2563310339 60000;
BA_ "SingleFrame" BO_ 2563310339 1;
BA_ "GenMsgCycleTime" BO_ 2563309810 60000;
BA_ "SingleFrame" BO_ 2563309810 1;
BA_ "GenMsgCycleTime" BO_ 2563310578 60000;
BA_ "SingleFrame" BO_ 2563310578 1;
BA_ "GenMsgCycleTime" BO_ 2563358706 60000;
BA_ "SingleFrame" BO_ 2563358706 1;
BA_ "GenMsgCycleTime" BO_ 2563309759 60000;
BA_ "SingleFrame" BO_ 2563309759 1;
BA_ "GenMsgCycleTime" BO_ 2563310527 60000;
BA_ "SingleFrame" BO_ 2563310527 1;
BA_ "GenMsgCycleTime" BO_ 2563371711 60000;
BA_ "SingleFrame" BO_ 2563371711 1;
BA_ "GenMsgCycleTime" BO_ 2565537555 60000;
BA_ "SingleFrame" BO_ 2565537555 1;
BA_ "GenMsgCycleTime" BO_ 2565537536 60000;
BA_ "SingleFrame" BO_ 2565537536 1;
BA_ "GenMsgCycleTime" BO_ 2565537539 60000;
BA_ "SingleFrame" BO_ 2565537539 1;
BA_ "GenMsgCycleTime" BO_ 2565537778 60000;
BA_ "SingleFrame" BO_ 2565537778 1;
BA_ "GenMsgCycleTime" BO_ 2565537727 60000;
BA_ "SingleFrame" BO_ 2565537727 1;
BA_ "GenMsgCycleTime" BO_ 2358116096 60000;
BA_ "SingleFrame" BO_ 2358116096 1;
BA_ "GenMsgCycleTime" BO_ 2358116099 60000;
BA_ "SingleFrame" BO_ 2358116099 1;
BA_ "GenMsgCycleTime" BO_ 2358116338 60000;
BA_ "SingleFrame" BO_ 2358116338 1;
BA_ "GenMsgCycleTime" BO_ 2358116287 60000;
BA_ "SingleFrame" BO_ 2358116287 1;
BA_ "GenMsgCycleTime" BO_ 2358051584 60000;
BA_ "SingleFrame" BO_ 2358051584 1;
BA_ "GenMsgCycleTime" BO_ 2358112768 60000;
BA_ "SingleFrame" BO_ 2358112768 1;
BA_ "GenMsgCycleTime" BO_ 2358099712 60000;
BA_ "SingleFrame" BO_ 2358099712 1;
BA_ "GenMsgCycleTime" BO_ 2358050819 60000;
BA_ "SingleFrame" BO_ 2358050819 1;
BA_ "GenMsgCycleTime" BO_ 2358112771 60000;
BA_ "SingleFrame" BO_ 2358112771 1;
BA_ "GenMsgCycleTime" BO_ 2358099715 60000;
BA_ "SingleFrame" BO_ 2358099715 1;
BA_ "GenMsgCycleTime" BO_ 2358051058 60000;
BA_ "SingleFrame" BO_ 2358051058 1;
BA_ "GenMsgCycleTime" BO_ 2358051826 60000;
BA_ "SingleFrame" BO_ 2358051826 1;
BA_ "GenMsgCycleTime" BO_ 2358099954 60000;
BA_ "SingleFrame" BO_ 2358099954 1;
BA_ "GenMsgCycleTime" BO_ 2358051007 60000;
BA_ "SingleFrame" BO_ 2358051007 1;
BA_ "GenMsgCycleTime" BO_ 2358051775 60000;
BA_ "SingleFrame" BO_ 2358051775 1;
BA_ "GenMsgCycleTime" BO_ 2358112959 60000;
BA_ "SingleFrame" BO_ 2358112959 1;
BA_ "GenMsgCycleTime" BO_ 2358181632 60000;
BA_ "SingleFrame" BO_ 2358181632 1;
BA_ "GenMsgCycleTime" BO_ 2358181635 60000;
BA_ "SingleFrame" BO_ 2358181635 1;
BA_ "GenMsgCycleTime" BO_ 2358181823 60000;
BA_ "SingleFrame" BO_ 2358181823 1;
BA_ "GenMsgCycleTime" BO_ 2358117120 60000;
BA_ "SingleFrame" BO_ 2358117120 1;
BA_ "GenMsgCycleTime" BO_ 2358165248 60000;
BA_ "SingleFrame" BO_ 2358165248 1;
BA_ "GenMsgCycleTime" BO_ 2358116355 60000;
BA_ "SingleFrame" BO_ 2358116355 1;
BA_ "GenMsgCycleTime" BO_ 2358165251 60000;
BA_ "SingleFrame" BO_ 2358165251 1;
BA_ "GenMsgCycleTime" BO_ 2358116543 60000;
BA_ "SingleFrame" BO_ 2358116543 1;
BA_ "GenMsgCycleTime" BO_ 2358117311 60000;
BA_ "SingleFrame" BO_ 2358117311 1;
BA_ "GenMsgCycleTime" BO_ 2566838784 60000;
BA_ "SingleFrame" BO_ 2566838784 1;
BA_ "GenMsgCycleTime" BO_ 2566838787 60000;
BA_ "SingleFrame" BO_ 2566838787 1;
BA_ "GenMsgCycleTime" BO_ 2566839026 60000;
BA_ "SingleFrame" BO_ 2566839026 1;
BA_ "GenMsgCycleTime" BO_ 2566838975 60000;
BA_ "SingleFrame" BO_ 2566838975 1;
BA_ "GenMsgCycleTime" BO_ 2515538174 1000;
BA_ "GenMsgSendType" BO_ 2515538174 0;
BA_ "GenMsgCycleTimeFast" BO_ 2515538174 1000;
BA_ "SingleFrame" BO_ 2515538174 1;
BA_ "GenMsgCycleTime" BO_ 2348810246 20;
BA_ "SingleFrame" BO_ 2348810246 1;
BA_ "GenMsgCycleTime" BO_ 2632777491 60000;
BA_ "SingleFrame" BO_ 2632777491 1;
BA_ "GenMsgCycleTime" BO_ 2632777472 60000;
BA_ "SingleFrame" BO_ 2632777472 1;
BA_ "GenMsgCycleTime" BO_ 2632777475 60000;
BA_ "SingleFrame" BO_ 2632777475 1;
BA_ "GenMsgCycleTime" BO_ 2632777714 60000;
BA_ "SingleFrame" BO_ 2632777714 1;
BA_ "GenMsgCycleTime" BO_ 2632777663 60000;
BA_ "SingleFrame" BO_ 2632777663 1;
BA_ "GenMsgCycleTime" BO_ 2632711955 60000;
BA_ "SingleFrame" BO_ 2632711955 1;
BA_ "GenMsgCycleTime" BO_ 2632711936 60000;
BA_ "SingleFrame" BO_ 2632711936 1;
BA_ "GenMsgCycleTime" BO_ 2632711939 60000;
BA_ "SingleFrame" BO_ 2632711939 1;
BA_ "GenMsgCycleTime" BO_ 2632712178 60000;
BA_ "SingleFrame" BO_ 2632712178 1;
BA_ "GenMsgCycleTime" BO_ 2632712127 60000;
BA_ "SingleFrame" BO_ 2632712127 1;
BA_ "GenMsgCycleTime" BO_ 2564489235 60000;
BA_ "SingleFrame" BO_ 2564489235 1;
BA_ "GenMsgCycleTime" BO_ 2564490003 60000;
BA_ "SingleFrame" BO_ 2564490003 1;
BA_ "GenMsgCycleTime" BO_ 2564551187 60000;
BA_ "SingleFrame" BO_ 2564551187 1;
BA_ "GenMsgCycleTime" BO_ 2564538131 60000;
BA_ "SingleFrame" BO_ 2564538131 1;
BA_ "GenMsgCycleTime" BO_ 2564494080 60000;
BA_ "SingleFrame" BO_ 2564494080 1;
BA_ "GenMsgCycleTime" BO_ 2564489984 60000;
BA_ "SingleFrame" BO_ 2564489984 1;
BA_ "GenMsgCycleTime" BO_ 2564551168 60000;
BA_ "SingleFrame" BO_ 2564551168 1;
BA_ "GenMsgCycleTime" BO_ 2564538112 60000;
BA_ "SingleFrame" BO_ 2564538112 1;
BA_ "GenMsgCycleTime" BO_ 2564494083 60000;
BA_ "SingleFrame" BO_ 2564494083 1;
BA_ "GenMsgCycleTime" BO_ 2564489219 60000;
BA_ "SingleFrame" BO_ 2564489219 1;
BA_ "GenMsgCycleTime" BO_ 2564551171 60000;
BA_ "SingleFrame" BO_ 2564551171 1;
BA_ "GenMsgCycleTime" BO_ 2564538115 60000;
BA_ "SingleFrame" BO_ 2564538115 1;
BA_ "GenMsgCycleTime" BO_ 2564489987 60000;
BA_ "SingleFrame" BO_ 2564489987 1;
BA_ "GenMsgCycleTime" BO_ 2564494322 60000;
BA_ "SingleFrame" BO_ 2564494322 1;
BA_ "GenMsgCycleTime" BO_ 2564489458 60000;
BA_ "SingleFrame" BO_ 2564489458 1;
BA_ "GenMsgCycleTime" BO_ 2564490226 60000;
BA_ "SingleFrame" BO_ 2564490226 1;
BA_ "GenMsgCycleTime" BO_ 2564538354 60000;
BA_ "SingleFrame" BO_ 2564538354 1;
BA_ "GenMsgCycleTime" BO_ 2564494271 60000;
BA_ "SingleFrame" BO_ 2564494271 1;
BA_ "GenMsgCycleTime" BO_ 2564489407 60000;
BA_ "SingleFrame" BO_ 2564489407 1;
BA_ "GenMsgCycleTime" BO_ 2564490175 60000;
BA_ "SingleFrame" BO_ 2564490175 1;
BA_ "GenMsgCycleTime" BO_ 2564551359 60000;
BA_ "SingleFrame" BO_ 2564551359 1;
BA_ "GenMsgCycleTime" BO_ 2564554515 60000;
BA_ "SingleFrame" BO_ 2564554515 1;
BA_ "GenMsgCycleTime" BO_ 2564554496 60000;
BA_ "SingleFrame" BO_ 2564554496 1;
BA_ "GenMsgCycleTime" BO_ 2564554499 60000;
BA_ "SingleFrame" BO_ 2564554499 1;
BA_ "GenMsgCycleTime" BO_ 2564554738 60000;
BA_ "SingleFrame" BO_ 2564554738 1;
BA_ "GenMsgCycleTime" BO_ 2564554687 60000;
BA_ "SingleFrame" BO_ 2564554687 1;
BA_ "GenMsgCycleTime" BO_ 2564488979 60000;
BA_ "SingleFrame" BO_ 2564488979 1;
BA_ "GenMsgCycleTime" BO_ 2564488960 60000;
BA_ "SingleFrame" BO_ 2564488960 1;
BA_ "GenMsgCycleTime" BO_ 2564488963 60000;
BA_ "SingleFrame" BO_ 2564488963 1;
BA_ "GenMsgCycleTime" BO_ 2564489202 60000;
BA_ "SingleFrame" BO_ 2564489202 1;
BA_ "GenMsgCycleTime" BO_ 2564489151 60000;
BA_ "SingleFrame" BO_ 2564489151 1;
BA_ "GenMsgCycleTime" BO_ 2564423699 60000;
BA_ "SingleFrame" BO_ 2564423699 1;
BA_ "GenMsgCycleTime" BO_ 2564424467 60000;
BA_ "SingleFrame" BO_ 2564424467 1;
BA_ "GenMsgCycleTime" BO_ 2564485651 60000;
BA_ "SingleFrame" BO_ 2564485651 1;
BA_ "GenMsgCycleTime" BO_ 2564472595 60000;
BA_ "SingleFrame" BO_ 2564472595 1;
BA_ "GenMsgCycleTime" BO_ 2564428544 60000;
BA_ "SingleFrame" BO_ 2564428544 1;
BA_ "GenMsgCycleTime" BO_ 2564424448 60000;
BA_ "SingleFrame" BO_ 2564424448 1;
BA_ "GenMsgCycleTime" BO_ 2564485632 60000;
BA_ "SingleFrame" BO_ 2564485632 1;
BA_ "GenMsgCycleTime" BO_ 2564472576 60000;
BA_ "SingleFrame" BO_ 2564472576 1;
BA_ "GenMsgCycleTime" BO_ 2564428547 60000;
BA_ "SingleFrame" BO_ 2564428547 1;
BA_ "GenMsgCycleTime" BO_ 2564423683 60000;
BA_ "SingleFrame" BO_ 2564423683 1;
BA_ "GenMsgCycleTime" BO_ 2564485635 60000;
BA_ "SingleFrame" BO_ 2564485635 1;
BA_ "GenMsgCycleTime" BO_ 2564472579 60000;
BA_ "SingleFrame" BO_ 2564472579 1;
BA_ "GenMsgCycleTime" BO_ 2564424451 60000;
BA_ "SingleFrame" BO_ 2564424451 1;
BA_ "GenMsgCycleTime" BO_ 2564428786 60000;
BA_ "SingleFrame" BO_ 2564428786 1;
BA_ "GenMsgCycleTime" BO_ 2564423922 60000;
BA_ "SingleFrame" BO_ 2564423922 1;
BA_ "GenMsgCycleTime" BO_ 2564424690 60000;
BA_ "SingleFrame" BO_ 2564424690 1;
BA_ "GenMsgCycleTime" BO_ 2564472818 60000;
BA_ "SingleFrame" BO_ 2564472818 1;
BA_ "GenMsgCycleTime" BO_ 2564428735 60000;
BA_ "SingleFrame" BO_ 2564428735 1;
BA_ "GenMsgCycleTime" BO_ 2564423871 60000;
BA_ "SingleFrame" BO_ 2564423871 1;
BA_ "GenMsgCycleTime" BO_ 2564424639 60000;
BA_ "SingleFrame" BO_ 2564424639 1;
BA_ "GenMsgCycleTime" BO_ 2564485823 60000;
BA_ "SingleFrame" BO_ 2564485823 1;
BA_ "GenMsgCycleTime" BO_ 2365516030 200;
BA_ "GenMsgSendType" BO_ 2365516030 0;
BA_ "GenMsgCycleTimeFast" BO_ 2365516030 200;
BA_ "SingleFrame" BO_ 2365516030 1;
BA_ "GenMsgCycleTime" BO_ 2633952256 60000;
BA_ "SingleFrame" BO_ 2633952256 1;
BA_ "GenMsgCycleTime" BO_ 2633952259 60000;
BA_ "SingleFrame" BO_ 2633952259 1;
BA_ "GenMsgCycleTime" BO_ 2633952498 60000;
BA_ "SingleFrame" BO_ 2633952498 1;
BA_ "GenMsgCycleTime" BO_ 2633952447 60000;
BA_ "SingleFrame" BO_ 2633952447 1;
BA_ "GenMsgCycleTime" BO_ 2499700990 1000;
BA_ "GenMsgSendType" BO_ 2499700990 0;
BA_ "GenMsgCycleTimeFast" BO_ 2499700990 1000;
BA_ "SingleFrame" BO_ 2499700990 1;
BA_ "GenMsgCycleTime" BO_ 2632319744 60000;
BA_ "SingleFrame" BO_ 2632319744 1;
BA_ "GenMsgCycleTime" BO_ 2632380928 60000;
BA_ "SingleFrame" BO_ 2632380928 1;
BA_ "GenMsgCycleTime" BO_ 2632367872 60000;
BA_ "SingleFrame" BO_ 2632367872 1;
BA_ "GenMsgCycleTime" BO_ 2632318979 60000;
BA_ "SingleFrame" BO_ 2632318979 1;
BA_ "GenMsgCycleTime" BO_ 2632380931 60000;
BA_ "SingleFrame" BO_ 2632380931 1;
BA_ "GenMsgCycleTime" BO_ 2632367875 60000;
BA_ "SingleFrame" BO_ 2632367875 1;
BA_ "GenMsgCycleTime" BO_ 2632319218 60000;
BA_ "SingleFrame" BO_ 2632319218 1;
BA_ "GenMsgCycleTime" BO_ 2632319986 60000;
BA_ "SingleFrame" BO_ 2632319986 1;
BA_ "GenMsgCycleTime" BO_ 2632368114 60000;
BA_ "SingleFrame" BO_ 2632368114 1;
BA_ "GenMsgCycleTime" BO_ 2632319167 60000;
BA_ "SingleFrame" BO_ 2632319167 1;
BA_ "GenMsgCycleTime" BO_ 2632319935 60000;
BA_ "SingleFrame" BO_ 2632319935 1;
BA_ "GenMsgCycleTime" BO_ 2632381119 60000;
BA_ "SingleFrame" BO_ 2632381119 1;
BA_ "GenMsgCycleTime" BO_ 2632384256 60000;
BA_ "SingleFrame" BO_ 2632384256 1;
BA_ "GenMsgCycleTime" BO_ 2632384259 60000;
BA_ "SingleFrame" BO_ 2632384259 1;
BA_ "GenMsgCycleTime" BO_ 2632384498 60000;
BA_ "SingleFrame" BO_ 2632384498 1;
BA_ "GenMsgCycleTime" BO_ 2632384447 60000;
BA_ "SingleFrame" BO_ 2632384447 1;
BA_ "GenMsgCycleTime" BO_ 2365475070 120;
BA_ "GenMsgSendType" BO_ 2365475070 0;
BA_ "GenMsgCycleTimeFast" BO_ 2365475070 120;
BA_ "SingleFrame" BO_ 2365475070 1;
BA_ "GenMsgCycleTime" BO_ 2566786304 60000;
BA_ "SingleFrame" BO_ 2566786304 1;
BA_ "GenMsgCycleTime" BO_ 2566786307 60000;
BA_ "SingleFrame" BO_ 2566786307 1;
BA_ "GenMsgCycleTime" BO_ 2566786495 60000;
BA_ "SingleFrame" BO_ 2566786495 1;
BA_ "GenMsgCycleTime" BO_ 2566786048 60000;
BA_ "SingleFrame" BO_ 2566786048 1;
BA_ "GenMsgCycleTime" BO_ 2566786051 60000;
BA_ "SingleFrame" BO_ 2566786051 1;
BA_ "GenMsgCycleTime" BO_ 2566786290 60000;
BA_ "SingleFrame" BO_ 2566786290 1;
BA_ "GenMsgCycleTime" BO_ 2566786239 60000;
BA_ "SingleFrame" BO_ 2566786239 1;
BA_ "GenMsgCycleTime" BO_ 2559377155 60000;
BA_ "SingleFrame" BO_ 2559377155 1;
BA_ "GenMsgCycleTime" BO_ 2559311619 60000;
BA_ "SingleFrame" BO_ 2559311619 1;
BA_ "GenMsgCycleTime" BO_ 2559311807 60000;
BA_ "SingleFrame" BO_ 2559311807 1;
BA_ "GenMsgCycleTime" BO_ 2559360771 60000;
BA_ "SingleFrame" BO_ 2559360771 1;
BA_ "GenMsgCycleTime" BO_ 2559312643 60000;
BA_ "SingleFrame" BO_ 2559312643 1;
BA_ "GenMsgCycleTime" BO_ 2559247107 60000;
BA_ "SingleFrame" BO_ 2559247107 1;
BA_ "GenMsgCycleTime" BO_ 2559247295 60000;
BA_ "SingleFrame" BO_ 2559247295 1;
BA_ "GenMsgCycleTime" BO_ 2566912512 1000;
BA_ "GenMsgSendType" BO_ 2566912512 0;
BA_ "GenMsgCycleTimeFast" BO_ 2566912512 1000;
BA_ "SingleFrame" BO_ 2566912512 1;
BA_ "GenMsgCycleTime" BO_ 2634021376 1000;
BA_ "GenMsgSendType" BO_ 2634021376 0;
BA_ "GenMsgCycleTimeFast" BO_ 2634021376 1000;
BA_ "SingleFrame" BO_ 2634021376 1;
BA_ "GenMsgCycleTime" BO_ 2365587219 1000;
BA_ "GenMsgSendType" BO_ 2365587219 0;
BA_ "GenMsgCycleTimeFast" BO_ 2365587219 1000;
BA_ "SingleFrame" BO_ 2365587219 1;
BA_ "GenMsgCycleTime" BO_ 2499805170 1000;
BA_ "GenMsgSendType" BO_ 2499805170 0;
BA_ "GenMsgCycleTimeFast" BO_ 2499805170 1000;
BA_ "SingleFrame" BO_ 2499805170 1;
BA_ "GenMsgCycleTime" BO_ 2634020864 1000;
BA_ "GenMsgSendType" BO_ 2634020864 0;
BA_ "GenMsgCycleTimeFast" BO_ 2634020864 1000;
BA_ "SingleFrame" BO_ 2634020864 1;
BA_ "GenMsgCycleTime" BO_ 2566910995 100;
BA_ "GenMsgSendType" BO_ 2566910995 0;
BA_ "GenMsgCycleTimeFast" BO_ 2566910995 100;
BA_ "SingleFrame" BO_ 2566910995 1;
BA_ "GenMsgCycleTime" BO_ 2365584382 40;
BA_ "GenMsgSendType" BO_ 2365584382 0;
BA_ "GenMsgCycleTimeFast" BO_ 2365584382 40;
BA_ "SingleFrame" BO_ 2365584382 1;
BA_ "GenMsgCycleTime" BO_ 2566913539 60000;
BA_ "SingleFrame" BO_ 2566913539 1;
BA_ "GenMsgCycleTime" BO_ 2566913778 60000;
BA_ "SingleFrame" BO_ 2566913778 1;
BA_ "GenMsgCycleTime" BO_ 2566913727 60000;
BA_ "SingleFrame" BO_ 2566913727 1;
BA_ "GenMsgCycleTime" BO_ 2632909571 60000;
BA_ "SingleFrame" BO_ 2632909571 1;
BA_ "NmStationAddress" BU_ ATX 19;
BA_ "NmJ1939IndustryGroup" BU_ ATX 2;
BA_ "NmJ1939Function" BU_ ATX 16;
BA_ "NmJ1939ManufacturerCode" BU_ ATX 33;
BA_ "NmJ1939IdentityNumber" BU_ ATX 19811;
BA_ "ECU" BU_ ATX "A26___AutoTrac";
BA_ "NmStationAddress" BU_ ECU 0;
BA_ "NmJ1939IndustryGroup" BU_ ECU 2;
BA_ "NmJ1939System" BU_ ECU 7;
BA_ "NmJ1939ManufacturerCode" BU_ ECU 33;
BA_ "NmJ1939IdentityNumber" BU_ ECU 19;
BA_ "ECU" BU_ ECU "A5505___ECU";
BA_ "NmStationAddress" BU_ EIC 6;
BA_ "NmJ1939IndustryGroup" BU_ EIC 2;
BA_ "NmJ1939Function" BU_ EIC 14;
BA_ "NmJ1939ManufacturerCode" BU_ EIC 33;
BA_ "NmJ1939IdentityNumber" BU_ EIC 6110;
BA_ "ECU" BU_ EIC "A68_PODC";
BA_ "NmStationAddress" BU_ PBS 3;
BA_ "NmJ1939IndustryGroup" BU_ PBS 2;
BA_ "NmJ1939System" BU_ PBS 7;
BA_ "NmJ1939Function" BU_ PBS 3;
BA_ "NmJ1939ManufacturerCode" BU_ PBS 33;
BA_ "NmJ1939IdentityNumber" BU_ PBS 3133;
BA_ "ECU" BU_ PBS "A37_PBS";
BA_ "NmStationAddress" BU_ PDC 242;
BA_ "NmJ1939IndustryGroup" BU_ PDC 2;
BA_ "NmJ1939System" BU_ PDC 7;
BA_ "NmJ1939Function" BU_ PDC 79;
BA_ "NmJ1939FunctionInstance" BU_ PDC 1;
BA_ "NmJ1939ManufacturerCode" BU_ PDC 33;
BA_ "NmJ1939IdentityNumber" BU_ PDC 242134;
BA_ "ECU" BU_ PDC "A68_PODC";
BA_ "NmStationAddress" BU_ PDE 191;
BA_ "NmJ1939AAC" BU_ PDE 1;
BA_ "NmJ1939IndustryGroup" BU_ PDE 2;
BA_ "NmJ1939System" BU_ PDE 7;
BA_ "NmJ1939Function" BU_ PDE 79;
BA_ "NmJ1939ECUInstance" BU_ PDE 1;
BA_ "NmJ1939ManufacturerCode" BU_ PDE 33;
BA_ "NmJ1939IdentityNumber" BU_ PDE 191135;
BA_ "ECU" BU_ PDE "PODE";
BA_ "NmStationAddress" BU_ PTP 3;
BA_ "NmJ1939IndustryGroup" BU_ PTP 2;
BA_ "NmJ1939System" BU_ PTP 7;
BA_ "NmJ1939Function" BU_ PTP 3;
BA_ "NmJ1939ManufacturerCode" BU_ PTP 33;
BA_ "NmJ1939IdentityNumber" BU_ PTP 3138;
BA_ "ECU" BU_ PTP "A37___PTP";
BA_ "DBName"   "PodB1";
BA_ "SAE_J1939_75_SpecVersion"   "2022-05";
BA_ "SAE_J1939_21_SpecVersion"   "2022-05";
BA_ "SAE_J1939_73_SpecVersion"   "2022-05";
BA_ "SAE_J1939_71_SpecVersion"   "2022-05";
VAL_ 2566757120 AftrtrtmntDEFProp 0 " Urea concentration too high" 1 " Urea concentration too low" 2 " Fluid is diesel" 3 " Diesel exhaust fluid is proper mixture" 13 " Not able to determine diesel exhaust fluid property fluid type unknown" 14 " Error" 15 " Not Available" ;
VAL_ 2566804992 AftrtrtmntDEFTankLoLvlInd 0 " OFF" 1 " ON_Solid" 4 " ON_FastBlink_1Hz" 6 " Reserved" 7 " Error" ;
VAL_ 2566804992 AftrtrtmntSCROptrIndcmntSevrty 0 " No inducement active" 1 " Inducement level 1" 2 " Inducement level 2" 3 " Inducement level 3" 4 " Inducement level 4" 5 " Inducement level 5" 6 " Error" 7 " Not Available" ;
VAL_ 2298409219 BrakeSwitch 0 " Released" 1 " Depressed" 2 " Error" 3 " NotAvailable" ;
VAL_ 2566749184 DieselPartFltrState 0 " EATRLNotNeeded" 1 " EATRLLevel1" 2 " EATRLLevel2" 3 " EATRLLevel3" 4 " EATRLLevel4" 5 " EATRLLevel5" ;
VAL_ 2566749184 CANExhstSysHighTempLmpCmd 0 " Off" 1 " On__Solid" 6 " RsrvdStds" 7 " NoAction" ;
VAL_ 2566749184 DiesPartFltrActvRegeFrcdStat 0 " DEM_Not_active" 1 " DEM_Active__Forced_by_switch" 2 " DEM_Active__Forced_by_Service_tool" 6 " DEM_RsrvdStds" 7 " DEM_Dont_caretake_no_action" ;
VAL_ 2364539904 EngineTorqueMode 0 " Low idle governor no request default mode" 1 " Accelerator Pedal" 2 " Cruise Control" 3 " PTO Governor" 4 " Road Speed Governing" 5 " ASR Control" 6 " Transmission Control" 7 " ABS Conrol" 8 " Torque Limiting" 9 " High Speed Governor" 10 " Brake System Electronic" 11 " Remote Accelerator" 14 " Other" 12 " Not defined 1" 13 " Not defined 2" 15 " Not available" ;
VAL_ 2364539904 EngStarterMode 0 " Start not requested" 1 " Starter not active gear not engaged" 2 " Starter active gear engaged" 3 " Start finished starter not active after having been actively engaged after 50ms mode goes to 0000" 4 " Starter inhibited due to engine already running" 5 " Starter inhibited due to engine not ready for start preheating" 6 " Starter inhibited due to driveline engaged or other transmission inhibit" 7 " Starter inhibited due to active immobilizer" 8 " Start inhibited due to starter over temp" 12 " Starter inhibited reason unknown" 13 " Error legacy implementation only use 1110 instead" 14 " Error" 15 " Not available" ;
VAL_ 2364539648 AccelPedalLoIdleSw 0 " Not in low idle condition" 1 " In low idle condition" 2 " Error" 3 " Not_available_or_ not_installed" ;
VAL_ 2364539648 AccelPedalKckdownSw 0 " Kickdown passive" 1 " Kickdown active" 2 " Error" 3 " Not available or not installed" ;
VAL_ 2364539648 RoadSpdLimState 0 " DEM_Not_active" 1 " DEM_Active" 2 " DEM_Error" 3 " DEM_Not_availablenot_installed" ;
VAL_ 2364539648 AccelPedal2LoIdleSw 0 " Not in low idle condition" 1 " In low idle condition" 2 " Error" 3 " Not available or not installed" ;
VAL_ 2364539648 VehAccelRateLimState 0 " DEM_Not_active" 1 " DEM_Active" 2 " DEM_Error" 3 " DEM_Not_availablenot_installed" ;
VAL_ 2364539648 MomEngMaxPwrEnblFdbk 0 " Disabled" 1 " Supported" 2 " Error" 3 " Not Available" ;
VAL_ 2364539648 DPFThrmlMngmntActive 0 " DEM_Not_active" 1 " DEM_Active" 2 " Rsrvd_Stds" 3 " DEM_Not_availablenot_installed" ;
VAL_ 2364539648 SCRThrmlMngmntActv 0 " DEM_Not_active" 1 " DEM_Active" 2 " Rsrvd_Stds" 3 " DEM_Not_availablenot_installed" ;
VAL_ 2566840064 AftertreatmentIntakeDewPnt 0 " Not Exceeded" 1 " Exceeded" 2 " Error" 3 " Not Available" ;
VAL_ 2566840064 AftertreatmentExhaustDewPnt 0 " Not Exceeded" 1 " Exceeded" 2 " Error" 3 " Not Available" ;
VAL_ 2566840064 Aftertreatment2IntakeDewPnt 0 " Not Exceeded" 1 " Exceeded" 2 " Error" 3 " Not Available" ;
VAL_ 2566840064 Aftertreatment2ExhDewPnt 0 " Not Exceeded" 1 " Exceeded" 2 " Error" 3 " Not Available" ;
VAL_ 2432537342 EngOpState 0 " DEM_Engine_Stopped" 1 " DEM_PreStart" 2 " DEM_Starting" 3 " DEM_WarmUp" 4 " DEM_Running" 5 " DEM_Cooldown" 6 " DEM_Engine_Stopping" 7 " DEM_PostRun" 14 " DEM_RsrvdStds" 15 " DEM_Dont_caretake_no_action" ;
VAL_ 2431708670 EngineStartRequest 0 " Start not requested" 1 " Start requested operator type" 2 " Start requested automatic type" 3 " Not available" ;
VAL_ 2360147731 MechSysLockout 0 " EnTwoStNo" 1 " EnTwoStYes" 2 " EnTwoStErr" 3 " EnTwoStNotAvl" ;
VAL_ 2360147731 StrgSysReadiness 0 " EnTwoStNo" 1 " EnTwoStYes" 2 " EnTwoStErr" 3 " EnTwoStNotAvl" ;
VAL_ 2360147731 StrgInputPstnState 0 " EnTwoStNo" 1 " EnTwoStYes" 2 " EnTwoStErr" 3 " EnTwoStNotAvl" ;
VAL_ 2360147731 ReqResetCmdState 0 " EnTwoStNo" 1 " EnTwoStYes" 2 " EnTwoStErr" 3 " EnTwoStNotAvl" ;
VAL_ 2360147731 GuideLimState 0 " EnNavLimStNotLimd" 1 " EnNavLimStOpertLimd" 2 " EnNavLimStLimdHi" 3 " EnNavLimStLimdLo" 6 " EnNavLimStErr" 7 " EnNavLimStUkwn" ;
VAL_ 2360147731 GuideSysCmdExitRsnCode 0 " ATECNoCode" 1 " ATECTransmissionInPark" 2 " ATECFICAFault" 3 " ATECWhlSpdSlow" 4 " ATECAltGuidanceActive" 5 " ATECIncorrectGear" 13 " ATECCmdMsdTimeout" 250 " ATECLastTransitionOk" 16 " ATECAuthDenied" 21 " ATECWhlSpdFast" 22 " ATECOilTempTooLow" 23 " ATECDiagMode" 24 " ATECCtrlState" 25 " ATECResumeNotPressed" 26 " ATECCurvatureNotMatched" 50 " ATECInvalidCommand" 51 " ATECNoOperatorPresence" 52 " ATECImpReleasedControl" 53 " ATECGlobalStop" 54 " ATECOperatorOverride" 62 " ATECECError" 63 " ATECECNotAvailable" 64 " ATECStartUp" 65 " ATECShutDown" 66 " ATECAutoTracShutdown" 67 " ATECEngineOff" 68 " ATECNotCalibrated" 69 " ATECVoltagenotStable" 70 " ATECOperatorPresenceDataBad" 71 " ATECResumeSwitchDataBad" 72 " ATECVehStateMsgMissing" 73 " ATECVehStateMsgBadData" 74 " ATECAdvGuidanceStatusMsgMissing" 75 " ATECAdvGuidanceStatusMsgBadData" 76 " ATECActiveInReverseTimeout" 77 " ATECGPSWheelSpeedMismatch" 78 " ATECNoValidTrack" 79 " ATECInvalidGPS" 80 " ATECShutdownStateFaulted" 81 " ATECGSDDataFaulted" 82 " ATECExtGuidanceStatusMsgFaulted" 83 " ATECExtGuidanceStatusExtendedMsgFaulted" 84 " ATECVehDirSpeedMsgFaulted" 85 " ATECVehRollYawMsgFaulted" 86 " ATECTCMMsgFaulted" 87 " ATECLateralError" 88 " ATECHeadingError" 89 " ATECTrackNumChanged" 90 " ATECTCMInactive" 91 " ATECRSGPSTransitionTooLarge" 92 " ATECRSOutOfRow" 93 " ATECRSGreenstarTrackingFault" 94 " ATECRSSensorFault" 95 " ATECRSGPSFault" 100 " ATECTransportMode" 101 " ATECAuxPumpOn" 102 " ATECBoomsFolded" 103 " ATECHeaderNotEngaged" 104 " ATECFourWheelSteerTimeout" 105 " ATECCrabSteering" 254 " ATECEC8BitError" 255 " ATECEC8BitNotAvailable" ;
VAL_ 2360213502 CurvatureCmdState 0 " EnCrvtCmdStNotIntdToSteer" 1 " EnCrvtCmdStIntdToSteer" 2 " EnCrvtCmdStErr" 3 " EnCrvtCmdStNoActn" ;
VAL_ 2365529086 SAS_Mask 0 " SASKostalUnavailable" 1 " SASKostalAvailable" ;
VAL_ 2365529086 SAS_SensorType 0 " SASTypeKostalInvalid_Typ1" 1 " SASTypeKostalInvalid_Typ0" 2 " SASTypeKostalInvalid_Typ2" 3 " SASTypeKostalValid" ;
VAL_ 2365529086 SAS_CalibrationStatus 0 " SASKostalCalibrationStatusValid" 1 " SASKostalCalibrationStatusInvalid_1" 2 " SASKostalCalibrationStatusInvalid_2" 3 " SASKostalCalibrationStatusInvalid_3" ;
VAL_ 2365529086 SAS_DataIsValid 0 " SASKostalDataInvalid" 1 " SASKostalDataValid" ;
VAL_ 2566801152 MaintainECUPower 0 " DEM_Off" 1 " DEM_On" 2 " DEM_Error" 3 " DEM_Not_available_or_not_installed" ;
VAL_ 2566801155 MaintainActuatorPower 0 " DEM_Off" 1 " DEM_On" 2 " DEM_Error" 3 " DEM_Not_available_or_not_installed" ;
VAL_ 2566801155 MaintainECUPower 0 " DEM_Off" 1 " DEM_On" 2 " DEM_Error" 3 " DEM_Not_available_or_not_installed" ;
VAL_ 2566801155 ImplementWorkState 0 " Disengaged" 1 " Engaged" 2 " Error" 3 " NotAvailable" ;
VAL_ 2566801155 ImplementParkState 0 " CannotDisconnect" 1 " DisconnectReady" 2 " Error" 3 " NotAvailable" ;
VAL_ 2566801155 ImplementTransportState 0 " NotTrasportReady" 1 " TrasportReady" 2 " Error" 3 " NotAvailable" ;
VAL_ 2515538174 TimeSource_SDC 0 " GPS" 1 " GLONASS" 2 " WWV or Radio Station" 3 " Local Cesium Clock" 4 " Local Rubidium Clock" 5 " Local Crystal Clock" 15 " Null" ;
VAL_ 2348810246 OverrideECUControlMode 0 " Disabled" 1 " SpeedControl" 2 " TorqueControl" 3 " SpeedAndOrTorqueLimitControl" ;
VAL_ 2348810246 ReqEngineSpeedControl 0 " TransientOptimizedForDisengagedAndNonLockupConditions" 1 " StabilityOptimizedForDisengagedAndNonLockupConditions" 2 " StabilityOptimizedEngagedAndOrInLockupCondition1" 3 " StabilityOptimizedEngagedAndOrInLockupCondition2" ;
VAL_ 2348810246 OverrideECUControlPriority 0 " HighestPriority" 1 " HighPriority" 2 " MediumPriority" 3 " LowPriority" ;
VAL_ 2566912512 CmdBytePGN65530_ECU 329 "AcceleratedDOCSCRTemperatures " 585 "AcceleratedDPFSCROutletNOx " 20483 "AirSystemObserverCorrectionFactors1 " 20739 "AirSystemObserverPlausibility1 " 20995 "AirSystemObserverPlausibility2 " 11266 "EngineDPFRegenerationState " 21507 "EngineTemperaturesAndPressures " 17409 "MTGAftertreatmentControl1 " 17153 "MTGEngineConsumptionAndOperation " ;
VAL_ 2566912512 EngDPFRegenState 0 " DEM_DPF_Regeneration_Inactive" 1 " DEM_Normal_Regeneration_in_Progress" 2 " DEM_Deep_Clean_in_Progress" 3 " DEM_DPF_Regeneration_Aborted" 4 " DEM_Reserved__next_one" 14 " DEM_Error" 15 " DEM_Not_availablenot_installed" ;
VAL_ 2634021376 CmdBytePGN65530_ECU 22019 "ActuatorAirModes " 21763 "AirSystemStates " 22275 "AirSystemObserverCorrectionFactors2 " 21251 "AirSystemObserverCorrectionFactors3 " 20480 "JD_Engine_Control_Message_#18 " ;
VAL_ 2365587219 CmdBytePGN65535_ATX 147 "Advanced_Guidance_Status_Response " ;
VAL_ 2365587219 AutoTracSysCtlrUnlimitRevCapable 0 " EnTwoStNo" 1 " EnTwoStYes" 2 " EnTwoStErr" 3 " EnTwoStNotAvl" ;
VAL_ 2365587219 AuxResuCap 0 " EnTwoStNo" 1 " EnTwoStYes" 2 " EnTwoStErr" 3 " EnTwoStNotAvl" ;
VAL_ 2365587219 WASType 0 " MacCrvtSnsrTypExternal" 1 " MacCrvtSnsrTyp90DegDualPWM" 2 " MacCrvtSnsrTyp120DegDualPWM" 3 " MacCrvtSnsrTyp180DegDualPWM" 4 " MacCrvtSnsrTyp240DegDualPWM" 5 " MacCrvtSnsrTyp90DegDualAn" 6 " MacCrvtSnsrTyp120DegDualAn" 7 " MacCrvtSnsrTyp180DegDualAn" 8 " MacCrvtSnsrTyp240DegDualAn" 9 " MacCrvtSnsrTypATCMotEncder" 10 " MacCrvtSnsrTyp135DegDualAn" 11 " MacCrvtSnsrTyp139DegDualAn" 14 " MacCrvtSnsrTypErr" 15 " MacCrvtSnsrTypUkwn" ;
VAL_ 2365587219 ConfigMachineClass 0 " MacClassDefault" 1 " MacClassTractorRowCrop" 2 " MacClassArticulated" 3 " MacClassTractor2Tracks" 4 " MacClassCombine" 5 " MacClassCotton" 6 " MacClassSPFH" 7 " MacClassSugarcane" 8 " MacClassWindrower" 9 " MacClassWetSprayer" 10 " MacClassDrySprayer" 11 " MacClassSpreader" 12 " MacClassUtilityVehicle" ;
VAL_ 2365587219 SIDType 0 " SteerInpDevTypExt" 1 " SteerInpDevTypCANSID" 2 " SteerInpDevTypBEIDualChPWM" 3 " SteerInpDevTypATCFlowSwt" 6 " SteerInpDevTypErr" 7 " SteerInpDevTypUkwn" ;
VAL_ 2365587219 ActuatorType 0 " CM_CanActrTypExtActr" 1 " CM_CanActrTypFEMAVlv" 2 " CM_CanActrTypDanfossVlv" 3 " CM_CanActrTypCANDanfossVlv" 4 " CM_CanActrTypATCMot" 6 " CM_CanActrTypErr" 7 " CM_CanActrTypUkwn" ;
VAL_ 2365587219 StarfireFwdCfg_AGSR 0 " StarFireFwdCfgOff" 1 " StarFireFwdCfgCAN2ToCAN1" 2 " StarFireFwdCfgCAN2ToEth" 3 " StarFireFwdCfgEthToCAN1AndCan2" 6 " StarFireFwdCfgErr" 7 " StarFireFwdCfgUkwn" ;
VAL_ 2499805170 CmdBytePGN65535_PDC 146 "Advanced_Guidance_Status " ;
VAL_ 2499805170 AutoTracSysUnlimitRevCapable 0 " EnTwoStNo" 1 " EnTwoStYes" 2 " EnTwoStErr" 3 " EnTwoStNotAvl" ;
VAL_ 2499805170 AuxResuCapRqst 0 " EnTwoStNo" 1 " EnTwoStYes" 2 " EnTwoStErr" 3 " EnTwoStNotAvl" ;
VAL_ 2499805170 WASTypeInstalled 0 " MacCrvtSnsrTypExternal" 1 " MacCrvtSnsrTyp90DegDualPWM" 2 " MacCrvtSnsrTyp120DegDualPWM" 3 " MacCrvtSnsrTyp180DegDualPWM" 4 " MacCrvtSnsrTyp240DegDualPWM" 5 " MacCrvtSnsrTyp90DegDualAn" 6 " MacCrvtSnsrTyp120DegDualAn" 7 " MacCrvtSnsrTyp180DegDualAn" 8 " MacCrvtSnsrTyp240DegDualAn" 9 " MacCrvtSnsrTypATCMotEncder" 10 " MacCrvtSnsrTyp135DegDualAn" 11 " MacCrvtSnsrTyp139DegDualAn" 14 " MacCrvtSnsrTypErr" 15 " MacCrvtSnsrTypUkwn" ;
VAL_ 2499805170 ActualMachineClass 0 " MacClassDefault" 1 " MacClassTractorRowCrop" 2 " MacClassArticulated" 3 " MacClassTractor2Tracks" 4 " MacClassCombine" 5 " MacClassCotton" 6 " MacClassSPFH" 7 " MacClassSugarcane" 8 " MacClassWindrower" 9 " MacClassWetSprayer" 10 " MacClassDrySprayer" 11 " MacClassSpreader" 12 " MacClassUtilityVehicle" ;
VAL_ 2499805170 SIDTypeRqst 0 " SteerInpDevTypExt" 1 " SteerInpDevTypCANSID" 2 " SteerInpDevTypBEIDualChPWM" 3 " SteerInpDevTypATCFlowSwt" 6 " SteerInpDevTypErr" 7 " SteerInpDevTypUkwn" ;
VAL_ 2499805170 ActuatorTypeRqst 0 " CM_CanActrTypExtActr" 1 " CM_CanActrTypFEMAVlv" 2 " CM_CanActrTypDanfossVlv" 3 " CM_CanActrTypCANDanfossVlv" 4 " CM_CanActrTypATCMot" 6 " CM_CanActrTypErr" 7 " CM_CanActrTypUkwn" ;
VAL_ 2499805170 StarfireFwdCfgRqst 0 " StarFireFwdCfgOff" 1 " StarFireFwdCfgCAN2ToCAN1" 2 " StarFireFwdCfgCAN2ToEth" 3 " StarFireFwdCfgEthToCAN1AndCan2" 6 " StarFireFwdCfgErr" 7 " StarFireFwdCfgUkwn" ;
VAL_ 2634020864 CmdBytePGN65528_ECU 150 "ATNOxCEStatistics " ;
VAL_ 2634020864 SCRNOXCEMonState 0 " Idle" 1 " Run" 2 " Standby" 3 " NotAvailable" ;
VAL_ 2634020864 SCRAdapConDisable 0 " EnBooleanFalse" 1 " EnBooleanTrue" 2 " EnBooleanError" 3 " EnBooleanNotAvailable" ;
VAL_ 2566910995 CmdBytePGN65524_ATX 95 "AutoTrac_State_for_Vehicle " 99 "Guidance_Machine_Status_J_D_Extended " ;
VAL_ 2566910995 CrvtrCntrlATState_ATSV 0 " ATPS0" 1 " ATPS1" 2 " ATPS2" 3 " ATPS3" 4 " ATPS4" 14 " ATPSErr" 15 " ATPSUkwn" ;
VAL_ 2566910995 RedSteerWarnLightRequest 0 " EnTwoStNo" 1 " EnTwoStYes" 2 " EnTwoStErr" 3 " EnTwoStNotAvl" ;
VAL_ 2566910995 AT2ExitCode_GMSJDE 0 " ATECNoCode" 1 " ATECTransmissionInPark" 2 " ATECFICAFault" 3 " ATECWhlSpdSlow" 4 " ATECAltGuidanceActive" 5 " ATECIncorrectGear" 13 " ATECCmdMsdTimeout" 250 " ATECLastTransitionOk" 16 " ATECAuthDenied" 21 " ATECWhlSpdFast" 22 " ATECOilTempTooLow" 23 " ATECDiagMode" 24 " ATECCtrlState" 25 " ATECResumeNotPressed" 26 " ATECCurvatureNotMatched" 50 " ATECInvalidCommand" 51 " ATECNoOperatorPresence" 52 " ATECImpReleasedControl" 53 " ATECGlobalStop" 54 " ATECOperatorOverride" 62 " ATECECError" 63 " ATECECNotAvailable" 64 " ATECStartUp" 65 " ATECShutDown" 66 " ATECAutoTracShutdown" 67 " ATECEngineOff" 68 " ATECNotCalibrated" 69 " ATECVoltagenotStable" 70 " ATECOperatorPresenceDataBad" 71 " ATECResumeSwitchDataBad" 72 " ATECVehStateMsgMissing" 73 " ATECVehStateMsgBadData" 74 " ATECAdvGuidanceStatusMsgMissing" 75 " ATECAdvGuidanceStatusMsgBadData" 76 " ATECActiveInReverseTimeout" 77 " ATECGPSWheelSpeedMismatch" 78 " ATECNoValidTrack" 79 " ATECInvalidGPS" 80 " ATECShutdownStateFaulted" 81 " ATECGSDDataFaulted" 82 " ATECExtGuidanceStatusMsgFaulted" 83 " ATECExtGuidanceStatusExtendedMsgFaulted" 84 " ATECVehDirSpeedMsgFaulted" 85 " ATECVehRollYawMsgFaulted" 86 " ATECTCMMsgFaulted" 87 " ATECLateralError" 88 " ATECHeadingError" 89 " ATECTrackNumChanged" 90 " ATECTCMInactive" 91 " ATECRSGPSTransitionTooLarge" 92 " ATECRSOutOfRow" 93 " ATECRSGreenstarTrackingFault" 94 " ATECRSSensorFault" 95 " ATECRSGPSFault" 100 " ATECTransportMode" 101 " ATECAuxPumpOn" 102 " ATECBoomsFolded" 103 " ATECHeaderNotEngaged" 104 " ATECFourWheelSteerTimeout" 105 " ATECCrabSteering" 254 " ATECEC8BitError" 255 " ATECEC8BitNotAvailable" ;
VAL_ 2566910995 VehDirection 0 " EnMacDirStp" 1 " EnMacDirRvs" 2 " EnMacDirUnClr" 3 " EnMacDirFwd" 14 " EnMacDirErr" 15 " EnMacDirUkwn" ;
VAL_ 2566910995 AutoTracSystemState 5 " AutoTracSysSt_Actv" 1 " AutoTracSysSt_Disad" 3 " AutoTracSysSt_Enad" 14 " AutoTracSysSt_Err" 0 " AutoTracSysSt_None" 2 " AutoTracSysSt_RdyToEna" 8 " AutoTracSysSt_SrvModActv" 7 " AutoTracSysSt_SrvModEnad" 6 " AutoTracSysSt_SrvModReqd" 4 " AutoTracSysSt_TranToActv" 15 " AutoTracSysSt_Ukwn" ;
VAL_ 2566910995 StarfireFwdCfg_GMSJDE 0 " StarFireFwdCfgOff" 1 " StarFireFwdCfgCAN2ToCAN1" 2 " StarFireFwdCfgCAN2ToEth" 3 " StarFireFwdCfgEthToCAN1AndCan2" 6 " StarFireFwdCfgErr" 7 " StarFireFwdCfgUkwn" ;
VAL_ 2566910995 ActivateGuidanceRequest 0 " No" 1 " Yes" 2 " Error" 3 " NotAvailable" ;
VAL_ 2566910995 AuxiliarySteerMode 0 " ASM2WSFront" 1 " ASM2WSRear" 2 " ASM4WSCoordinated" 3 " ASM4WSCoordinatedLimited" 4 " ASM4WSCrabSteer" 5 " ASM4WSCrabSteerLimited" 6 " ASM4WSIndepdendent" 14 " ASM4BitError" 15 " ASM4BitNotAvailable" ;
VAL_ 2365584382 CmdBytePGN65523_Vector_XXX 49 "ClosedSystemPgnA18JDHWAutoShiftParameters " ;
VAL_ 2365584382 ParkBrakeReq 0 " DEM_Off" 1 " DEM_On" 2 " DEM_Error" 3 " DEM_Not_available_or_not_installed" ;
VAL_ 2365584382 HydHndlState 0 " DEM_Hydro_handle_in_NeutralZero_position" 1 " DEM_Hydro_handle_in_Forward_position" 2 " DEM_Hydro_handle_in_Reverse_position" 3 " DEM_Hydro_handle_in_Center_Position" 6 " DEM_RsrvdStds" 7 " DEM_Dont_caretake_no_action" ;
VAL_ 2566913539 CmdBytePGN65534_PBS 150 "Combine_Network_Health_Data " 151 "Combine_Network_Health_Data_#2 " ;
VAL_ 2566913778 CmdBytePGN65534_PDC 150 "Combine_Network_Health_Data " 151 "Combine_Network_Health_Data_#2 " ;
VAL_ 2566913727 CmdBytePGN65534_PDE 150 "Combine_Network_Health_Data " 151 "Combine_Network_Health_Data_#2 " ;
VAL_ 2632909571 CmdBytePGN61184_PBS 173 "Controller_Data_Message " 173 "Controller_Data_Message " 429 "Controller_Data_Message_0xAD01 " 429 "Controller_Data_Message_0xAD01 " 685 "Controller_Data_Message_0xAD02 " 685 "Controller_Data_Message_0xAD02 " 941 "Controller_Data_Message_0xAD03 " 941 "Controller_Data_Message_0xAD03 " 1197 "Controller_Data_Message_0xAD04 " 1197 "Controller_Data_Message_0xAD04 " 1453 "Controller_Data_Message_0xAD05 " 1453 "Controller_Data_Message_0xAD05 " 1709 "Controller_Data_Message_0xAD06 " 1709 "Controller_Data_Message_0xAD06 " 1965 "Controller_Data_Message_0xAD07 " 1965 "Controller_Data_Message_0xAD07 " 2221 "Controller_Data_Message_0xAD08 " 2221 "Controller_Data_Message_0xAD08 " 2477 "Controller_Data_Message_0xAD09 " 2477 "Controller_Data_Message_0xAD09 " 2733 "Controller_Data_Message_0xAD0A " 2733 "Controller_Data_Message_0xAD0A " 2989 "Controller_Data_Message_0xAD0B " 2989 "Controller_Data_Message_0xAD0B " 3245 "Controller_Data_Message_0xAD0C " 3245 "Controller_Data_Message_0xAD0C " 3501 "Controller_Data_Message_0xAD0D " 3501 "Controller_Data_Message_0xAD0D " 3757 "Controller_Data_Message_0xAD0E " 3757 "Controller_Data_Message_0xAD0E " 4013 "Controller_Data_Message_0xAD0F " 4013 "Controller_Data_Message_0xAD0F " 4269 "Controller_Data_Message_0xAD10 " 4269 "Controller_Data_Message_0xAD10 " 4525 "Controller_Data_Message_0xAD11 " 4525 "Controller_Data_Message_0xAD11 " 4781 "Controller_Data_Message_0xAD12 " 4781 "Controller_Data_Message_0xAD12 " 5037 "Controller_Data_Message_0xAD13 " 5037 "Controller_Data_Message_0xAD13 " 5293 "Controller_Data_Message_0xAD14 " 5293 "Controller_Data_Message_0xAD14 " 5549 "Controller_Data_Message_0xAD15 " 5549 "Controller_Data_Message_0xAD15 " 5805 "Controller_Data_Message_0xAD16 " 5805 "Controller_Data_Message_0xAD16 " 6061 "Controller_Data_Message_0xAD17 " 6061 "Controller_Data_Message_0xAD17 " 6317 "Controller_Data_Message_0xAD18 " 6317 "Controller_Data_Message_0xAD18 " 6573 "Controller_Data_Message_0xAD19 " 6573 "Controller_Data_Message_0xAD19 " 6829 "Controller_Data_Message_0xAD1A " 6829 "Controller_Data_Message_0xAD1A " 7085 "Controller_Data_Message_0xAD1B " 7085 "Controller_Data_Message_0xAD1B " 7341 "Controller_Data_Message_0xAD1C " 7341 "Controller_Data_Message_0xAD1C " 7597 "Controller_Data_Message_0xAD1D " 7597 "Controller_Data_Message_0xAD1D " 7853 "Controller_Data_Message_0xAD1E " 7853 "Controller_Data_Message_0xAD1E " 8109 "Controller_Data_Message_0xAD1F " 8109 "Controller_Data_Message_0xAD1F " 8365 "Controller_Data_Message_0xAD20 " 8365 "Controller_Data_Message_0xAD20 " 8621 "Controller_Data_Message_0xAD21 " 8621 "Controller_Data_Message_0xAD21 " 8877 "Controller_Data_Message_0xAD22 " 8877 "Controller_Data_Message_0xAD22 " 9133 "Controller_Data_Message_0xAD23 " 9133 "Controller_Data_Message_0xAD23 " 9389 "Controller_Data_Message_0xAD24 " 9389 "Controller_Data_Message_0xAD24 " 9645 "Controller_Data_Message_0xAD25 " 9645 "Controller_Data_Message_0xAD25 " 9901 "Controller_Data_Message_0xAD26 " 9901 "Controller_Data_Message_0xAD26 " 10157 "Controller_Data_Message_0xAD27 " 10157 "Controller_Data_Message_0xAD27 " 10413 "Controller_Data_Message_0xAD28 " 10413 "Controller_Data_Message_0xAD28 " 10669 "Controller_Data_Message_0xAD29 " 10669 "Controller_Data_Message_0xAD29 " 10925 "Controller_Data_Message_0xAD2A " 10925 "Controller_Data_Message_0xAD2A " 11181 "Controller_Data_Message_0xAD2B " 11181 "Controller_Data_Message_0xAD2B " 11437 "Controller_Data_Message_0xAD2C " 11437 "Controller_Data_Message_0xAD2C " 11693 "Controller_Data_Message_0xAD2D " 11693 "Controller_Data_Message_0xAD2D " 11949 "Controller_Data_Message_0xAD2E " 11949 "Controller_Data_Message_0xAD2E " 172 "Data_Request_Message " 172 "Data_Request_Message " 428 "Data_Request_Message_0xAC01 " 428 "Data_Request_Message_0xAC01 " 684 "Data_Request_Message_0xAC02 " 684 "Data_Request_Message_0xAC02 " 940 "Data_Request_Message_0xAC03 " 940 "Data_Request_Message_0xAC03 " 1196 "Data_Request_Message_0xAC04 " 1196 "Data_Request_Message_0xAC04 " 1452 "Data_Request_Message_0xAC05 " 1452 "Data_Request_Message_0xAC05 " 1708 "Data_Request_Message_0xAC06 " 1708 "Data_Request_Message_0xAC06 " 1964 "Data_Request_Message_0xAC07 " 1964 "Data_Request_Message_0xAC07 " 2220 "Data_Request_Message_0xAC08 " 2220 "Data_Request_Message_0xAC08 " 2476 "Data_Request_Message_0xAC09 " 2476 "Data_Request_Message_0xAC09 " 2732 "Data_Request_Message_0xAC0A " 2732 "Data_Request_Message_0xAC0A " 2988 "Data_Request_Message_0xAC0B " 2988 "Data_Request_Message_0xAC0B " 3244 "Data_Request_Message_0xAC0C " 3244 "Data_Request_Message_0xAC0C " 3500 "Data_Request_Message_0xAC0D " 3500 "Data_Request_Message_0xAC0D " 3756 "Data_Request_Message_0xAC0E " 3756 "Data_Request_Message_0xAC0E " 4012 "Data_Request_Message_0xAC0F " 4012 "Data_Request_Message_0xAC0F " 4268 "Data_Request_Message_0xAC10 " 4268 "Data_Request_Message_0xAC10 " 4524 "Data_Request_Message_0xAC11 " 4524 "Data_Request_Message_0xAC11 " 4780 "Data_Request_Message_0xAC12 " 4780 "Data_Request_Message_0xAC12 " 5036 "Data_Request_Message_0xAC13 " 5036 "Data_Request_Message_0xAC13 " 5292 "Data_Request_Message_0xAC14 " 5292 "Data_Request_Message_0xAC14 " 5548 "Data_Request_Message_0xAC15 " 5548 "Data_Request_Message_0xAC15 " 5804 "Data_Request_Message_0xAC16 " 5804 "Data_Request_Message_0xAC16 " 6060 "Data_Request_Message_0xAC17 " 6060 "Data_Request_Message_0xAC17 " 6316 "Data_Request_Message_0xAC18 " 6316 "Data_Request_Message_0xAC18 " 6572 "Data_Request_Message_0xAC19 " 6572 "Data_Request_Message_0xAC19 " 6828 "Data_Request_Message_0xAC1A " 6828 "Data_Request_Message_0xAC1A " 7084 "Data_Request_Message_0xAC1B " 7084 "Data_Request_Message_0xAC1B " 7340 "Data_Request_Message_0xAC1C " 7340 "Data_Request_Message_0xAC1C " 7596 "Data_Request_Message_0xAC1D " 7596 "Data_Request_Message_0xAC1D " 7852 "Data_Request_Message_0xAC1E " 7852 "Data_Request_Message_0xAC1E " 8108 "Data_Request_Message_0xAC1F " 8108 "Data_Request_Message_0xAC1F " 8364 "Data_Request_Message_0xAC20 " 8364 "Data_Request_Message_0xAC20 " 8620 "Data_Request_Message_0xAC21 " 8620 "Data_Request_Message_0xAC21 " 8876 "Data_Request_Message_0xAC22 " 8876 "Data_Request_Message_0xAC22 " 9132 "Data_Request_Message_0xAC23 " 9132 "Data_Request_Message_0xAC23 " 9388 "Data_Request_Message_0xAC24 " 9388 "Data_Request_Message_0xAC24 " 9644 "Data_Request_Message_0xAC25 " 9644 "Data_Request_Message_0xAC25 " 9900 "Data_Request_Message_0xAC26 " 9900 "Data_Request_Message_0xAC26 " 10156 "Data_Request_Message_0xAC27 " 10156 "Data_Request_Message_0xAC27 " 10412 "Data_Request_Message_0xAC28 " 10412 "Data_Request_Message_0xAC28 " 10668 "Data_Request_Message_0xAC29 " 10668 "Data_Request_Message_0xAC29 " 10924 "Data_Request_Message_0xAC2A " 10924 "Data_Request_Message_0xAC2A " ;
